VERSION ""

NS_ :

BS_:

BU_: PowertrainControlModule AtmosphericSensor SafetyRestraintSystem2 Aftertreatment_2_GasOutlet Aftertreatment_2_GasIntake DieselParticulateFilterControl Turbocharger SafetyRestraintSystem1 CabDisplay2 Aftertreatment_1_GasOutlet Aftertreatment_1_GasIntake OnBoardDataLogger OffBoardDiagnosticTool2 OffBoardDiagnosticTool1 FileServer ParkingBrakeController SeatController2 FanDriveController SteeringColumnUnit CommunicationUnitRadio CommunicationUnitSatellite CommunicationUnitCellular PropulsionBatteryCharger ChassisController2 ChassisController1 EngineValveControl AuxiliaryHeater2 AuxiliaryHeater1 ClutchUnit RampControl InformationSystem1 SuspensionSystemController2 OilSensor VehicleDynamicStability ExhaustEmissionController TransmissionDisplay2 TransmissionDisplay1 ClimateControl2 WaterPumpController RearAxleSteeringController LightingOperatorControl SeatController1 IgnitionController2 IgnitionController1 TirePressureController CabController2 CabController1 PneumaticSystemController SuspensionSystemController1 HydraulicPumpController EnduranceBrakingSystem RetarderExhaustEngine2 OnBoardDiagnosticUnit HeadwayController RetarderExhaustEngine1 CabDisplay1 ManagementComputer VirtualTerminal OffVehicleGateway PowerTakeOffFront HitchControl AuxiliaryValveControl BodyController TractorTrailerBridge1 StarterSystem ElectricalSystem VehicleSecurity VehicleNavigation AerodynamicControl ElectricalChargingSystem ClimateControl1 TripRecorder InstrumentCluster SuspensionDriveAxle2 SuspensionDriveAxle1 SuspensionSteerAxle SteeringController FuelSystem CruiseControl RetarderDriveline RetarderEngine BrakesDriveAxle2 BrakesDriveAxle1 BrakesSystemController BrakesSteerAxle AxleDrive2 AxleDrive1 AxleSteering PowerTakeOff ShiftConsoleSecondary ShiftConsolePrimary Transmission2 Transmission1 Engine2 Engine1

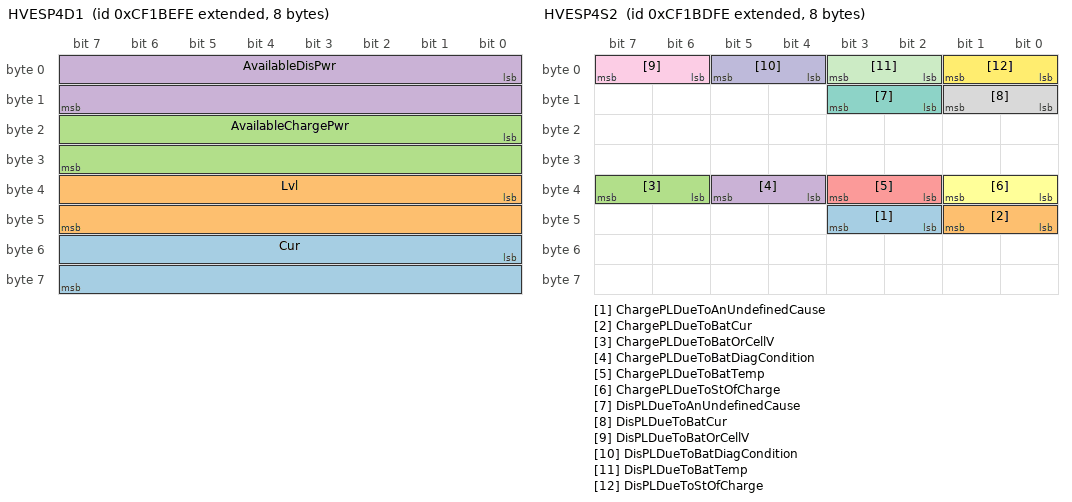
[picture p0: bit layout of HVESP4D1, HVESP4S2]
BO_ 2364653310 HVESP4D1: 8 Vector__XXX
 SG_ Cur : 48|16@1+ (0.05,-1600) [-1600|1612.75] "A" Vector__XXX
 SG_ Lvl : 32|16@1+ (0.05,0) [0|3212.75] "V" Vector__XXX
 SG_ AvailableChargePwr : 16|16@1+ (0.05,0) [0|3212.75] "kW" Vector__XXX
 SG_ AvailableDisPwr : 0|16@1+ (0.05,0) [0|3212.75] "kW" Vector__XXX

BO_ 2364653054 HVESP4S2: 8 Vector__XXX
 SG_ ChargePLDueToAnUndefinedCause : 42|2@1+ (1,0) [0|3] "" Vector__XXX
 SG_ ChargePLDueToBatCur : 40|2@1+ (1,0) [0|3] "" Vector__XXX
 SG_ ChargePLDueToBatOrCellV : 38|2@1+ (1,0) [0|3] "" Vector__XXX
 SG_ ChargePLDueToBatDiagCondition : 36|2@1+ (1,0) [0|3] "" Vector__XXX
 SG_ ChargePLDueToBatTemp : 34|2@1+ (1,0) [0|3] "" Vector__XXX
 SG_ ChargePLDueToStOfCharge : 32|2@1+ (1,0) [0|3] "" Vector__XXX
 SG_ DisPLDueToAnUndefinedCause : 10|2@1+ (1,0) [0|3] "" Vector__XXX
 SG_ DisPLDueToBatCur : 8|2@1+ (1,0) [0|3] "" Vector__XXX
 SG_ DisPLDueToBatOrCellV : 6|2@1+ (1,0) [0|3] "" Vector__XXX
 SG_ DisPLDueToBatDiagCondition : 4|2@1+ (1,0) [0|3] "" Vector__XXX
 SG_ DisPLDueToBatTemp : 2|2@1+ (1,0) [0|3] "" Vector__XXX
 SG_ DisPLDueToStOfCharge : 0|2@1+ (1,0) [0|3] "" Vector__XXX

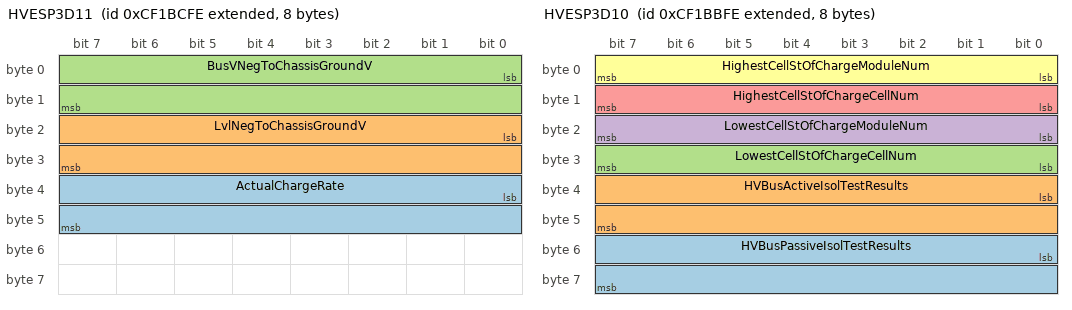
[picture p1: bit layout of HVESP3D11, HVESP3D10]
BO_ 2364652798 HVESP3D11: 8 Vector__XXX
 SG_ ActualChargeRate : 32|16@1+ (0.05,0) [0|3212.75] "kW" Vector__XXX
 SG_ LvlNegToChassisGroundV : 16|16@1+ (0.05,0) [0|3212.75] "V" Vector__XXX
 SG_ BusVNegToChassisGroundV : 0|16@1+ (0.05,0) [0|3212.75] "V" Vector__XXX

BO_ 2364652542 HVESP3D10: 8 Vector__XXX
 SG_ HVBusPassiveIsolTestResults : 48|16@1+ (0.1,0) [0|6425.5] "Ohm/V" Vector__XXX
 SG_ HVBusActiveIsolTestResults : 32|16@1+ (0.1,0) [0|6425.5] "Ohm/V" Vector__XXX
 SG_ LowestCellStOfChargeCellNum : 24|8@1+ (1,0) [0|250] "" Vector__XXX
 SG_ LowestCellStOfChargeModuleNum : 16|8@1+ (1,0) [0|250] "" Vector__XXX
 SG_ HighestCellStOfChargeCellNum : 8|8@1+ (1,0) [0|250] "" Vector__XXX
 SG_ HighestCellStOfChargeModuleNum : 0|8@1+ (1,0) [0|250] "" Vector__XXX

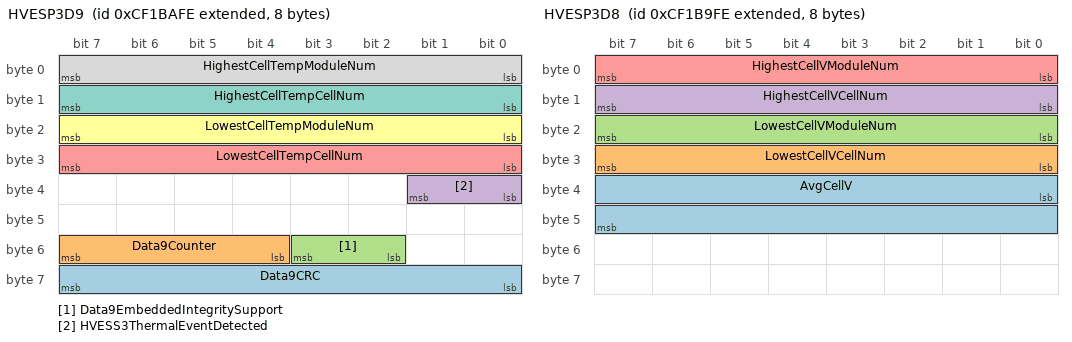
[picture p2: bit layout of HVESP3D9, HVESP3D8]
BO_ 2364652286 HVESP3D9: 8 Vector__XXX
 SG_ Data9CRC : 56|8@1+ (1,0) [0|255] "" Vector__XXX
 SG_ Data9Counter : 52|4@1+ (1,0) [0|15] "" Vector__XXX
 SG_ Data9EmbeddedIntegritySupport : 50|2@1+ (1,0) [0|3] "" Vector__XXX
 SG_ HVESS3ThermalEventDetected : 32|2@1+ (1,0) [0|3] "" Vector__XXX
 SG_ LowestCellTempCellNum : 24|8@1+ (1,0) [0|250] "" Vector__XXX
 SG_ LowestCellTempModuleNum : 16|8@1+ (1,0) [0|250] "" Vector__XXX
 SG_ HighestCellTempCellNum : 8|8@1+ (1,0) [0|250] "" Vector__XXX
 SG_ HighestCellTempModuleNum : 0|8@1+ (1,0) [0|250] "" Vector__XXX

BO_ 2364652030 HVESP3D8: 8 Vector__XXX
 SG_ AvgCellV : 32|16@1+ (0.001,0) [0|64.255] "V" Vector__XXX
 SG_ LowestCellVCellNum : 24|8@1+ (1,0) [0|250] "" Vector__XXX
 SG_ LowestCellVModuleNum : 16|8@1+ (1,0) [0|250] "" Vector__XXX
 SG_ HighestCellVCellNum : 8|8@1+ (1,0) [0|250] "" Vector__XXX
 SG_ HighestCellVModuleNum : 0|8@1+ (1,0) [0|250] "" Vector__XXX

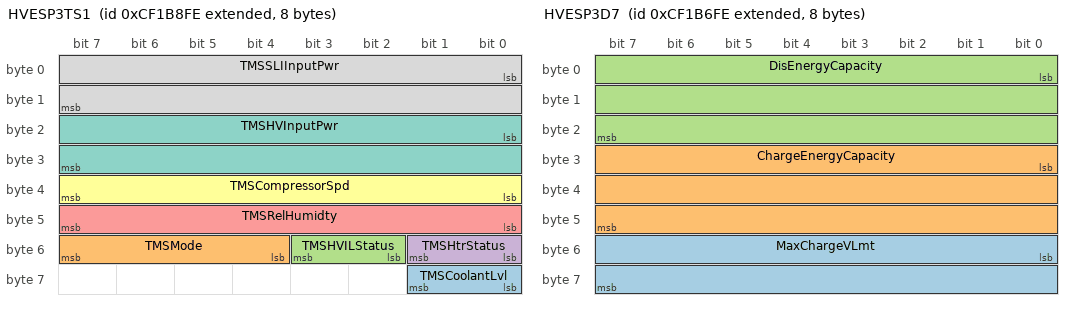
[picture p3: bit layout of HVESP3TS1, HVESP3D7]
BO_ 2364651774 HVESP3TS1: 8 Vector__XXX
 SG_ TMSCoolantLvl : 56|2@1+ (1,0) [0|3] "" Vector__XXX
 SG_ TMSMode : 52|4@1+ (1,0) [0|15] "" Vector__XXX
 SG_ TMSHVILStatus : 50|2@1+ (1,0) [0|3] "" Vector__XXX
 SG_ TMSHtrStatus : 48|2@1+ (1,0) [0|3] "" Vector__XXX
 SG_ TMSRelHumidty : 40|8@1+ (0.4,0) [0|100] "%" Vector__XXX
 SG_ TMSCompressorSpd : 32|8@1+ (32,0) [0|8000] "rpm" Vector__XXX
 SG_ TMSHVInputPwr : 16|16@1+ (0.5,0) [0|32127.5] "W" Vector__XXX
 SG_ TMSSLIInputPwr : 0|16@1+ (0.5,0) [0|32127.5] "W" Vector__XXX

BO_ 2364651518 HVESP3MS1: 8 Vector__XXX
 SG_ Module32OperationalStatus : 62|2@1+ (1,0) [0|3] "" Vector__XXX
 SG_ Module31OperationalStatus : 60|2@1+ (1,0) [0|3] "" Vector__XXX
 SG_ Module30OperationalStatus : 58|2@1+ (1,0) [0|3] "" Vector__XXX
 SG_ Module29OperationalStatus : 56|2@1+ (1,0) [0|3] "" Vector__XXX
 SG_ Module28OperationalStatus : 54|2@1+ (1,0) [0|3] "" Vector__XXX
 SG_ Module27OperationalStatus : 52|2@1+ (1,0) [0|3] "" Vector__XXX
 SG_ Module26OperationalStatus : 50|2@1+ (1,0) [0|3] "" Vector__XXX
 SG_ Module25OperationalStatus : 48|2@1+ (1,0) [0|3] "" Vector__XXX
 SG_ Module24OperationalStatus : 46|2@1+ (1,0) [0|3] "" Vector__XXX
 SG_ Module23OperationalStatus : 44|2@1+ (1,0) [0|3] "" Vector__XXX
 SG_ Module22OperationalStatus : 42|2@1+ (1,0) [0|3] "" Vector__XXX
 SG_ Module21OperationalStatus : 40|2@1+ (1,0) [0|3] "" Vector__XXX
 SG_ Module20OperationalStatus : 38|2@1+ (1,0) [0|3] "" Vector__XXX
 SG_ Module19OperationalStatus : 36|2@1+ (1,0) [0|3] "" Vector__XXX
 SG_ Module18OperationalStatus : 34|2@1+ (1,0) [0|3] "" Vector__XXX
 SG_ Module17OperationalStatus : 32|2@1+ (1,0) [0|3] "" Vector__XXX
 SG_ Module16OperationalStatus : 30|2@1+ (1,0) [0|3] "" Vector__XXX
 SG_ Module15OperationalStatus : 28|2@1+ (1,0) [0|3] "" Vector__XXX
 SG_ Module14OperationalStatus : 26|2@1+ (1,0) [0|3] "" Vector__XXX
 SG_ Module13OperationalStatus : 24|2@1+ (1,0) [0|3] "" Vector__XXX
 SG_ Module12OperationalStatus : 22|2@1+ (1,0) [0|3] "" Vector__XXX
 SG_ Module11OperationalStatus : 20|2@1+ (1,0) [0|3] "" Vector__XXX
 SG_ Module10OperationalStatus : 18|2@1+ (1,0) [0|3] "" Vector__XXX
 SG_ Module9OperationalStatus : 16|2@1+ (1,0) [0|3] "" Vector__XXX
 SG_ Module8OperationalStatus : 14|2@1+ (1,0) [0|3] "" Vector__XXX
 SG_ Module7OperationalStatus : 12|2@1+ (1,0) [0|3] "" Vector__XXX
 SG_ Module6OperationalStatus : 10|2@1+ (1,0) [0|3] "" Vector__XXX
 SG_ Module5OperationalStatus : 8|2@1+ (1,0) [0|3] "" Vector__XXX
 SG_ Module4OperationalStatus : 6|2@1+ (1,0) [0|3] "" Vector__XXX
 SG_ Module3OperationalStatus : 4|2@1+ (1,0) [0|3] "" Vector__XXX
 SG_ Module2OperationalStatus : 2|2@1+ (1,0) [0|3] "" Vector__XXX
 SG_ Module1OperationalStatus : 0|2@1+ (1,0) [0|3] "" Vector__XXX

BO_ 2364651262 HVESP3D7: 8 Vector__XXX
 SG_ MaxChargeVLmt : 48|16@1+ (0.05,0) [0|3212.75] "V" Vector__XXX
 SG_ ChargeEnergyCapacity : 24|24@1+ (0.001,0) [0|16449.535] "kWh" Vector__XXX
 SG_ DisEnergyCapacity : 0|24@1+ (0.001,0) [0|16449.535] "kWh" Vector__XXX

BO_ 2364651006 HVESP3S1: 8 Vector__XXX
 SG_ Status1CRC : 56|8@1+ (1,0) [0|255] "" Vector__XXX
 SG_ Status1Counter : 52|4@1+ (1,0) [0|15] "" Vector__XXX
 SG_ OperationalStatus : 44|4@1+ (1,0) [0|15] "" Vector__XXX
 SG_ HVBusConnectionStatus : 40|4@1+ (1,0) [0|15] "" Vector__XXX
 SG_ InternalChargerStatus : 32|2@1+ (1,0) [0|3] "" Vector__XXX
 SG_ CellBalancingActive : 30|2@1+ (1,0) [0|3] "" Vector__XXX
 SG_ CellBalanceStatus : 28|2@1+ (1,0) [0|3] "" Vector__XXX
 SG_ StOfChargeStatus : 24|4@1+ (1,0) [0|15] "" Vector__XXX
 SG_ InertiaSwStatus : 22|2@1+ (1,0) [0|3] "" Vector__XXX
 SG_ HVILStatus : 20|2@1+ (1,0) [0|3] "" Vector__XXX
 SG_ HVBusPassiveIsolTestStatus : 16|4@1+ (1,0) [0|15] "" Vector__XXX
 SG_ HVBusActiveIsolTestStatus : 12|4@1+ (1,0) [0|15] "" Vector__XXX
 SG_ CenterOfPackContactorSt : 10|2@1+ (1,0) [0|3] "" Vector__XXX
 SG_ HVBusPreChargeRelaySt : 8|2@1+ (1,0) [0|3] "" Vector__XXX
 SG_ HVBusDisconnectForewarning : 4|4@1+ (1,0) [0|15] "" Vector__XXX
 SG_ HVBusContactorSt11308 : 2|2@1+ (1,0) [0|3] "" Vector__XXX
 SG_ HVBusContactorSt : 0|2@1+ (1,0) [0|3] "" Vector__XXX

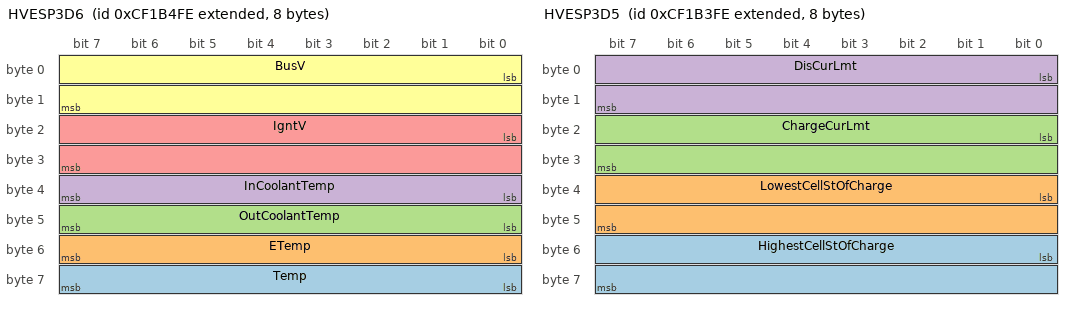
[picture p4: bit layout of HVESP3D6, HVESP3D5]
BO_ 2364650750 HVESP3D6: 8 Vector__XXX
 SG_ Temp : 56|8@1+ (1,-40) [-40|210] "°C" Vector__XXX
 SG_ ETemp : 48|8@1+ (1,-40) [-40|210] "°C" Vector__XXX
 SG_ OutCoolantTemp : 40|8@1+ (1,-40) [-40|210] "°C" Vector__XXX
 SG_ InCoolantTemp : 32|8@1+ (1,-40) [-40|210] "°C" Vector__XXX
 SG_ IgntV : 16|16@1+ (0.01,0) [0|642.55] "V" Vector__XXX
 SG_ BusV : 0|16@1+ (0.05,0) [0|3212.75] "V" Vector__XXX

BO_ 2364650494 HVESP3D5: 8 Vector__XXX
 SG_ HighestCellStOfCharge : 48|16@1+ (0.0015625,0) [0|100.3984375] "%" Vector__XXX
 SG_ LowestCellStOfCharge : 32|16@1+ (0.0015625,0) [0|100.3984375] "%" Vector__XXX
 SG_ ChargeCurLmt : 16|16@1+ (0.05,-1600) [0|1612.75] "A" Vector__XXX
 SG_ DisCurLmt : 0|16@1+ (0.05,-1600) [-1600|0] "A" Vector__XXX

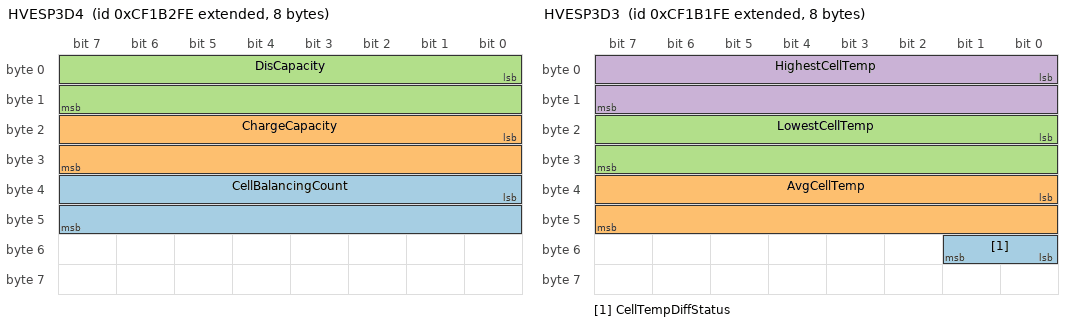
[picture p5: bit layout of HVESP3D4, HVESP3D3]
BO_ 2364650238 HVESP3D4: 8 Vector__XXX
 SG_ CellBalancingCount : 32|16@1+ (1,0) [0|64255] "" Vector__XXX
 SG_ ChargeCapacity : 16|16@1+ (0.01,0) [0|642.55] "Ah" Vector__XXX
 SG_ DisCapacity : 0|16@1+ (0.01,0) [0|642.55] "Ah" Vector__XXX

BO_ 2364649982 HVESP3D3: 8 Vector__XXX
 SG_ CellTempDiffStatus : 48|2@1+ (1,0) [0|3] "" Vector__XXX
 SG_ AvgCellTemp : 32|16@1+ (0.03125,-273) [-273|1734.96875] "°C" Vector__XXX
 SG_ LowestCellTemp : 16|16@1+ (0.03125,-273) [-273|1734.96875] "°C" Vector__XXX
 SG_ HighestCellTemp : 0|16@1+ (0.03125,-273) [-273|1734.96875] "°C" Vector__XXX

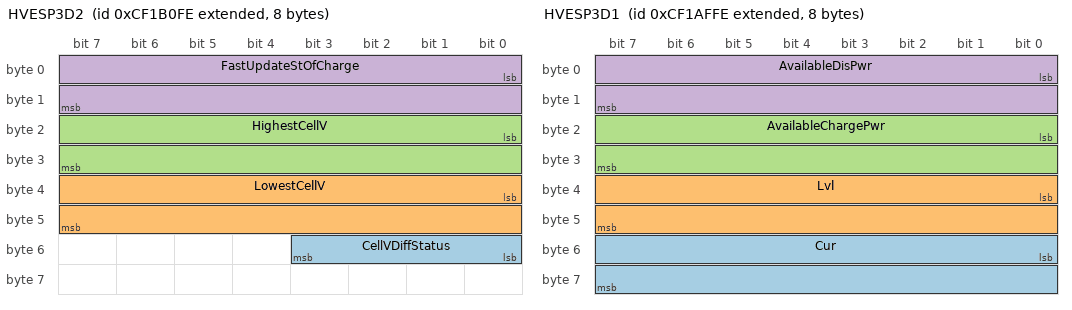
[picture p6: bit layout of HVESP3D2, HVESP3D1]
BO_ 2364649726 HVESP3D2: 8 Vector__XXX
 SG_ CellVDiffStatus : 48|4@1+ (1,0) [0|15] "" Vector__XXX
 SG_ LowestCellV : 32|16@1+ (0.001,0) [0|64.255] "V" Vector__XXX
 SG_ HighestCellV : 16|16@1+ (0.001,0) [0|64.255] "V" Vector__XXX
 SG_ FastUpdateStOfCharge : 0|16@1+ (0.0015625,0) [0|100.3984375] "%" Vector__XXX

BO_ 2364649470 HVESP3D1: 8 Vector__XXX
 SG_ Cur : 48|16@1+ (0.05,-1600) [-1600|1612.75] "A" Vector__XXX
 SG_ Lvl : 32|16@1+ (0.05,0) [0|3212.75] "V" Vector__XXX
 SG_ AvailableChargePwr : 16|16@1+ (0.05,0) [0|3212.75] "kW" Vector__XXX
 SG_ AvailableDisPwr : 0|16@1+ (0.05,0) [0|3212.75] "kW" Vector__XXX

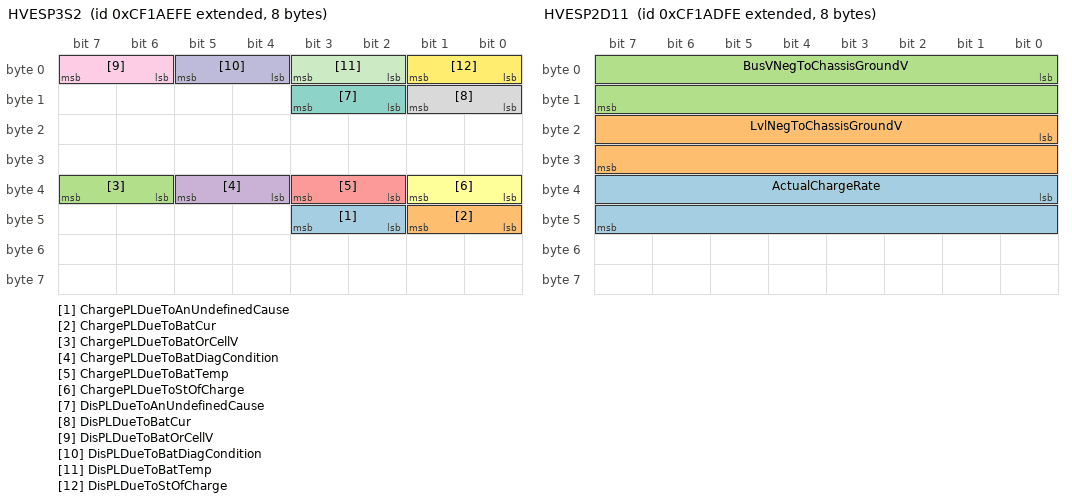
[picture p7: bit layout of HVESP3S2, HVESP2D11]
BO_ 2364649214 HVESP3S2: 8 Vector__XXX
 SG_ ChargePLDueToAnUndefinedCause : 42|2@1+ (1,0) [0|3] "" Vector__XXX
 SG_ ChargePLDueToBatCur : 40|2@1+ (1,0) [0|3] "" Vector__XXX
 SG_ ChargePLDueToBatOrCellV : 38|2@1+ (1,0) [0|3] "" Vector__XXX
 SG_ ChargePLDueToBatDiagCondition : 36|2@1+ (1,0) [0|3] "" Vector__XXX
 SG_ ChargePLDueToBatTemp : 34|2@1+ (1,0) [0|3] "" Vector__XXX
 SG_ ChargePLDueToStOfCharge : 32|2@1+ (1,0) [0|3] "" Vector__XXX
 SG_ DisPLDueToAnUndefinedCause : 10|2@1+ (1,0) [0|3] "" Vector__XXX
 SG_ DisPLDueToBatCur : 8|2@1+ (1,0) [0|3] "" Vector__XXX
 SG_ DisPLDueToBatOrCellV : 6|2@1+ (1,0) [0|3] "" Vector__XXX
 SG_ DisPLDueToBatDiagCondition : 4|2@1+ (1,0) [0|3] "" Vector__XXX
 SG_ DisPLDueToBatTemp : 2|2@1+ (1,0) [0|3] "" Vector__XXX
 SG_ DisPLDueToStOfCharge : 0|2@1+ (1,0) [0|3] "" Vector__XXX

BO_ 2364648958 HVESP2D11: 8 Vector__XXX
 SG_ ActualChargeRate : 32|16@1+ (0.05,0) [0|3212.75] "kW" Vector__XXX
 SG_ LvlNegToChassisGroundV : 16|16@1+ (0.05,0) [0|3212.75] "V" Vector__XXX
 SG_ BusVNegToChassisGroundV : 0|16@1+ (0.05,0) [0|3212.75] "V" Vector__XXX

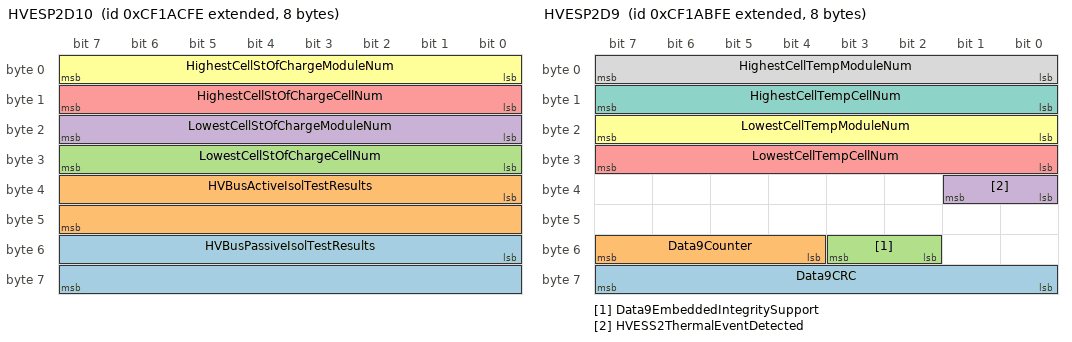
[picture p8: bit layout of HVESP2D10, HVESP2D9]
BO_ 2364648702 HVESP2D10: 8 Vector__XXX
 SG_ HVBusPassiveIsolTestResults : 48|16@1+ (0.1,0) [0|6425.5] "Ohm/V" Vector__XXX
 SG_ HVBusActiveIsolTestResults : 32|16@1+ (0.1,0) [0|6425.5] "Ohm/V" Vector__XXX
 SG_ LowestCellStOfChargeCellNum : 24|8@1+ (1,0) [0|250] "" Vector__XXX
 SG_ LowestCellStOfChargeModuleNum : 16|8@1+ (1,0) [0|250] "" Vector__XXX
 SG_ HighestCellStOfChargeCellNum : 8|8@1+ (1,0) [0|250] "" Vector__XXX
 SG_ HighestCellStOfChargeModuleNum : 0|8@1+ (1,0) [0|250] "" Vector__XXX

BO_ 2364648446 HVESP2D9: 8 Vector__XXX
 SG_ Data9CRC : 56|8@1+ (1,0) [0|255] "" Vector__XXX
 SG_ Data9Counter : 52|4@1+ (1,0) [0|15] "" Vector__XXX
 SG_ Data9EmbeddedIntegritySupport : 50|2@1+ (1,0) [0|3] "" Vector__XXX
 SG_ HVESS2ThermalEventDetected : 32|2@1+ (1,0) [0|3] "" Vector__XXX
 SG_ LowestCellTempCellNum : 24|8@1+ (1,0) [0|250] "" Vector__XXX
 SG_ LowestCellTempModuleNum : 16|8@1+ (1,0) [0|250] "" Vector__XXX
 SG_ HighestCellTempCellNum : 8|8@1+ (1,0) [0|250] "" Vector__XXX
 SG_ HighestCellTempModuleNum : 0|8@1+ (1,0) [0|250] "" Vector__XXX

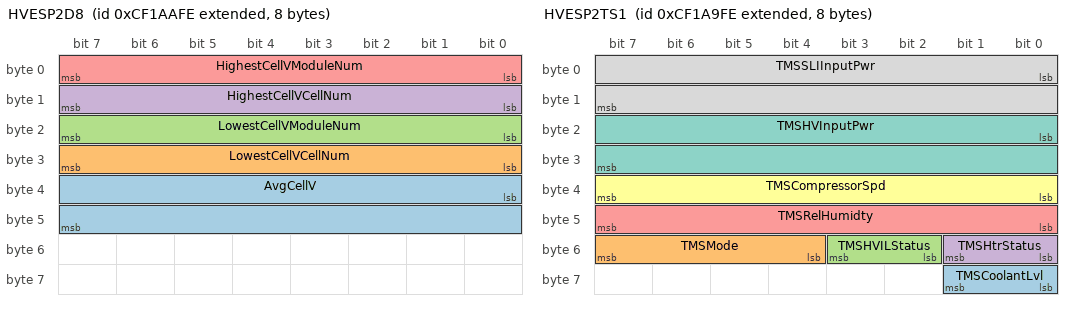
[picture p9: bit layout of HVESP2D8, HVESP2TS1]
BO_ 2364648190 HVESP2D8: 8 Vector__XXX
 SG_ AvgCellV : 32|16@1+ (0.001,0) [0|64.255] "V" Vector__XXX
 SG_ LowestCellVCellNum : 24|8@1+ (1,0) [0|250] "" Vector__XXX
 SG_ LowestCellVModuleNum : 16|8@1+ (1,0) [0|250] "" Vector__XXX
 SG_ HighestCellVCellNum : 8|8@1+ (1,0) [0|250] "" Vector__XXX
 SG_ HighestCellVModuleNum : 0|8@1+ (1,0) [0|250] "" Vector__XXX

BO_ 2364647934 HVESP2TS1: 8 Vector__XXX
 SG_ TMSCoolantLvl : 56|2@1+ (1,0) [0|3] "" Vector__XXX
 SG_ TMSMode : 52|4@1+ (1,0) [0|15] "" Vector__XXX
 SG_ TMSHVILStatus : 50|2@1+ (1,0) [0|3] "" Vector__XXX
 SG_ TMSHtrStatus : 48|2@1+ (1,0) [0|3] "" Vector__XXX
 SG_ TMSRelHumidty : 40|8@1+ (0.4,0) [0|100] "%" Vector__XXX
 SG_ TMSCompressorSpd : 32|8@1+ (32,0) [0|8000] "rpm" Vector__XXX
 SG_ TMSHVInputPwr : 16|16@1+ (0.5,0) [0|32127.5] "W" Vector__XXX
 SG_ TMSSLIInputPwr : 0|16@1+ (0.5,0) [0|32127.5] "W" Vector__XXX

BO_ 2364647678 HVESP2MS1: 8 Vector__XXX
 SG_ Module32OperationalStatus : 62|2@1+ (1,0) [0|3] "" Vector__XXX
 SG_ Module31OperationalStatus : 60|2@1+ (1,0) [0|3] "" Vector__XXX
 SG_ Module30OperationalStatus : 58|2@1+ (1,0) [0|3] "" Vector__XXX
 SG_ Module29OperationalStatus : 56|2@1+ (1,0) [0|3] "" Vector__XXX
 SG_ Module28OperationalStatus : 54|2@1+ (1,0) [0|3] "" Vector__XXX
 SG_ Module27OperationalStatus : 52|2@1+ (1,0) [0|3] "" Vector__XXX
 SG_ Module26OperationalStatus : 50|2@1+ (1,0) [0|3] "" Vector__XXX
 SG_ Module25OperationalStatus : 48|2@1+ (1,0) [0|3] "" Vector__XXX
 SG_ Module24OperationalStatus : 46|2@1+ (1,0) [0|3] "" Vector__XXX
 SG_ Module23OperationalStatus : 44|2@1+ (1,0) [0|3] "" Vector__XXX
 SG_ Module22OperationalStatus : 42|2@1+ (1,0) [0|3] "" Vector__XXX
 SG_ Module21OperationalStatus : 40|2@1+ (1,0) [0|3] "" Vector__XXX
 SG_ Module20OperationalStatus : 38|2@1+ (1,0) [0|3] "" Vector__XXX
 SG_ Module19OperationalStatus : 36|2@1+ (1,0) [0|3] "" Vector__XXX
 SG_ Module18OperationalStatus : 34|2@1+ (1,0) [0|3] "" Vector__XXX
 SG_ Module17OperationalStatus : 32|2@1+ (1,0) [0|3] "" Vector__XXX
 SG_ Module16OperationalStatus : 30|2@1+ (1,0) [0|3] "" Vector__XXX
 SG_ Module15OperationalStatus : 28|2@1+ (1,0) [0|3] "" Vector__XXX
 SG_ Module14OperationalStatus : 26|2@1+ (1,0) [0|3] "" Vector__XXX
 SG_ Module13OperationalStatus : 24|2@1+ (1,0) [0|3] "" Vector__XXX
 SG_ Module12OperationalStatus : 22|2@1+ (1,0) [0|3] "" Vector__XXX
 SG_ Module11OperationalStatus : 20|2@1+ (1,0) [0|3] "" Vector__XXX
 SG_ Module10OperationalStatus : 18|2@1+ (1,0) [0|3] "" Vector__XXX
 SG_ Module9OperationalStatus : 16|2@1+ (1,0) [0|3] "" Vector__XXX
 SG_ Module8OperationalStatus : 14|2@1+ (1,0) [0|3] "" Vector__XXX
 SG_ Module7OperationalStatus : 12|2@1+ (1,0) [0|3] "" Vector__XXX
 SG_ Module6OperationalStatus : 10|2@1+ (1,0) [0|3] "" Vector__XXX
 SG_ Module5OperationalStatus : 8|2@1+ (1,0) [0|3] "" Vector__XXX
 SG_ Module4OperationalStatus : 6|2@1+ (1,0) [0|3] "" Vector__XXX
 SG_ Module3OperationalStatus : 4|2@1+ (1,0) [0|3] "" Vector__XXX
 SG_ Module2OperationalStatus : 2|2@1+ (1,0) [0|3] "" Vector__XXX
 SG_ Module1OperationalStatus : 0|2@1+ (1,0) [0|3] "" Vector__XXX

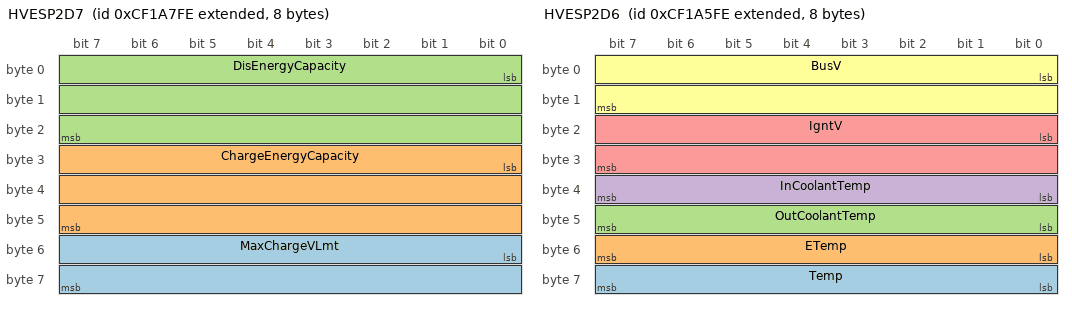
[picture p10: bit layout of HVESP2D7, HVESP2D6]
BO_ 2364647422 HVESP2D7: 8 Vector__XXX
 SG_ MaxChargeVLmt : 48|16@1+ (0.05,0) [0|3212.75] "V" Vector__XXX
 SG_ ChargeEnergyCapacity : 24|24@1+ (0.001,0) [0|16449.535] "kWh" Vector__XXX
 SG_ DisEnergyCapacity : 0|24@1+ (0.001,0) [0|16449.535] "kWh" Vector__XXX

BO_ 2364647166 HVESP2S1: 8 Vector__XXX
 SG_ Status1CRC : 56|8@1+ (1,0) [0|255] "" Vector__XXX
 SG_ Status1Counter : 52|4@1+ (1,0) [0|15] "" Vector__XXX
 SG_ OperationalStatus : 44|4@1+ (1,0) [0|15] "" Vector__XXX
 SG_ HVBusConnectionStatus : 40|4@1+ (1,0) [0|15] "" Vector__XXX
 SG_ InternalChargerStatus : 32|2@1+ (1,0) [0|3] "" Vector__XXX
 SG_ CellBalancingActive : 30|2@1+ (1,0) [0|3] "" Vector__XXX
 SG_ CellBalanceStatus : 28|2@1+ (1,0) [0|3] "" Vector__XXX
 SG_ StOfChargeStatus : 24|4@1+ (1,0) [0|15] "" Vector__XXX
 SG_ InertiaSwStatus : 22|2@1+ (1,0) [0|3] "" Vector__XXX
 SG_ HVILStatus : 20|2@1+ (1,0) [0|3] "" Vector__XXX
 SG_ HVBusPassiveIsolTestStatus : 16|4@1+ (1,0) [0|15] "" Vector__XXX
 SG_ HVBusActiveIsolTestStatus : 12|4@1+ (1,0) [0|15] "" Vector__XXX
 SG_ CenterOfPackContactorSt : 10|2@1+ (1,0) [0|3] "" Vector__XXX
 SG_ HVBusPreChargeRelaySt : 8|2@1+ (1,0) [0|3] "" Vector__XXX
 SG_ HVBusDisconnectForewarning : 4|4@1+ (1,0) [0|15] "" Vector__XXX
 SG_ HVBusContactorSt11192 : 2|2@1+ (1,0) [0|3] "" Vector__XXX
 SG_ HVBusContactorSt : 0|2@1+ (1,0) [0|3] "" Vector__XXX

BO_ 2364646910 HVESP2D6: 8 Vector__XXX
 SG_ Temp : 56|8@1+ (1,-40) [-40|210] "°C" Vector__XXX
 SG_ ETemp : 48|8@1+ (1,-40) [-40|210] "°C" Vector__XXX
 SG_ OutCoolantTemp : 40|8@1+ (1,-40) [-40|210] "°C" Vector__XXX
 SG_ InCoolantTemp : 32|8@1+ (1,-40) [-40|210] "°C" Vector__XXX
 SG_ IgntV : 16|16@1+ (0.01,0) [0|642.55] "V" Vector__XXX
 SG_ BusV : 0|16@1+ (0.05,0) [0|3212.75] "V" Vector__XXX

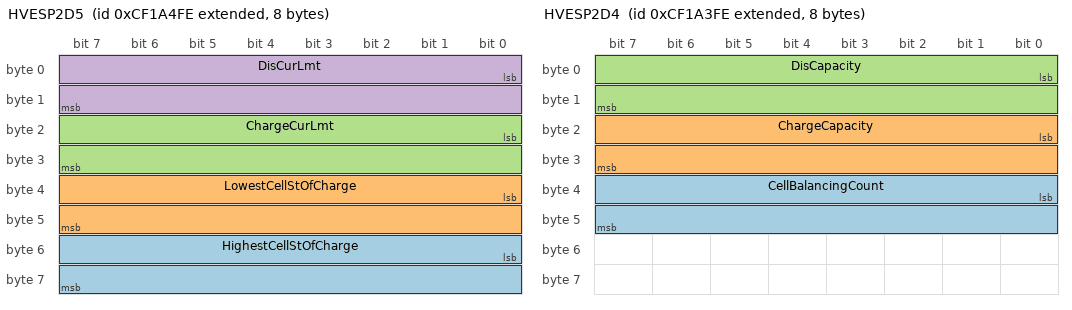
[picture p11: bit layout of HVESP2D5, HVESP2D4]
BO_ 2364646654 HVESP2D5: 8 Vector__XXX
 SG_ HighestCellStOfCharge : 48|16@1+ (0.0015625,0) [0|100.3984375] "%" Vector__XXX
 SG_ LowestCellStOfCharge : 32|16@1+ (0.0015625,0) [0|100.3984375] "%" Vector__XXX
 SG_ ChargeCurLmt : 16|16@1+ (0.05,-1600) [0|1612.75] "A" Vector__XXX
 SG_ DisCurLmt : 0|16@1+ (0.05,-1600) [-1600|0] "A" Vector__XXX

BO_ 2364646398 HVESP2D4: 8 Vector__XXX
 SG_ CellBalancingCount : 32|16@1+ (1,0) [0|64255] "" Vector__XXX
 SG_ ChargeCapacity : 16|16@1+ (0.01,0) [0|642.55] "Ah" Vector__XXX
 SG_ DisCapacity : 0|16@1+ (0.01,0) [0|642.55] "Ah" Vector__XXX

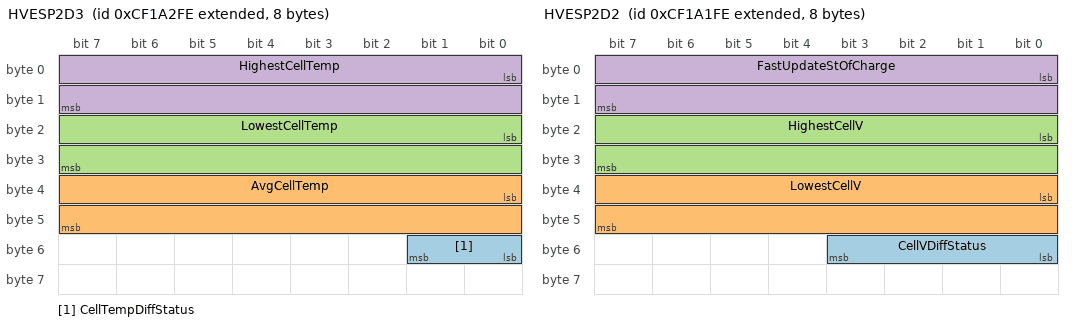
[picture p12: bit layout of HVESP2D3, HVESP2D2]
BO_ 2364646142 HVESP2D3: 8 Vector__XXX
 SG_ CellTempDiffStatus : 48|2@1+ (1,0) [0|3] "" Vector__XXX
 SG_ AvgCellTemp : 32|16@1+ (0.03125,-273) [-273|1734.96875] "°C" Vector__XXX
 SG_ LowestCellTemp : 16|16@1+ (0.03125,-273) [-273|1734.96875] "°C" Vector__XXX
 SG_ HighestCellTemp : 0|16@1+ (0.03125,-273) [-273|1734.96875] "°C" Vector__XXX

BO_ 2364645886 HVESP2D2: 8 Vector__XXX
 SG_ CellVDiffStatus : 48|4@1+ (1,0) [0|15] "" Vector__XXX
 SG_ LowestCellV : 32|16@1+ (0.001,0) [0|64.255] "V" Vector__XXX
 SG_ HighestCellV : 16|16@1+ (0.001,0) [0|64.255] "V" Vector__XXX
 SG_ FastUpdateStOfCharge : 0|16@1+ (0.0015625,0) [0|100.3984375] "%" Vector__XXX

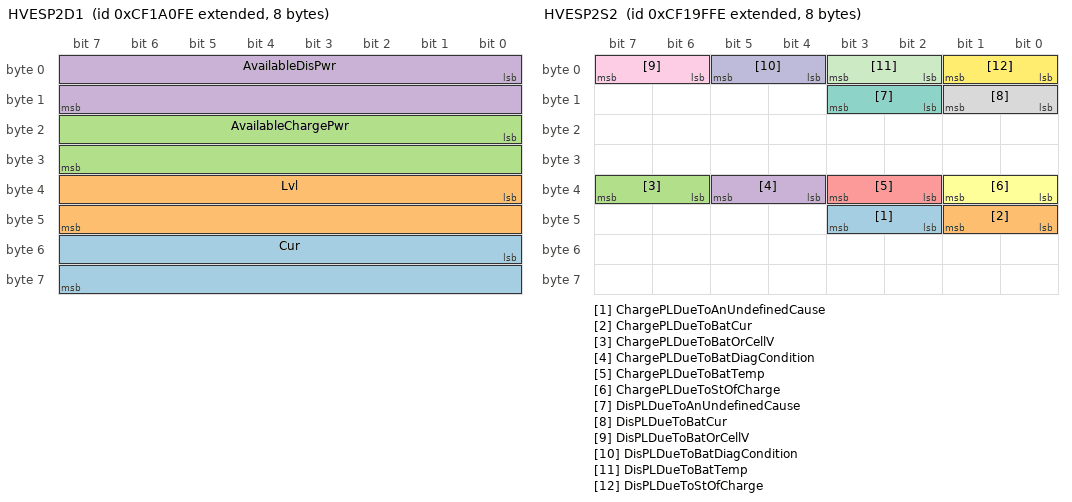
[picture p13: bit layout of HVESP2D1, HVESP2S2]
BO_ 2364645630 HVESP2D1: 8 Vector__XXX
 SG_ Cur : 48|16@1+ (0.05,-1600) [-1600|1612.75] "A" Vector__XXX
 SG_ Lvl : 32|16@1+ (0.05,0) [0|3212.75] "V" Vector__XXX
 SG_ AvailableChargePwr : 16|16@1+ (0.05,0) [0|3212.75] "kW" Vector__XXX
 SG_ AvailableDisPwr : 0|16@1+ (0.05,0) [0|3212.75] "kW" Vector__XXX

BO_ 2364645374 HVESP2S2: 8 Vector__XXX
 SG_ ChargePLDueToAnUndefinedCause : 42|2@1+ (1,0) [0|3] "" Vector__XXX
 SG_ ChargePLDueToBatCur : 40|2@1+ (1,0) [0|3] "" Vector__XXX
 SG_ ChargePLDueToBatOrCellV : 38|2@1+ (1,0) [0|3] "" Vector__XXX
 SG_ ChargePLDueToBatDiagCondition : 36|2@1+ (1,0) [0|3] "" Vector__XXX
 SG_ ChargePLDueToBatTemp : 34|2@1+ (1,0) [0|3] "" Vector__XXX
 SG_ ChargePLDueToStOfCharge : 32|2@1+ (1,0) [0|3] "" Vector__XXX
 SG_ DisPLDueToAnUndefinedCause : 10|2@1+ (1,0) [0|3] "" Vector__XXX
 SG_ DisPLDueToBatCur : 8|2@1+ (1,0) [0|3] "" Vector__XXX
 SG_ DisPLDueToBatOrCellV : 6|2@1+ (1,0) [0|3] "" Vector__XXX
 SG_ DisPLDueToBatDiagCondition : 4|2@1+ (1,0) [0|3] "" Vector__XXX
 SG_ DisPLDueToBatTemp : 2|2@1+ (1,0) [0|3] "" Vector__XXX
 SG_ DisPLDueToStOfCharge : 0|2@1+ (1,0) [0|3] "" Vector__XXX

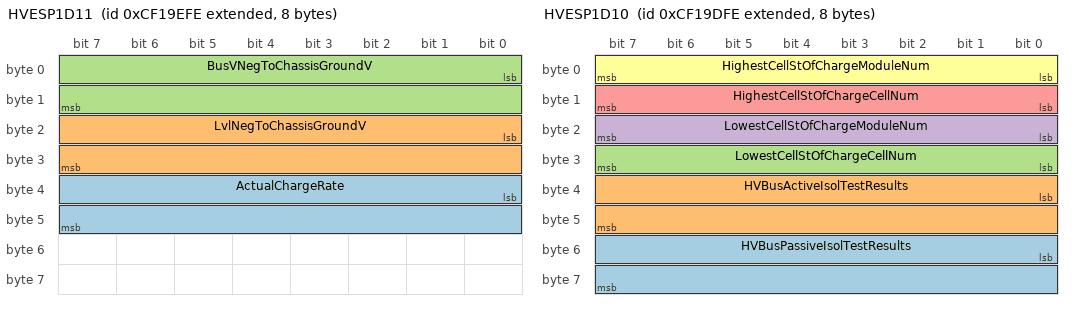
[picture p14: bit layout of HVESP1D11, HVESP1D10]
BO_ 2364645118 HVESP1D11: 8 Vector__XXX
 SG_ ActualChargeRate : 32|16@1+ (0.05,0) [0|3212.75] "kW" Vector__XXX
 SG_ LvlNegToChassisGroundV : 16|16@1+ (0.05,0) [0|3212.75] "V" Vector__XXX
 SG_ BusVNegToChassisGroundV : 0|16@1+ (0.05,0) [0|3212.75] "V" Vector__XXX

BO_ 2364644862 HVESP1D10: 8 Vector__XXX
 SG_ HVBusPassiveIsolTestResults : 48|16@1+ (0.1,0) [0|6425.5] "Ohm/V" Vector__XXX
 SG_ HVBusActiveIsolTestResults : 32|16@1+ (0.1,0) [0|6425.5] "Ohm/V" Vector__XXX
 SG_ LowestCellStOfChargeCellNum : 24|8@1+ (1,0) [0|250] "" Vector__XXX
 SG_ LowestCellStOfChargeModuleNum : 16|8@1+ (1,0) [0|250] "" Vector__XXX
 SG_ HighestCellStOfChargeCellNum : 8|8@1+ (1,0) [0|250] "" Vector__XXX
 SG_ HighestCellStOfChargeModuleNum : 0|8@1+ (1,0) [0|250] "" Vector__XXX

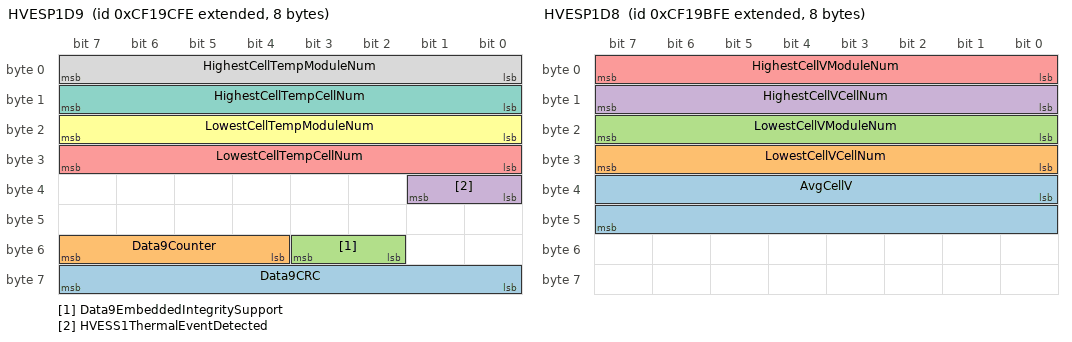
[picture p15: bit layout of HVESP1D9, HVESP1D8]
BO_ 2364644606 HVESP1D9: 8 Vector__XXX
 SG_ Data9CRC : 56|8@1+ (1,0) [0|255] "" Vector__XXX
 SG_ Data9Counter : 52|4@1+ (1,0) [0|15] "" Vector__XXX
 SG_ Data9EmbeddedIntegritySupport : 50|2@1+ (1,0) [0|3] "" Vector__XXX
 SG_ HVESS1ThermalEventDetected : 32|2@1+ (1,0) [0|3] "" Vector__XXX
 SG_ LowestCellTempCellNum : 24|8@1+ (1,0) [0|250] "" Vector__XXX
 SG_ LowestCellTempModuleNum : 16|8@1+ (1,0) [0|250] "" Vector__XXX
 SG_ HighestCellTempCellNum : 8|8@1+ (1,0) [0|250] "" Vector__XXX
 SG_ HighestCellTempModuleNum : 0|8@1+ (1,0) [0|250] "" Vector__XXX

BO_ 2364644350 HVESP1D8: 8 Vector__XXX
 SG_ AvgCellV : 32|16@1+ (0.001,0) [0|64.255] "V" Vector__XXX
 SG_ LowestCellVCellNum : 24|8@1+ (1,0) [0|250] "" Vector__XXX
 SG_ LowestCellVModuleNum : 16|8@1+ (1,0) [0|250] "" Vector__XXX
 SG_ HighestCellVCellNum : 8|8@1+ (1,0) [0|250] "" Vector__XXX
 SG_ HighestCellVModuleNum : 0|8@1+ (1,0) [0|250] "" Vector__XXX

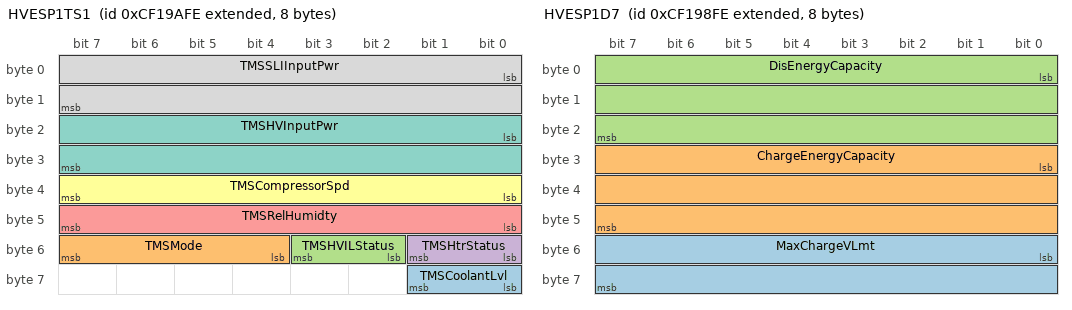
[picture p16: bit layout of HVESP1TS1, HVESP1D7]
BO_ 2364644094 HVESP1TS1: 8 Vector__XXX
 SG_ TMSCoolantLvl : 56|2@1+ (1,0) [0|3] "" Vector__XXX
 SG_ TMSMode : 52|4@1+ (1,0) [0|15] "" Vector__XXX
 SG_ TMSHVILStatus : 50|2@1+ (1,0) [0|3] "" Vector__XXX
 SG_ TMSHtrStatus : 48|2@1+ (1,0) [0|3] "" Vector__XXX
 SG_ TMSRelHumidty : 40|8@1+ (0.4,0) [0|100] "%" Vector__XXX
 SG_ TMSCompressorSpd : 32|8@1+ (32,0) [0|8000] "rpm" Vector__XXX
 SG_ TMSHVInputPwr : 16|16@1+ (0.5,0) [0|32127.5] "W" Vector__XXX
 SG_ TMSSLIInputPwr : 0|16@1+ (0.5,0) [0|32127.5] "W" Vector__XXX

BO_ 2364643838 HVESP1MS1: 8 Vector__XXX
 SG_ Module32OperationalStatus : 62|2@1+ (1,0) [0|3] "" Vector__XXX
 SG_ Module31OperationalStatus : 60|2@1+ (1,0) [0|3] "" Vector__XXX
 SG_ Module30OperationalStatus : 58|2@1+ (1,0) [0|3] "" Vector__XXX
 SG_ Module29OperationalStatus : 56|2@1+ (1,0) [0|3] "" Vector__XXX
 SG_ Module28OperationalStatus : 54|2@1+ (1,0) [0|3] "" Vector__XXX
 SG_ Module27OperationalStatus : 52|2@1+ (1,0) [0|3] "" Vector__XXX
 SG_ Module26OperationalStatus : 50|2@1+ (1,0) [0|3] "" Vector__XXX
 SG_ Module25OperationalStatus : 48|2@1+ (1,0) [0|3] "" Vector__XXX
 SG_ Module24OperationalStatus : 46|2@1+ (1,0) [0|3] "" Vector__XXX
 SG_ Module23OperationalStatus : 44|2@1+ (1,0) [0|3] "" Vector__XXX
 SG_ Module22OperationalStatus : 42|2@1+ (1,0) [0|3] "" Vector__XXX
 SG_ Module21OperationalStatus : 40|2@1+ (1,0) [0|3] "" Vector__XXX
 SG_ Module20OperationalStatus : 38|2@1+ (1,0) [0|3] "" Vector__XXX
 SG_ Module19OperationalStatus : 36|2@1+ (1,0) [0|3] "" Vector__XXX
 SG_ Module18OperationalStatus : 34|2@1+ (1,0) [0|3] "" Vector__XXX
 SG_ Module17OperationalStatus : 32|2@1+ (1,0) [0|3] "" Vector__XXX
 SG_ Module16OperationalStatus : 30|2@1+ (1,0) [0|3] "" Vector__XXX
 SG_ Module15OperationalStatus : 28|2@1+ (1,0) [0|3] "" Vector__XXX
 SG_ Module14OperationalStatus : 26|2@1+ (1,0) [0|3] "" Vector__XXX
 SG_ Module13OperationalStatus : 24|2@1+ (1,0) [0|3] "" Vector__XXX
 SG_ Module12OperationalStatus : 22|2@1+ (1,0) [0|3] "" Vector__XXX
 SG_ Module11OperationalStatus : 20|2@1+ (1,0) [0|3] "" Vector__XXX
 SG_ Module10OperationalStatus : 18|2@1+ (1,0) [0|3] "" Vector__XXX
 SG_ Module9OperationalStatus : 16|2@1+ (1,0) [0|3] "" Vector__XXX
 SG_ Module8OperationalStatus : 14|2@1+ (1,0) [0|3] "" Vector__XXX
 SG_ Module7OperationalStatus : 12|2@1+ (1,0) [0|3] "" Vector__XXX
 SG_ Module6OperationalStatus : 10|2@1+ (1,0) [0|3] "" Vector__XXX
 SG_ Module5OperationalStatus : 8|2@1+ (1,0) [0|3] "" Vector__XXX
 SG_ Module4OperationalStatus : 6|2@1+ (1,0) [0|3] "" Vector__XXX
 SG_ Module3OperationalStatus : 4|2@1+ (1,0) [0|3] "" Vector__XXX
 SG_ Module2OperationalStatus : 2|2@1+ (1,0) [0|3] "" Vector__XXX
 SG_ Module1OperationalStatus : 0|2@1+ (1,0) [0|3] "" Vector__XXX

BO_ 2364643582 HVESP1D7: 8 Vector__XXX
 SG_ MaxChargeVLmt : 48|16@1+ (0.05,0) [0|3212.75] "V" Vector__XXX
 SG_ ChargeEnergyCapacity : 24|24@1+ (0.001,0) [0|16449.535] "kWh" Vector__XXX
 SG_ DisEnergyCapacity : 0|24@1+ (0.001,0) [0|16449.535] "kWh" Vector__XXX

CM_ BO_ 2364653310 "High Voltage Energy Storage Pack 4 Data 1
Data set 1 (electrical data) for High Voltage Energy Storage Pack 4.";
CM_ SG_ 2364653310 Cur "The current in or out of this High Voltage Energy Storage Pack instance. This parameter should be synchronized with SPN 11400 (HVESP4 Voltage Level) such that a realized power value can be calculated.  This parameter is defined from the high voltage ...";
CM_ SG_ 2364653310 Lvl "The voltage level of this High Voltage Energy Storage Pack instance. This parameter should be synchronized with SPN 11401 (HVESP4 Current) such that a realized power value can be calculated.  If the HVES component physically contains the contactors ...";
CM_ SG_ 2364653310 AvailableChargePwr "The rate at which this High Voltage Energy Storage Pack instance can currently receive energy from a regenerative or recharging system.
This parameter is for one of multiple packs in an HVESS.  If there is only one pack in the system, the HVESS ...";
CM_ SG_ 2364653310 AvailableDisPwr "The rate at which this High Voltage Energy Storage Pack instance can currently provide energy for propulsion or other uses.
This parameter is for one of multiple packs in an HVESS.  If there is only one pack in the system, the HVESS parameters ...";
CM_ BO_ 2364653054 "High Voltage Energy Storage Pack 4 Status 2
Status data set 2 for High Voltage Energy Storage Pack 4.";
CM_ SG_ 2364653054 ChargePLDueToAnUndefinedCause "Indicates whether or not charge power of this HVES instance is being limited due to an undefined cause.
This parameter is for one of multiple packs in an HVESS.  If there is only one pack in the system, the HVESS parameters should be used. If there ...";
CM_ SG_ 2364653054 ChargePLDueToBatCur "Indicates whether or not charge power of this HVES instance is being limited due to battery current.
This parameter is for one of multiple packs in an HVESS.  If there is only one pack in the system, the HVESS parameters should be used. If there ...";
CM_ SG_ 2364653054 ChargePLDueToBatOrCellV "Indicates whether or not charge power of this HVES instance is being limited due to a battery or cell voltage level.
This parameter is for one of multiple packs in an HVESS.  If there is only one pack in the system, the HVESS parameters should be ...";
CM_ SG_ 2364653054 ChargePLDueToBatDiagCondition "Indicates whether or not charge power of this HVES instance is being limited due to a battery diagnostic condition.
This parameter is for one of multiple packs in an HVESS.  If there is only one pack in the system, the HVESS parameters should be ...";
CM_ SG_ 2364653054 ChargePLDueToBatTemp "Indicates whether or not charge power of this HVES instance is being limited due to battery temperature.
This parameter is for one of multiple packs in an HVESS.  If there is only one pack in the system, the HVESS parameters should be used. If ...";
CM_ SG_ 2364653054 ChargePLDueToStOfCharge "Indicates whether or not charge power of this HVES instance is being limited due to state of charge.
This parameter is for one of multiple packs in an HVESS.  If there is only one pack in the system, the HVESS parameters should be used. If there ...";
CM_ SG_ 2364653054 DisPLDueToAnUndefinedCause "Indicates whether or not discharge power of this HVES instance is being limited due to an undefined cause.
This parameter is for one of multiple packs in an HVESS.  If there is only one pack in the system, the HVESS parameters should be used. If ...";
CM_ SG_ 2364653054 DisPLDueToBatCur "Indicates whether or not discharge power of this HVES instance is being limited due to battery current.
This parameter is for one of multiple packs in an HVESS.  If there is only one pack in the system, the HVESS parameters should be used. If there ...";
CM_ SG_ 2364653054 DisPLDueToBatOrCellV "Indicates whether or not discharge power of this HVES instance is being limited due to a battery or cell voltage level.
This parameter is for one of multiple packs in an HVESS.  If there is only one pack in the system, the HVESS parameters should ...";
CM_ SG_ 2364653054 DisPLDueToBatDiagCondition "Indicates whether or not discharge power of this HVES instance is being limited due to a battery diagnostic condition.
This parameter is for one of multiple packs in an HVESS.  If there is only one pack in the system, the HVESS parameters should be ...";
CM_ SG_ 2364653054 DisPLDueToBatTemp "Indicates whether or not discharge power of this HVES instance is being limited due to battery temperature.
This parameter is for one of multiple packs in an HVESS.  If there is only one pack in the system, the HVESS parameters should be used. If ...";
CM_ SG_ 2364653054 DisPLDueToStOfCharge "Indicates whether or not discharge power of this HVES instance is being limited due to state of charge.
This parameter is for one of multiple packs in an HVESS.  If there is only one pack in the system, the HVESS parameters should be used. If there ...";
CM_ BO_ 2364652798 "High Voltage Energy Storage Pack 3 Data 11
Data set 11 (electrical data) for High Voltage Energy Storage Pack 3.";
CM_ SG_ 2364652798 ActualChargeRate "This signal represents the actual present charge rate of this High Voltage Energy Storage Pack instance.
This parameter is for one of multiple packs in an HVESS. If there is only one pack in the system, the HVESS parameters should be used. If there ...";
CM_ SG_ 2364652798 LvlNegToChassisGroundV "Voltage difference between the most negative terminal of the HVES battery and chassis measured at the battery side of any HVES contained output contactor.  This voltage may be used for system level monitoring of battery shorts to chassis within the ...";
CM_ SG_ 2364652798 BusVNegToChassisGroundV "Voltage difference between the most negative terminal of the HVES battery and chassis measured on the hybrid system bus side (not the battery side) of any HVES contained output contactor.  This voltage may be used for system level monitoring of ...";
CM_ BO_ 2364652542 "High Voltage Energy Storage Pack 3 Data 10
Data set 10 (electrical) for High Voltage Energy Storage Pack 3.";
CM_ SG_ 2364652542 HVBusPassiveIsolTestResults "The isolation resistance expressed in Ohms per Volt that resulted from the High-Voltage Bus Passive Isolation Test.
See SPN 11313 (HVESP3 High-Voltage Bus Passive Isolation Test Status) for test status and SPN 11264 (HVESP3 High-Voltage Bus Passive ...";
CM_ SG_ 2364652542 HVBusActiveIsolTestResults "The isolation resistance expressed in Ohms per Volt that resulted from the High-Voltage Bus Active Isolation Test.
See SPN 11312 (HVESP3 High-Voltage Bus Active Isolation Test Status) for test status and SPN 11263 (HVESP3 High-Voltage Bus Active ...";
CM_ SG_ 2364652542 LowestCellStOfChargeCellNum "Identifies the location of SPN 11299 (HVESP3 Lowest Cell State of Charge) within SPN 11358 (HVESP3 Lowest Cell State of Charge Module Number).
This parameter is for one of multiple packs in an HVESS.  If there is only one pack in the system, the ...";
CM_ SG_ 2364652542 LowestCellStOfChargeModuleNum "Identifies the location of the module containing SPN 11299 (HVESP3 Lowest Cell State of Charge).
This parameter is for one of multiple packs in an HVESS.  If there is only one pack in the system, the HVESS parameters should be used. If there are ...";
CM_ SG_ 2364652542 HighestCellStOfChargeCellNum "Identifies the location of SPN 11300 (HVESP3 Highest Cell State of Charge) within SPN 11356 (HVESP3 Highest Cell State of Charge Module Number).
This parameter is for one of multiple packs in an HVESS.  If there is only one pack in the system, the ...";
CM_ SG_ 2364652542 HighestCellStOfChargeModuleNum "Identifies the location of the module containing SPN 11300 (HVESP3 Highest Cell State of Charge).
This parameter is for one of multiple packs in an HVESS.  If there is only one pack in the system, the HVESS parameters should be used. If there are ...";
CM_ BO_ 2364652286 "High Voltage Energy Storage Pack 3 Data 9
Data set 9 (thermal) for High Voltage Energy Storage Pack 3.";
CM_ SG_ 2364652286 Data9CRC "The CRC is defined as follows:
• Length: 8 bits
• Polynomial: x^8+x^5+x^3+x^2+x+1
• Initial Value: FFh
• Input Data Reflection: Not reflected
• Result Data Reflection: Not reflected
• XOR value: FFh
SAE makes no claim of the functional safety ...";
CM_ SG_ 2364652286 Data9Counter "The message counter is used to detect situations where the transmitting ECU malfunction repeats the same frame all the time. The receiver of the information may use the counter parameter to detect this situation. The transmitting device will ...";
CM_ SG_ 2364652286 Data9EmbeddedIntegritySupport "Indicates SPN 22982 (HVESP3 Data 9 CRC) and SPN 22981 (HVESP3 Data 9 Counter) are supported by the sender.
00b = Embedded CRC and Counter are supported by the sender
01b = Protection is supported using J1939-76 SHM
10b = Reserved
11b = CRC and ...";
CM_ SG_ 2364652286 HVESS3ThermalEventDetected "A sensor has detected the presence of a thermal event at or near High Voltage Energy Storage Pack instance.
00b = No Thermal Event Detected
01b = Thermal Event Detected
10b = Error
11b = Not available
This parameter is for one of multiple packs ...";
CM_ SG_ 2364652286 LowestCellTempCellNum "Identifies the location of SPN 11291 (HVESP3 Lowest Cell Temperature) within SPN 11354 (HVESP3 Lowest Cell Temperature Module Number).
This parameter is for one of multiple packs in an HVESS.  If there is only one pack in the system, the HVESS ...";
CM_ SG_ 2364652286 LowestCellTempModuleNum "Identifies the location of the module containing SPN 11291 (HVESP3 Lowest Cell Temperature).
This parameter is for one of multiple packs in an HVESS.  If there is only one pack in the system, the HVESS parameters should be used. If there are ...";
CM_ SG_ 2364652286 HighestCellTempCellNum "Identifies the location of SPN 11290 (HVESP3 Highest Cell Temperature) within SPN 11352 (HVESP3 Highest Cell Temperature Module Number).
This parameter is for one of multiple packs in an HVESS.  If there is only one pack in the system, the HVESS ...";
CM_ SG_ 2364652286 HighestCellTempModuleNum "Identifies the location of the module containing SPN 11290 (HVESP3 Highest Cell Temperature).
This parameter is for one of multiple packs in an HVESS.  If there is only one pack in the system, the HVESS parameters should be used. If there are ...";
CM_ BO_ 2364652030 "High Voltage Energy Storage Pack 3 Data 8
Data set 8 (electrical data) for High Voltage Energy Storage Pack 3.";
CM_ SG_ 2364652030 AvgCellV "The average cell voltage in this High Voltage Energy Storage Pack instance.
This parameter is for one of multiple packs in an HVESS.  If there is only one pack in the system, the HVESS parameters should be used. If there are multiple packs in the ...";
CM_ SG_ 2364652030 LowestCellVCellNum "Identifies the location of SPN 11288 (HVESP3 Lowest Cell Voltage) within SPN 11349 (HVESP3 Lowest Cell Voltage Module Number).
This parameter is for one of multiple packs in an HVESS.  If there is only one pack in the system, the HVESS parameters ...";
CM_ SG_ 2364652030 LowestCellVModuleNum "Identifies the location of the module containing SPN 11288 (HVESP3 Lowest Cell Voltage).
This parameter is for one of multiple packs in an HVESS.  If there is only one pack in the system, the HVESS parameters should be used. If there are multiple ...";
CM_ SG_ 2364652030 HighestCellVCellNum "Identifies the location of SPN 11287 (HVESP3 Highest Cell Voltage) within SPN 11347 (HVESP3 Highest Cell Voltage Module Number).
This parameter is for one of multiple packs in an HVESS.  If there is only one pack in the system, the HVESS parameters ...";
CM_ SG_ 2364652030 HighestCellVModuleNum "Identifies the location of the module containing SPN 11287 (HVESP3 Highest Cell Voltage).
This parameter is for one of multiple packs in an HVESS.  If there is only one pack in the system, the HVESS parameters should be used. If there are multiple ...";
CM_ BO_ 2364651774 "High Voltage Energy Storage Pack 3 Thermal Management System Status 1
Collection of data the High Voltage Energy Storage Pack 3 Thermal Management System sends to the Hybrid Controller.";
CM_ SG_ 2364651774 TMSCoolantLvl "Indicates the coolant level in this HVES Thermal Management System (TMS).
This parameter is for one of multiple packs in an HVESS.  If there is only one pack in the system, the HVESS parameters should be used. If there are multiple packs in the ...";
CM_ SG_ 2364651774 TMSMode "Indicates the operating mode of the Thermal Management System.  The heat transfer medium may be (e.g. liquid or air).  The cooling system may be fans, liquid coolant, or a combination of mediums.  The system may include an air and/or liquid ...";
CM_ SG_ 2364651774 TMSHVILStatus "In multiple HVES configurations, this is the status of the High Voltage Interlock Loop from the viewpoint of this Thermal Management System.
00b = HVIL Closed
01b = HVIL Open
10b = Error
11b = Not Available
This parameter is for one of multiple ...";
CM_ SG_ 2364651774 TMSHtrStatus "The state of this High Voltage Energy Storage Pack heater
This parameter is for one of multiple packs in an HVESS.  If there is only one pack in the system, the HVESS parameters should be used. If there are multiple packs in the system, then both ...";
CM_ SG_ 2364651774 TMSRelHumidty "When this High Voltage Energy Storage Pack Thermal Management System is equipped with a relative humidity sensor, this is the  measured Relative Humidity.
This parameter is for one of multiple packs in an HVESS.  If there is only one pack in the ...";
CM_ SG_ 2364651774 TMSCompressorSpd "When this High Voltage Energy Storage Pack Thermal Management System is equipped with an active cooling system (e.g. air conditioner), this is the Compressor Speed.
This parameter is for one of multiple packs in an HVESS.  If there is only one pack ...";
CM_ SG_ 2364651774 TMSHVInputPwr "This is the high-voltage power consumed by this HVES Thermal Management System (TMS).
This parameter is for one of multiple packs in an HVESS.  If there is only one pack in the system, the HVESS parameters should be used. If there are multiple ...";
CM_ SG_ 2364651774 TMSSLIInputPwr "This is the low-voltage power consumed by this HVES Thermal Management System (TMS).
This parameter is for one of multiple packs in an HVESS.  If there is only one pack in the system, the HVESS parameters should be used.  If there are multiple ...";
CM_ BO_ 2364651518 "High Voltage Energy Storage Pack 3 Module Status 1
Module Status message 1 for High Voltage Energy Storage Pack 3.";
CM_ SG_ 2364651518 Module32OperationalStatus "Operational Status of Module 32 in this High Voltage Energy Storage System (or Pack 1 in systems with only one pack).  Not Operational is used when the module is initializing or not able to function (e.g. internal module level monitors have failed) ...";
CM_ SG_ 2364651518 Module31OperationalStatus "Operational Status of Module 31 in this High Voltage Energy Storage System (or Pack 1 in systems with only one pack).  Not Operational is used when the module is initializing or not able to function (e.g. internal module level monitors have failed) ...";
CM_ SG_ 2364651518 Module30OperationalStatus "Operational Status of Module 30 in this High Voltage Energy Storage System (or Pack 1 in systems with only one pack).  Not Operational is used when the module is initializing or not able to function (e.g. internal module level monitors have failed) ...";
CM_ SG_ 2364651518 Module29OperationalStatus "Operational Status of Module 29 in this High Voltage Energy Storage System (or Pack 1 in systems with only one pack).  Not Operational is used when the module is initializing or not able to function (e.g. internal module level monitors have failed) ...";
CM_ SG_ 2364651518 Module28OperationalStatus "Operational Status of Module 28 in this High Voltage Energy Storage System (or Pack 1 in systems with only one pack).  Not Operational is used when the module is initializing or not able to function (e.g. internal module level monitors have failed) ...";
CM_ SG_ 2364651518 Module27OperationalStatus "Operational Status of Module 27 in this High Voltage Energy Storage System (or Pack 1 in systems with only one pack).  Not Operational is used when the module is initializing or not able to function (e.g. internal module level monitors have failed) ...";
CM_ SG_ 2364651518 Module26OperationalStatus "Operational Status of Module 26 in this High Voltage Energy Storage System (or Pack 1 in systems with only one pack).  Not Operational is used when the module is initializing or not able to function (e.g. internal module level monitors have failed) ...";
CM_ SG_ 2364651518 Module25OperationalStatus "Operational Status of Module 25 in this High Voltage Energy Storage System (or Pack 1 in systems with only one pack).  Not Operational is used when the module is initializing or not able to function (e.g. internal module level monitors have failed) ...";
CM_ SG_ 2364651518 Module24OperationalStatus "Operational Status of Module 24 in this High Voltage Energy Storage System (or Pack 1 in systems with only one pack).  Not Operational is used when the module is initializing or not able to function (e.g. internal module level monitors have failed) ...";
CM_ SG_ 2364651518 Module23OperationalStatus "Operational Status of Module 23 in this High Voltage Energy Storage System (or Pack 1 in systems with only one pack).  Not Operational is used when the module is initializing or not able to function (e.g. internal module level monitors have failed) ...";
CM_ SG_ 2364651518 Module22OperationalStatus "Operational Status of Module 22 in this High Voltage Energy Storage System (or Pack 1 in systems with only one pack).  Not Operational is used when the module is initializing or not able to function (e.g. internal module level monitors have failed) ...";
CM_ SG_ 2364651518 Module21OperationalStatus "Operational Status of Module 21 in this High Voltage Energy Storage System (or Pack 1 in systems with only one pack).  Not Operational is used when the module is initializing or not able to function (e.g. internal module level monitors have failed) ...";
CM_ SG_ 2364651518 Module20OperationalStatus "Operational Status of Module 20 in this High Voltage Energy Storage System (or Pack 1 in systems with only one pack).  Not Operational is used when the module is initializing or not able to function (e.g. internal module level monitors have failed) ...";
CM_ SG_ 2364651518 Module19OperationalStatus "Operational Status of Module 19 in this High Voltage Energy Storage System (or Pack 1 in systems with only one pack).  Not Operational is used when the module is initializing or not able to function (e.g. internal module level monitors have failed) ...";
CM_ SG_ 2364651518 Module18OperationalStatus "Operational Status of Module 18 in this High Voltage Energy Storage System (or Pack 1 in systems with only one pack).  Not Operational is used when the module is initializing or not able to function (e.g. internal module level monitors have failed) ...";
CM_ SG_ 2364651518 Module17OperationalStatus "Operational Status of Module 17 in this High Voltage Energy Storage System (or Pack 1 in systems with only one pack).  Not Operational is used when the module is initializing or not able to function (e.g. internal module level monitors have failed) ...";
CM_ SG_ 2364651518 Module16OperationalStatus "Operational Status of Module 16 in this High Voltage Energy Storage Pack Instance.  Not Operational is used when the module is initializing or not able to function (e.g. internal module level monitors have failed).  Operational indicates that the ...";
CM_ SG_ 2364651518 Module15OperationalStatus "Operational Status of Module 15 in this High Voltage Energy Storage Pack Instance.  Not Operational is used when the module is initializing or not able to function (e.g. internal module level monitors have failed).  Operational indicates that the ...";
CM_ SG_ 2364651518 Module14OperationalStatus "Operational Status of Module 14 in this High Voltage Energy Storage Pack Instance.  Not Operational is used when the module is initializing or not able to function (e.g. internal module level monitors have failed).  Operational indicates that the ...";
CM_ SG_ 2364651518 Module13OperationalStatus "Operational Status of Module 13 in this High Voltage Energy Storage Pack Instance.  Not Operational is used when the module is initializing or not able to function (e.g. internal module level monitors have failed).  Operational indicates that the ...";
CM_ SG_ 2364651518 Module12OperationalStatus "Operational Status of Module 12 in this High Voltage Energy Storage Pack Instance.  Not Operational is used when the module is initializing or not able to function (e.g. internal module level monitors have failed).  Operational indicates that the ...";
CM_ SG_ 2364651518 Module11OperationalStatus "Operational Status of Module 11 in this High Voltage Energy Storage Pack Instance.  Not Operational is used when the module is initializing or not able to function (e.g. internal module level monitors have failed).  Operational indicates that the ...";
CM_ SG_ 2364651518 Module10OperationalStatus "Operational Status of Module 10 in this High Voltage Energy Storage Pack Instance.  Not Operational is used when the module is initializing or not able to function (e.g. internal module level monitors have failed).  Operational indicates that the ...";
CM_ SG_ 2364651518 Module9OperationalStatus "Operational Status of Module 9 in this High Voltage Energy Storage Pack Instance.  Not Operational is used when the module is initializing or not able to function (e.g. internal module level monitors have failed).  Operational indicates that the ...";
CM_ SG_ 2364651518 Module8OperationalStatus "Operational Status of Module 8 in this High Voltage Energy Storage Pack Instance.  Not Operational is used when the module is initializing or not able to function (e.g. internal module level monitors have failed).  Operational indicates that the ...";
CM_ SG_ 2364651518 Module7OperationalStatus "Operational Status of Module 7 in this High Voltage Energy Storage Pack Instance.  Not Operational is used when the module is initializing or not able to function (e.g. internal module level monitors have failed).  Operational indicates that the ...";
CM_ SG_ 2364651518 Module6OperationalStatus "Operational Status of Module 6 in this High Voltage Energy Storage Pack Instance.  Not Operational is used when the module is initializing or not able to function (e.g. internal module level monitors have failed).  Operational indicates that the ...";
CM_ SG_ 2364651518 Module5OperationalStatus "Operational Status of Module 5 in this High Voltage Energy Storage Pack Instance.  Not Operational is used when the module is initializing or not able to function (e.g. internal module level monitors have failed).  Operational indicates that the ...";
CM_ SG_ 2364651518 Module4OperationalStatus "Operational Status of Module 4 in this High Voltage Energy Storage Pack Instance.  Not Operational is used when the module is initializing or not able to function (e.g. internal module level monitors have failed).  Operational indicates that the ...";
CM_ SG_ 2364651518 Module3OperationalStatus "Operational Status of Module 3 in this High Voltage Energy Storage Pack Instance.  Not Operational is used when the module is initializing or not able to function (e.g. internal module level monitors have failed).  Operational indicates that the ...";
CM_ SG_ 2364651518 Module2OperationalStatus "Operational Status of Module 2 in this High Voltage Energy Storage Pack Instance.  Not Operational is used when the module is initializing or not able to function (e.g. internal module level monitors have failed).  Operational indicates that the ...";
CM_ SG_ 2364651518 Module1OperationalStatus "Operational Status of Module 1 in this High Voltage Energy Storage Pack Instance.  Not Operational is used when the module is initializing or not able to function (e.g. internal module level monitors have failed).  Operational indicates that the ...";
CM_ BO_ 2364651262 "High Voltage Energy Storage Pack 3 Data 7
Data set 7 (electrical) for High Voltage Energy Storage Pack 3.";
CM_ SG_ 2364651262 MaxChargeVLmt "The maximum voltage level not to be exceeded while charging this High Voltage Energy Storage Pack instance.  If this parameter is not supported, the maximum charge voltage should be limited to SPN 11366 (HVESP3 Recommended Maximum Operating ...";
CM_ SG_ 2364651262 ChargeEnergyCapacity "The amount of unused electrical energy storage available to be filled by charging this High Voltage Energy Storage Pack instance, i.e. “how much empty space is remaining in the tank”.  See SPN 11295 (HVESP3 Charge Capacity) for Ampere-hours (Ah).
 ...";
CM_ SG_ 2364651262 DisEnergyCapacity "The amount of stored electrical energy in this High Voltage Energy Storage Pack instance that is available for use by the hybrid system, i.e. “how full is the tank”.  See SPN 11294 (HVESP3 Discharge Capacity) for Ampere-hours (Ah).
This parameter ...";
CM_ BO_ 2364651006 "High Voltage Energy Storage Pack 3 Status 1
Status data set 1 for High Voltage Energy Storage Pack 3.";
CM_ SG_ 2364651006 Status1CRC "The CRC is defined as follows:
• Length: 8 bits
• Polynomial: x^8+x^5+x^3+x^2+x+1
• Initial Value: FFh
• Input Data Reflection: Not reflected
• Result Data Reflection: Not reflected
• XOR value: FFh
SAE makes no claim of the functional safety ...";
CM_ SG_ 2364651006 Status1Counter "The message counter is used to detect situations where the transmitting ECU malfunction repeats the same frame all the time. The receiver of the information may use the counter parameter to detect this situation. The transmitting device will ...";
CM_ SG_ 2364651006 OperationalStatus "Provides feedback on where this High Voltage Energy Storage Pack instance is in its operating spectrum, and includes feedback in response to the Operation Consent [i.e. SPN 11267 (HVESP3 Operation Consent)] and Power Down Command [i.e. SPN 11262 ...";
CM_ SG_ 2364651006 HVBusConnectionStatus "This parameter provides high level feedback on this High Voltage Energy Storage Pack instance high voltage bus connection.  For specific contactor information, see SPN 11307 (HVESP3 High-Voltage Bus (Positive) Contactor State), SPN 11308 (HVESP3 ...";
CM_ SG_ 2364651006 InternalChargerStatus "Indicates that the charger in this HVES instance is on.  External chargers may use the External Energy Source Connection Status (SPN 7898) and related SPs.
This parameter is for one of multiple packs in an HVESS. If there is only one pack in the ...";
CM_ SG_ 2364651006 CellBalancingActive "Indicates whether or not the cells in this High Voltage Energy Storage Pack instance are currently being balanced.
This parameter is for one of multiple packs in an HVESS.  If there is only one pack in the system, the HVESS parameters should be ...";
CM_ SG_ 2364651006 CellBalanceStatus "Indicates whether or not the cells in this High Voltage Energy Storage Pack instance are balanced.
This parameter is for one of multiple packs in an HVESS.  If there is only one pack in the system, the HVESS parameters should be used. If there are ...";
CM_ SG_ 2364651006 StOfChargeStatus "Status of this High Voltage Energy Storage Pack instance State of Charge (SOC).  Note:  A given HVES controller may not support all of the states.
This parameter is for one of multiple packs in an HVESS.  If there is only one pack in the system, ...";
CM_ SG_ 2364651006 InertiaSwStatus "Switch indicating that an impact has been sensed by this High Voltage Energy Storage Pack instance. The impact indication may require action by another controller, or by this HVES instance itself.  For example, a controller may elect to take this ...";
CM_ SG_ 2364651006 HVILStatus "Status of the High Voltage Interlock Loop from the viewpoint of this High Voltage Energy Storage Pack instance.
This parameter is for one of multiple packs in an HVESS. If there is only one pack in the system, the HVESS parameters should be used ...";
CM_ SG_ 2364651006 HVBusPassiveIsolTestStatus "Status of the high-voltage bus electrical passive isolation test as performed by this High Voltage Energy Storage Pack instance.
This parameter is for one of multiple packs in an HVESS. If there is only one pack in the system, the HVESS parameters ...";
CM_ SG_ 2364651006 HVBusActiveIsolTestStatus "Status of the high-voltage bus electrical active isolation test as performed by this High Voltage Energy Storage Pack instance.
This parameter is for one of multiple packs in an HVESS. If there is only one pack in the system, the HVESS parameters ...";
CM_ SG_ 2364651006 CenterOfPackContactorSt "Position of the center high-voltage contactor.  When this contactor is closed, the positive half of this High Voltage Energy Storage Pack instance is connected to the negative half.  If a system controls the positive, negative, and center contactors ...";
CM_ SG_ 2364651006 HVBusPreChargeRelaySt "Position of the high-voltage bus contactor pre-charge relay.  When this relay is closed, this High Voltage Energy Storage Pack instance is bringing the high-voltage bus up to its operating level.
This parameter is for one of multiple packs in an ...";
CM_ SG_ 2364651006 HVBusDisconnectForewarning "Indicates that this High Voltage Energy Storage Pack instance is about to disconnect from the high voltage bus due to unacceptable conditions.
This parameter is for one of multiple packs in an HVESS. If there is only one pack in the system, the ...";
CM_ SG_ 2364651006 HVBusContactorSt11308 "Position of this High Voltage Energy Storage Pack instance negative side bus contactor.  When this contactor is closed, the negative side of this HVES instance is connected to the negative side of the high-voltage bus.  If a system controls the ...";
CM_ SG_ 2364651006 HVBusContactorSt "Position of this High Voltage Energy Storage Pack instance positive side bus contactor.  When this contactor is closed, the positive side of this HVES instance is connected to the positive side of the high-voltage bus.  In systems where all ...";
CM_ BO_ 2364650750 "High Voltage Energy Storage Pack 3 Data 6
Data set 6 (external or interface data) for High Voltage Energy Storage Pack 3.";
CM_ SG_ 2364650750 Temp "The temperature of this High Voltage Energy Storage Pack instance. The value may be determined from a unique sensor specifically for this purpose, or by aggregating various temperature sensor readings within the pack.
This parameter is for one of ...";
CM_ SG_ 2364650750 ETemp "The temperature of the electronics or control modules in this High Voltage Energy Storage Pack instance.  If there are multiple temperature sensors then this parameter would be set to the maximum sensor reading.
This parameter is for one of ...";
CM_ SG_ 2364650750 OutCoolantTemp "The temperature of liquid coolant as it exits this High Voltage Energy Storage Pack instance.
This parameter is for one of multiple packs in an HVESS.  If there is only one pack in the system, the HVESS parameters should be used. If there are ...";
CM_ SG_ 2364650750 InCoolantTemp "The temperature of liquid coolant as it enters this High Voltage Energy Storage Pack instance.
This parameter is for one of multiple packs in an HVESS.  If there is only one pack in the system, the HVESS parameters should be used. If there are ...";
CM_ SG_ 2364650750 IgntV "The voltage level at the ignition input of this High Voltage Energy Storage Pack controller.
This parameter is for one of multiple packs in an HVESS.  If there is only one pack in the system, the HVESS parameters should be used.  If there are ...";
CM_ SG_ 2364650750 BusV "The voltage level of the high voltage bus, as measured by this High Voltage Energy Storage Pack instance on the bus side (not the battery side) of its contactors.
This parameter is for one of multiple packs in an HVESS.  If there is only one pack ...";
CM_ BO_ 2364650494 "High Voltage Energy Storage Pack 3 Data 5
Data set 5 (electrical data) for High Voltage Energy Storage Pack 3.";
CM_ SG_ 2364650494 HighestCellStOfCharge "Indicates the state of charge of the highest-charged cell in this High Voltage Energy Storage Pack instance.  0% means no charge remaining, 100% means the cell is fully charged.  If a single state of charge value covers more than one cell, the value ...";
CM_ SG_ 2364650494 LowestCellStOfCharge "Indicates the state of charge of the lowest-charged cell in this High Voltage Energy Storage Pack instance.  0% means no charge remaining, 100% means the cell is fully charged.   If a single state of charge value covers more than one cell, the value ...";
CM_ SG_ 2364650494 ChargeCurLmt "The maximum instantaneous current flow limit into this High Voltage Energy Storage Pack instance. This parameter is defined from the high voltage energy storage pack's point of view and should reflect the instantaneous capability of the pack.  The ...";
CM_ SG_ 2364650494 DisCurLmt "The maximum instantaneous current flow limit out of this High Voltage Energy Storage Pack instance. This parameter is defined from the high voltage energy storage pack's point of view and should reflect the instantaneous capability of the pack.  The ...";
CM_ BO_ 2364650238 "High Voltage Energy Storage Pack 3 Data 4
Data set 4 (electrical data) for High Voltage Energy Storage Pack 3.";
CM_ SG_ 2364650238 CellBalancingCount "The number of cells that are currently being balanced in this High Voltage Energy Storage Pack instance.
This parameter is for one of multiple packs in an HVESS.  If there is only one pack in the system, the HVESS parameters should be used.  If ...";
CM_ SG_ 2364650238 ChargeCapacity "The amount of unused electrical charge storage in this High Voltage Energy Storage Pack instance that is available to be filled by charging, i.e. “how much empty space is remaining in the tank”.  See SPN 11323 (HVESP3 Charge Energy Capacity) for ...";
CM_ SG_ 2364650238 DisCapacity "The amount of stored electrical charge in this High Voltage Energy Storage Pack instance that is available for use by the hybrid system, i.e. “how full is the tank”.  See SPN 11322 (HVESP3 Discharge Energy Capacity) for kilowatt-hours (kWh).
This ...";
CM_ BO_ 2364649982 "High Voltage Energy Storage Pack 3 Data 3
Data set 3 (thermal data) for High Voltage Energy Storage Pack 3.";
CM_ SG_ 2364649982 CellTempDiffStatus "Indicates whether or not the differential between the highest and lowest cell temperatures are within acceptable limits per this High Voltage Energy Storage Pack instance.  The actual temperature differential can be calculated by subtracting SPN ...";
CM_ SG_ 2364649982 AvgCellTemp "The average temperature level of all cells in this High Voltage Energy Storage Pack instance.
This parameter is for one of multiple packs in an HVESS.  If there is only one pack in the system, the HVESS parameters should be used.  If there are ...";
CM_ SG_ 2364649982 LowestCellTemp "The lowest temperature level reported by any cell in this High Voltage Energy Storage Pack instance.  If a single temperature sensor covers more than one cell, the value in this parameter is for the smallest group of cells measured.  See SPN 11354 ...";
CM_ SG_ 2364649982 HighestCellTemp "The highest temperature level reported by any cell in this High Voltage Energy Storage Pack instance.  If a single temperature sensor covers more than one cell, the value in this parameter is for the smallest group of cells measured.   See SPN 11352 ...";
CM_ BO_ 2364649726 "High Voltage Energy Storage Pack 3 Data 2
Data set 2 (electrical data) for High Voltage Energy Storage Pack 3.";
CM_ SG_ 2364649726 CellVDiffStatus "Indicates whether or not the differential between the highest and lowest cell voltages are within acceptable limits, according to this High Voltage Energy Storage Pack instance. The actual voltage differential can be calculated by subtracting SPN ...";
CM_ SG_ 2364649726 LowestCellV "The lowest voltage level reported by any cell in this High Voltage Energy Storage Pack instance. If a single voltage sensor covers more than one cell, the value in this parameter is for the smallest group of cells measured.  See SPN 11349 (HVESP3 ...";
CM_ SG_ 2364649726 HighestCellV "The highest voltage level reported by any cell in this High Voltage Energy Storage Pack instance. If a single voltage sensor covers more than one cell, the value in this parameter is for the smallest group of cells measured. See SPN 11347 (HVESP3 ...";
CM_ SG_ 2364649726 FastUpdateStOfCharge "Indicates this High Voltage Energy Storage Pack instance state of charge.  0% means no charge remaining, 100% means the system is fully charged in terms of physical limits of this energy storage pack instance.  Acceptable state of charge upper and ...";
CM_ BO_ 2364649470 "High Voltage Energy Storage Pack 3 Data 1
Data set 1 (electrical data) for High Voltage Energy Storage Pack 3.";
CM_ SG_ 2364649470 Cur "The current in or out of this High Voltage Energy Storage Pack instance. This parameter should be synchronized with SPN 11284 (HVESP3 Voltage Level) such that a realized power value can be calculated.  This parameter is defined from the high voltage ...";
CM_ SG_ 2364649470 Lvl "The voltage level of this High Voltage Energy Storage Pack instance. This parameter should be synchronized with SPN 11285 (HVESP3 Current) such that a realized power value can be calculated.  If the HVES component physically contains the contactors ...";
CM_ SG_ 2364649470 AvailableChargePwr "The rate at which this High Voltage Energy Storage Pack instance can currently receive energy from a regenerative or recharging system.
This parameter is for one of multiple packs in an HVESS.  If there is only one pack in the system, the HVESS ...";
CM_ SG_ 2364649470 AvailableDisPwr "The rate at which this High Voltage Energy Storage Pack instance can currently provide energy for propulsion or other uses.
This parameter is for one of multiple packs in an HVESS.  If there is only one pack in the system, the HVESS parameters ...";
CM_ BO_ 2364649214 "High Voltage Energy Storage Pack 3 Status 2
Status data set 2 for High Voltage Energy Storage Pack 3.";
CM_ SG_ 2364649214 ChargePLDueToAnUndefinedCause "Indicates whether or not charge power of this HVES instance is being limited due to an undefined cause.
This parameter is for one of multiple packs in an HVESS.  If there is only one pack in the system, the HVESS parameters should be used. If there ...";
CM_ SG_ 2364649214 ChargePLDueToBatCur "Indicates whether or not charge power of this HVES instance is being limited due to battery current.
This parameter is for one of multiple packs in an HVESS.  If there is only one pack in the system, the HVESS parameters should be used. If there ...";
CM_ SG_ 2364649214 ChargePLDueToBatOrCellV "Indicates whether or not charge power of this HVES instance is being limited due to a battery or cell voltage level.
This parameter is for one of multiple packs in an HVESS.  If there is only one pack in the system, the HVESS parameters should be ...";
CM_ SG_ 2364649214 ChargePLDueToBatDiagCondition "Indicates whether or not charge power of this HVES instance is being limited due to a battery diagnostic condition.
This parameter is for one of multiple packs in an HVESS.  If there is only one pack in the system, the HVESS parameters should be ...";
CM_ SG_ 2364649214 ChargePLDueToBatTemp "Indicates whether or not charge power of this HVES instance is being limited due to battery temperature.
This parameter is for one of multiple packs in an HVESS.  If there is only one pack in the system, the HVESS parameters should be used. If ...";
CM_ SG_ 2364649214 ChargePLDueToStOfCharge "Indicates whether or not charge power of this HVES instance is being limited due to state of charge.
This parameter is for one of multiple packs in an HVESS.  If there is only one pack in the system, the HVESS parameters should be used. If there ...";
CM_ SG_ 2364649214 DisPLDueToAnUndefinedCause "Indicates whether or not discharge power of this HVES instance is being limited due to an undefined cause.
This parameter is for one of multiple packs in an HVESS.  If there is only one pack in the system, the HVESS parameters should be used. If ...";
CM_ SG_ 2364649214 DisPLDueToBatCur "Indicates whether or not discharge power of this HVES instance is being limited due to battery current.
This parameter is for one of multiple packs in an HVESS.  If there is only one pack in the system, the HVESS parameters should be used. If there ...";
CM_ SG_ 2364649214 DisPLDueToBatOrCellV "Indicates whether or not discharge power of this HVES instance is being limited due to a battery or cell voltage level.
This parameter is for one of multiple packs in an HVESS.  If there is only one pack in the system, the HVESS parameters should ...";
CM_ SG_ 2364649214 DisPLDueToBatDiagCondition "Indicates whether or not discharge power of this HVES instance is being limited due to a battery diagnostic condition.
This parameter is for one of multiple packs in an HVESS.  If there is only one pack in the system, the HVESS parameters should be ...";
CM_ SG_ 2364649214 DisPLDueToBatTemp "Indicates whether or not discharge power of this HVES instance is being limited due to battery temperature.
This parameter is for one of multiple packs in an HVESS.  If there is only one pack in the system, the HVESS parameters should be used. If ...";
CM_ SG_ 2364649214 DisPLDueToStOfCharge "Indicates whether or not discharge power of this HVES instance is being limited due to state of charge.
This parameter is for one of multiple packs in an HVESS.  If there is only one pack in the system, the HVESS parameters should be used. If there ...";
CM_ BO_ 2364648958 "High Voltage Energy Storage Pack 2 Data 11
Data set 11 (electrical data) for High Voltage Energy Storage Pack 2.";
CM_ SG_ 2364648958 ActualChargeRate "This signal represents the actual present charge rate of this High Voltage Energy Storage Pack instance.
This parameter is for one of multiple packs in an HVESS. If there is only one pack in the system, the HVESS parameters should be used. If there ...";
CM_ SG_ 2364648958 LvlNegToChassisGroundV "Voltage difference between the most negative terminal of the HVES battery and chassis measured at the battery side of any HVES contained output contactor.  This voltage may be used for system level monitoring of battery shorts to chassis within the ...";
CM_ SG_ 2364648958 BusVNegToChassisGroundV "Voltage difference between the most negative terminal of the HVES battery and chassis measured on the hybrid system bus side (not the battery side) of any HVES contained output contactor.  This voltage may be used for system level monitoring of ...";
CM_ BO_ 2364648702 "High Voltage Energy Storage Pack 2 Data 10
Data set 10 (electrical) for High Voltage Energy Storage Pack 2.";
CM_ SG_ 2364648702 HVBusPassiveIsolTestResults "The isolation resistance expressed in Ohms per Volt that resulted from the High-Voltage Bus Passive Isolation Test.
See SPN 11197 (HVESP2 High-Voltage Bus Passive Isolation Test Status) for test status and SPN 11148 (HVESP2 High-Voltage Bus Passive ...";
CM_ SG_ 2364648702 HVBusActiveIsolTestResults "The isolation resistance expressed in Ohms per Volt that resulted from the High-Voltage Bus Active Isolation Test.
See SPN 11196 (HVESP2 High-Voltage Bus Active Isolation Test Status) for test status and SPN 11147 (HVESP2 High-Voltage Bus Active ...";
CM_ SG_ 2364648702 LowestCellStOfChargeCellNum "Identifies the location of SPN 11183 (HVESP2 Lowest Cell State of Charge) within SPN 11242 (HVESP2 Lowest Cell State of Charge Module Number).
This parameter is for one of multiple packs in an HVESS.  If there is only one pack in the system, the ...";
CM_ SG_ 2364648702 LowestCellStOfChargeModuleNum "Identifies the location of the module containing SPN 11183 (HVESP2 Lowest Cell State of Charge).
This parameter is for one of multiple packs in an HVESS.  If there is only one pack in the system, the HVESS parameters should be used. If there are ...";
CM_ SG_ 2364648702 HighestCellStOfChargeCellNum "Identifies the location of SPN 11184 (HVESP2 Highest Cell State of Charge) within SPN 11240 (HVESP2 Highest Cell State of Charge Module Number).
This parameter is for one of multiple packs in an HVESS.  If there is only one pack in the system, the ...";
CM_ SG_ 2364648702 HighestCellStOfChargeModuleNum "Identifies the location of the module containing SPN 11184 (HVESP2 Highest Cell State of Charge).
This parameter is for one of multiple packs in an HVESS.  If there is only one pack in the system, the HVESS parameters should be used. If there are ...";
CM_ BO_ 2364648446 "High Voltage Energy Storage Pack 2 Data 9
Data set 9 (thermal) for High Voltage Energy Storage Pack 2.";
CM_ SG_ 2364648446 Data9CRC "The CRC is defined as follows:
• Length: 8 bits
• Polynomial: x^8+x^5+x^3+x^2+x+1
• Initial Value: FFh
• Input Data Reflection: Not reflected
• Result Data Reflection: Not reflected
• XOR value: FFh
SAE makes no claim of the functional safety ...";
CM_ SG_ 2364648446 Data9Counter "The message counter is used to detect situations where the transmitting ECU malfunction repeats the same frame all the time. The receiver of the information may use the counter parameter to detect this situation. The transmitting device will ...";
CM_ SG_ 2364648446 Data9EmbeddedIntegritySupport "Indicates SPN 22979 (HVESP2 Data 9 CRC) and SPN 22978 (HVESP2 Data 9 Counter) are supported by the sender.
00b = Embedded CRC and Counter are supported by the sender
01b = Protection is supported using J1939-76 SHM
10b = Reserved
11b = CRC and ...";
CM_ SG_ 2364648446 HVESS2ThermalEventDetected "A sensor has detected the presence of a thermal event at or near High Voltage Energy Storage Pack instance.
00b = No Thermal Event Detected
01b = Thermal Event Detected
10b = Error
11b = Not available
This parameter is for one of multiple packs ...";
CM_ SG_ 2364648446 LowestCellTempCellNum "Identifies the location of SPN 11175 (HVESP2 Lowest Cell Temperature) within SPN 11238 (HVESP2 Lowest Cell Temperature Module Number).
This parameter is for one of multiple packs in an HVESS.  If there is only one pack in the system, the HVESS ...";
CM_ SG_ 2364648446 LowestCellTempModuleNum "Identifies the location of the module containing SPN 11175 (HVESP2 Lowest Cell Temperature).
This parameter is for one of multiple packs in an HVESS.  If there is only one pack in the system, the HVESS parameters should be used. If there are ...";
CM_ SG_ 2364648446 HighestCellTempCellNum "Identifies the location of SPN 11174 (HVESP2 Highest Cell Temperature) within SPN 11236 (HVESP2 Highest Cell Temperature Module Number).
This parameter is for one of multiple packs in an HVESS.  If there is only one pack in the system, the HVESS ...";
CM_ SG_ 2364648446 HighestCellTempModuleNum "Identifies the location of the module containing SPN 11174 (HVESP2 Highest Cell Temperature).
This parameter is for one of multiple packs in an HVESS.  If there is only one pack in the system, the HVESS parameters should be used. If there are ...";
CM_ BO_ 2364648190 "High Voltage Energy Storage Pack 2 Data 8
Data set 8 (electrical data) for High Voltage Energy Storage Pack 2.";
CM_ SG_ 2364648190 AvgCellV "The average cell voltage in this High Voltage Energy Storage Pack instance.
This parameter is for one of multiple packs in an HVESS.  If there is only one pack in the system, the HVESS parameters should be used. If there are multiple packs in the ...";
CM_ SG_ 2364648190 LowestCellVCellNum "Identifies the location of SPN 11172 (HVESP2 Lowest Cell Voltage) within SPN 11233 (HVESP2 Lowest Cell Voltage Module Number).
This parameter is for one of multiple packs in an HVESS.  If there is only one pack in the system, the HVESS parameters ...";
CM_ SG_ 2364648190 LowestCellVModuleNum "Identifies the location of the module containing SPN 11172 (HVESP2 Lowest Cell Voltage).
This parameter is for one of multiple packs in an HVESS.  If there is only one pack in the system, the HVESS parameters should be used. If there are multiple ...";
CM_ SG_ 2364648190 HighestCellVCellNum "Identifies the location of SPN 11171 (HVESP2 Highest Cell Voltage) within SPN 11231 (HVESP2 Highest Cell Voltage Module Number).
This parameter is for one of multiple packs in an HVESS.  If there is only one pack in the system, the HVESS parameters ...";
CM_ SG_ 2364648190 HighestCellVModuleNum "Identifies the location of the module containing SPN 11171 (HVESP2 Highest Cell Voltage).
This parameter is for one of multiple packs in an HVESS.  If there is only one pack in the system, the HVESS parameters should be used. If there are multiple ...";
CM_ BO_ 2364647934 "High Voltage Energy Storage Pack 2 Thermal Management System Status 1
Collection of data the High Voltage Energy Storage Pack 2 Thermal Management System sends to the Hybrid Controller.";
CM_ SG_ 2364647934 TMSCoolantLvl "Indicates the coolant level in this HVES Thermal Management System (TMS).
This parameter is for one of multiple packs in an HVESS.  If there is only one pack in the system, the HVESS parameters should be used. If there are multiple packs in the ...";
CM_ SG_ 2364647934 TMSMode "Indicates the operating mode of the Thermal Management System.  The heat transfer medium may be (e.g. liquid or air).  The cooling system may be fans, liquid coolant, or a combination of mediums.  The system may include an air and/or liquid ...";
CM_ SG_ 2364647934 TMSHVILStatus "In multiple HVES configurations, this is the status of the High Voltage Interlock Loop from the viewpoint of this Thermal Management System.
00b = HVIL Closed
01b = HVIL Open
10b = Error
11b = Not Available
This parameter is for one of multiple ...";
CM_ SG_ 2364647934 TMSHtrStatus "The state of this High Voltage Energy Storage Pack heater
This parameter is for one of multiple packs in an HVESS.  If there is only one pack in the system, the HVESS parameters should be used. If there are multiple packs in the system, then both ...";
CM_ SG_ 2364647934 TMSRelHumidty "When this High Voltage Energy Storage Pack Thermal Management System is equipped with a relative humidity sensor, this is the  measured Relative Humidity.
This parameter is for one of multiple packs in an HVESS.  If there is only one pack in the ...";
CM_ SG_ 2364647934 TMSCompressorSpd "When this High Voltage Energy Storage Pack Thermal Management System is equipped with an active cooling system (e.g. air conditioner), this is the Compressor Speed.
This parameter is for one of multiple packs in an HVESS.  If there is only one pack ...";
CM_ SG_ 2364647934 TMSHVInputPwr "This is the high-voltage power consumed by this HVES Thermal Management System (TMS).
This parameter is for one of multiple packs in an HVESS.  If there is only one pack in the system, the HVESS parameters should be used. If there are multiple ...";
CM_ SG_ 2364647934 TMSSLIInputPwr "This is the low-voltage power consumed by this HVES Thermal Management System (TMS).
This parameter is for one of multiple packs in an HVESS.  If there is only one pack in the system, the HVESS parameters should be used.  If there are multiple ...";
CM_ BO_ 2364647678 "High Voltage Energy Storage Pack 2 Module Status 1
Module Status message 1 for High Voltage Energy Storage Pack 2.";
CM_ SG_ 2364647678 Module32OperationalStatus "Operational Status of Module 32 in this High Voltage Energy Storage System (or Pack 1 in systems with only one pack).  Not Operational is used when the module is initializing or not able to function (e.g. internal module level monitors have failed) ...";
CM_ SG_ 2364647678 Module31OperationalStatus "Operational Status of Module 31 in this High Voltage Energy Storage System (or Pack 1 in systems with only one pack).  Not Operational is used when the module is initializing or not able to function (e.g. internal module level monitors have failed) ...";
CM_ SG_ 2364647678 Module30OperationalStatus "Operational Status of Module 30 in this High Voltage Energy Storage System (or Pack 1 in systems with only one pack).  Not Operational is used when the module is initializing or not able to function (e.g. internal module level monitors have failed) ...";
CM_ SG_ 2364647678 Module29OperationalStatus "Operational Status of Module 29 in this High Voltage Energy Storage System (or Pack 1 in systems with only one pack).  Not Operational is used when the module is initializing or not able to function (e.g. internal module level monitors have failed) ...";
CM_ SG_ 2364647678 Module28OperationalStatus "Operational Status of Module 28 in this High Voltage Energy Storage System (or Pack 1 in systems with only one pack).  Not Operational is used when the module is initializing or not able to function (e.g. internal module level monitors have failed) ...";
CM_ SG_ 2364647678 Module27OperationalStatus "Operational Status of Module 27 in this High Voltage Energy Storage System (or Pack 1 in systems with only one pack).  Not Operational is used when the module is initializing or not able to function (e.g. internal module level monitors have failed) ...";
CM_ SG_ 2364647678 Module26OperationalStatus "Operational Status of Module 26 in this High Voltage Energy Storage System (or Pack 1 in systems with only one pack).  Not Operational is used when the module is initializing or not able to function (e.g. internal module level monitors have failed) ...";
CM_ SG_ 2364647678 Module25OperationalStatus "Operational Status of Module 25 in this High Voltage Energy Storage System (or Pack 1 in systems with only one pack).  Not Operational is used when the module is initializing or not able to function (e.g. internal module level monitors have failed) ...";
CM_ SG_ 2364647678 Module24OperationalStatus "Operational Status of Module 24 in this High Voltage Energy Storage System (or Pack 1 in systems with only one pack).  Not Operational is used when the module is initializing or not able to function (e.g. internal module level monitors have failed) ...";
CM_ SG_ 2364647678 Module23OperationalStatus "Operational Status of Module 23 in this High Voltage Energy Storage System (or Pack 1 in systems with only one pack).  Not Operational is used when the module is initializing or not able to function (e.g. internal module level monitors have failed) ...";
CM_ SG_ 2364647678 Module22OperationalStatus "Operational Status of Module 22 in this High Voltage Energy Storage System (or Pack 1 in systems with only one pack).  Not Operational is used when the module is initializing or not able to function (e.g. internal module level monitors have failed) ...";
CM_ SG_ 2364647678 Module21OperationalStatus "Operational Status of Module 21 in this High Voltage Energy Storage System (or Pack 1 in systems with only one pack).  Not Operational is used when the module is initializing or not able to function (e.g. internal module level monitors have failed) ...";
CM_ SG_ 2364647678 Module20OperationalStatus "Operational Status of Module 20 in this High Voltage Energy Storage System (or Pack 1 in systems with only one pack).  Not Operational is used when the module is initializing or not able to function (e.g. internal module level monitors have failed) ...";
CM_ SG_ 2364647678 Module19OperationalStatus "Operational Status of Module 19 in this High Voltage Energy Storage System (or Pack 1 in systems with only one pack).  Not Operational is used when the module is initializing or not able to function (e.g. internal module level monitors have failed) ...";
CM_ SG_ 2364647678 Module18OperationalStatus "Operational Status of Module 18 in this High Voltage Energy Storage System (or Pack 1 in systems with only one pack).  Not Operational is used when the module is initializing or not able to function (e.g. internal module level monitors have failed) ...";
CM_ SG_ 2364647678 Module17OperationalStatus "Operational Status of Module 17 in this High Voltage Energy Storage System (or Pack 1 in systems with only one pack).  Not Operational is used when the module is initializing or not able to function (e.g. internal module level monitors have failed) ...";
CM_ SG_ 2364647678 Module16OperationalStatus "Operational Status of Module 16 in this High Voltage Energy Storage Pack Instance.  Not Operational is used when the module is initializing or not able to function (e.g. internal module level monitors have failed).  Operational indicates that the ...";
CM_ SG_ 2364647678 Module15OperationalStatus "Operational Status of Module 15 in this High Voltage Energy Storage Pack Instance.  Not Operational is used when the module is initializing or not able to function (e.g. internal module level monitors have failed).  Operational indicates that the ...";
CM_ SG_ 2364647678 Module14OperationalStatus "Operational Status of Module 14 in this High Voltage Energy Storage Pack Instance.  Not Operational is used when the module is initializing or not able to function (e.g. internal module level monitors have failed).  Operational indicates that the ...";
CM_ SG_ 2364647678 Module13OperationalStatus "Operational Status of Module 13 in this High Voltage Energy Storage Pack Instance.  Not Operational is used when the module is initializing or not able to function (e.g. internal module level monitors have failed).  Operational indicates that the ...";
CM_ SG_ 2364647678 Module12OperationalStatus "Operational Status of Module 12 in this High Voltage Energy Storage Pack Instance.  Not Operational is used when the module is initializing or not able to function (e.g. internal module level monitors have failed).  Operational indicates that the ...";
CM_ SG_ 2364647678 Module11OperationalStatus "Operational Status of Module 11 in this High Voltage Energy Storage Pack Instance.  Not Operational is used when the module is initializing or not able to function (e.g. internal module level monitors have failed).  Operational indicates that the ...";
CM_ SG_ 2364647678 Module10OperationalStatus "Operational Status of Module 10 in this High Voltage Energy Storage Pack Instance.  Not Operational is used when the module is initializing or not able to function (e.g. internal module level monitors have failed).  Operational indicates that the ...";
CM_ SG_ 2364647678 Module9OperationalStatus "Operational Status of Module 9 in this High Voltage Energy Storage Pack Instance.  Not Operational is used when the module is initializing or not able to function (e.g. internal module level monitors have failed).  Operational indicates that the ...";
CM_ SG_ 2364647678 Module8OperationalStatus "Operational Status of Module 8 in this High Voltage Energy Storage Pack Instance.  Not Operational is used when the module is initializing or not able to function (e.g. internal module level monitors have failed).  Operational indicates that the ...";
CM_ SG_ 2364647678 Module7OperationalStatus "Operational Status of Module 7 in this High Voltage Energy Storage Pack Instance.  Not Operational is used when the module is initializing or not able to function (e.g. internal module level monitors have failed).  Operational indicates that the ...";
CM_ SG_ 2364647678 Module6OperationalStatus "Operational Status of Module 6 in this High Voltage Energy Storage Pack Instance.  Not Operational is used when the module is initializing or not able to function (e.g. internal module level monitors have failed).  Operational indicates that the ...";
CM_ SG_ 2364647678 Module5OperationalStatus "Operational Status of Module 5 in this High Voltage Energy Storage Pack Instance.  Not Operational is used when the module is initializing or not able to function (e.g. internal module level monitors have failed).  Operational indicates that the ...";
CM_ SG_ 2364647678 Module4OperationalStatus "Operational Status of Module 4 in this High Voltage Energy Storage Pack Instance.  Not Operational is used when the module is initializing or not able to function (e.g. internal module level monitors have failed).  Operational indicates that the ...";
CM_ SG_ 2364647678 Module3OperationalStatus "Operational Status of Module 3 in this High Voltage Energy Storage Pack Instance.  Not Operational is used when the module is initializing or not able to function (e.g. internal module level monitors have failed).  Operational indicates that the ...";
CM_ SG_ 2364647678 Module2OperationalStatus "Operational Status of Module 2 in this High Voltage Energy Storage Pack Instance.  Not Operational is used when the module is initializing or not able to function (e.g. internal module level monitors have failed).  Operational indicates that the ...";
CM_ SG_ 2364647678 Module1OperationalStatus "Operational Status of Module 1 in this High Voltage Energy Storage Pack Instance.  Not Operational is used when the module is initializing or not able to function (e.g. internal module level monitors have failed).  Operational indicates that the ...";
CM_ BO_ 2364647422 "High Voltage Energy Storage Pack 2 Data 7
Data set 7 (electrical) for High Voltage Energy Storage Pack 2.";
CM_ SG_ 2364647422 MaxChargeVLmt "The maximum voltage level not to be exceeded while charging this High Voltage Energy Storage Pack instance.  If this parameter is not supported, the maximum charge voltage should be limited to SPN 11250 (HVESP2 Recommended Maximum Operating ...";
CM_ SG_ 2364647422 ChargeEnergyCapacity "The amount of unused electrical energy storage available to be filled by charging this High Voltage Energy Storage Pack instance, i.e. “how much empty space is remaining in the tank”.  See SPN 11179 (HVESP2 Charge Capacity) for Ampere-hours (Ah).
 ...";
CM_ SG_ 2364647422 DisEnergyCapacity "The amount of stored electrical energy in this High Voltage Energy Storage Pack instance that is available for use by the hybrid system, i.e. “how full is the tank”.  See SPN 11178 (HVESP2 Discharge Capacity) for Ampere-hours (Ah).
This parameter ...";
CM_ BO_ 2364647166 "High Voltage Energy Storage Pack 2 Status 1
Status data set 1 for High Voltage Energy Storage Pack 2.";
CM_ SG_ 2364647166 Status1CRC "The CRC is defined as follows:
• Length: 8 bits
• Polynomial: x^8+x^5+x^3+x^2+x+1
• Initial Value: FFh
• Input Data Reflection: Not reflected
• Result Data Reflection: Not reflected
• XOR value: FFh
SAE makes no claim of the functional safety ...";
CM_ SG_ 2364647166 Status1Counter "The message counter is used to detect situations where the transmitting ECU malfunction repeats the same frame all the time. The receiver of the information may use the counter parameter to detect this situation. The transmitting device will ...";
CM_ SG_ 2364647166 OperationalStatus "Provides feedback on where this High Voltage Energy Storage Pack instance is in its operating spectrum, and includes feedback in response to the Operation Consent [i.e. SPN 11151 (HVESP2 Operation Consent)] and Power Down Command [i.e. SPN 11146 ...";
CM_ SG_ 2364647166 HVBusConnectionStatus "This parameter provides high level feedback on this High Voltage Energy Storage Pack instance high voltage bus connection.  For specific contactor information, see SPN 11191 (HVESP2 High-Voltage Bus (Positive) Contactor State), SPN 11192 (HVESP2 ...";
CM_ SG_ 2364647166 InternalChargerStatus "Indicates that the charger in this HVES instance is on.  External chargers may use the External Energy Source Connection Status (SPN 7898) and related SPs.
This parameter is for one of multiple packs in an HVESS. If there is only one pack in the ...";
CM_ SG_ 2364647166 CellBalancingActive "Indicates whether or not the cells in this High Voltage Energy Storage Pack instance are currently being balanced.
This parameter is for one of multiple packs in an HVESS.  If there is only one pack in the system, the HVESS parameters should be ...";
CM_ SG_ 2364647166 CellBalanceStatus "Indicates whether or not the cells in this High Voltage Energy Storage Pack instance are balanced.
This parameter is for one of multiple packs in an HVESS.  If there is only one pack in the system, the HVESS parameters should be used. If there are ...";
CM_ SG_ 2364647166 StOfChargeStatus "Status of this High Voltage Energy Storage Pack instance State of Charge (SOC).  Note:  A given HVES controller may not support all of the states.
This parameter is for one of multiple packs in an HVESS.  If there is only one pack in the system, ...";
CM_ SG_ 2364647166 InertiaSwStatus "Switch indicating that an impact has been sensed by this High Voltage Energy Storage Pack instance. The impact indication may require action by another controller, or by this HVES instance itself.  For example, a controller may elect to take this ...";
CM_ SG_ 2364647166 HVILStatus "Status of the High Voltage Interlock Loop from the viewpoint of this High Voltage Energy Storage Pack instance.
This parameter is for one of multiple packs in an HVESS. If there is only one pack in the system, the HVESS parameters should be used ...";
CM_ SG_ 2364647166 HVBusPassiveIsolTestStatus "Status of the high-voltage bus electrical passive isolation test as performed by this High Voltage Energy Storage Pack instance.
This parameter is for one of multiple packs in an HVESS. If there is only one pack in the system, the HVESS parameters ...";
CM_ SG_ 2364647166 HVBusActiveIsolTestStatus "Status of the high-voltage bus electrical active isolation test as performed by this High Voltage Energy Storage Pack instance.
This parameter is for one of multiple packs in an HVESS. If there is only one pack in the system, the HVESS parameters ...";
CM_ SG_ 2364647166 CenterOfPackContactorSt "Position of the center high-voltage contactor.  When this contactor is closed, the positive half of this High Voltage Energy Storage Pack instance is connected to the negative half.  If a system controls the positive, negative, and center contactors ...";
CM_ SG_ 2364647166 HVBusPreChargeRelaySt "Position of the high-voltage bus contactor pre-charge relay.  When this relay is closed, this High Voltage Energy Storage Pack instance is bringing the high-voltage bus up to its operating level.
This parameter is for one of multiple packs in an ...";
CM_ SG_ 2364647166 HVBusDisconnectForewarning "Indicates that this High Voltage Energy Storage Pack instance is about to disconnect from the high voltage bus due to unacceptable conditions.
This parameter is for one of multiple packs in an HVESS. If there is only one pack in the system, the ...";
CM_ SG_ 2364647166 HVBusContactorSt11192 "Position of this High Voltage Energy Storage Pack instance negative side bus contactor.  When this contactor is closed, the negative side of this HVES instance is connected to the negative side of the high-voltage bus.  If a system controls the ...";
CM_ SG_ 2364647166 HVBusContactorSt "Position of this High Voltage Energy Storage Pack instance positive side bus contactor.  When this contactor is closed, the positive side of this HVES instance is connected to the positive side of the high-voltage bus.  In systems where all ...";
CM_ BO_ 2364646910 "High Voltage Energy Storage Pack 2 Data 6
Data set 6 (external or interface data) for High Voltage Energy Storage Pack 2.";
CM_ SG_ 2364646910 Temp "The temperature of this High Voltage Energy Storage Pack instance. The value may be determined from a unique sensor specifically for this purpose, or by aggregating various temperature sensor readings within the pack.
This parameter is for one of ...";
CM_ SG_ 2364646910 ETemp "The temperature of the electronics or control modules in this High Voltage Energy Storage Pack instance.  If there are multiple temperature sensors then this parameter would be set to the maximum sensor reading.
This parameter is for one of ...";
CM_ SG_ 2364646910 OutCoolantTemp "The temperature of liquid coolant as it exits this High Voltage Energy Storage Pack instance.
This parameter is for one of multiple packs in an HVESS.  If there is only one pack in the system, the HVESS parameters should be used. If there are ...";
CM_ SG_ 2364646910 InCoolantTemp "The temperature of liquid coolant as it enters this High Voltage Energy Storage Pack instance.
This parameter is for one of multiple packs in an HVESS.  If there is only one pack in the system, the HVESS parameters should be used. If there are ...";
CM_ SG_ 2364646910 IgntV "The voltage level at the ignition input of this High Voltage Energy Storage Pack controller.
This parameter is for one of multiple packs in an HVESS.  If there is only one pack in the system, the HVESS parameters should be used.  If there are ...";
CM_ SG_ 2364646910 BusV "The voltage level of the high voltage bus, as measured by this High Voltage Energy Storage Pack instance on the bus side (not the battery side) of its contactors.
This parameter is for one of multiple packs in an HVESS.  If there is only one pack ...";
CM_ BO_ 2364646654 "High Voltage Energy Storage Pack 2 Data 5
Data set 5 (electrical data) for High Voltage Energy Storage Pack 2.";
CM_ SG_ 2364646654 HighestCellStOfCharge "Indicates the state of charge of the highest-charged cell in this High Voltage Energy Storage Pack instance.  0% means no charge remaining, 100% means the cell is fully charged.  If a single state of charge value covers more than one cell, the value ...";
CM_ SG_ 2364646654 LowestCellStOfCharge "Indicates the state of charge of the lowest-charged cell in this High Voltage Energy Storage Pack instance.  0% means no charge remaining, 100% means the cell is fully charged.   If a single state of charge value covers more than one cell, the value ...";
CM_ SG_ 2364646654 ChargeCurLmt "The maximum instantaneous current flow limit into this High Voltage Energy Storage Pack instance. This parameter is defined from the high voltage energy storage pack's point of view and should reflect the instantaneous capability of the pack.  The ...";
CM_ SG_ 2364646654 DisCurLmt "The maximum instantaneous current flow limit out of this High Voltage Energy Storage Pack instance. This parameter is defined from the high voltage energy storage pack's point of view and should reflect the instantaneous capability of the pack.  The ...";
CM_ BO_ 2364646398 "High Voltage Energy Storage Pack 2 Data 4
Data set 4 (electrical data) for High Voltage Energy Storage Pack 2.";
CM_ SG_ 2364646398 CellBalancingCount "The number of cells that are currently being balanced in this High Voltage Energy Storage Pack instance.
This parameter is for one of multiple packs in an HVESS.  If there is only one pack in the system, the HVESS parameters should be used.  If ...";
CM_ SG_ 2364646398 ChargeCapacity "The amount of unused electrical charge storage in this High Voltage Energy Storage Pack instance that is available to be filled by charging, i.e. “how much empty space is remaining in the tank”.  See SPN 11207 (HVESP2 Charge Energy Capacity) for ...";
CM_ SG_ 2364646398 DisCapacity "The amount of stored electrical charge in this High Voltage Energy Storage Pack instance that is available for use by the hybrid system, i.e. “how full is the tank”.  See SPN 11206 (HVESP2 Discharge Energy Capacity) for kilowatt-hours (kWh).
This ...";
CM_ BO_ 2364646142 "High Voltage Energy Storage Pack 2 Data 3
Data set 3 (thermal data) for High Voltage Energy Storage Pack 2.";
CM_ SG_ 2364646142 CellTempDiffStatus "Indicates whether or not the differential between the highest and lowest cell temperatures are within acceptable limits per this High Voltage Energy Storage Pack instance.  The actual temperature differential can be calculated by subtracting SPN ...";
CM_ SG_ 2364646142 AvgCellTemp "The average temperature level of all cells in this High Voltage Energy Storage Pack instance.
This parameter is for one of multiple packs in an HVESS.  If there is only one pack in the system, the HVESS parameters should be used.  If there are ...";
CM_ SG_ 2364646142 LowestCellTemp "The lowest temperature level reported by any cell in this High Voltage Energy Storage Pack instance.  If a single temperature sensor covers more than one cell, the value in this parameter is for the smallest group of cells measured.  See SPN 11238 ...";
CM_ SG_ 2364646142 HighestCellTemp "The highest temperature level reported by any cell in this High Voltage Energy Storage Pack instance.  If a single temperature sensor covers more than one cell, the value in this parameter is for the smallest group of cells measured.   See SPN 11236 ...";
CM_ BO_ 2364645886 "High Voltage Energy Storage Pack 2 Data 2
Data set 2 (electrical data) for High Voltage Energy Storage Pack 2.";
CM_ SG_ 2364645886 CellVDiffStatus "Indicates whether or not the differential between the highest and lowest cell voltages are within acceptable limits, according to this High Voltage Energy Storage Pack instance. The actual voltage differential can be calculated by subtracting SPN ...";
CM_ SG_ 2364645886 LowestCellV "The lowest voltage level reported by any cell in this High Voltage Energy Storage Pack instance. If a single voltage sensor covers more than one cell, the value in this parameter is for the smallest group of cells measured.  See SPN 11233 (HVESP2 ...";
CM_ SG_ 2364645886 HighestCellV "The highest voltage level reported by any cell in this High Voltage Energy Storage Pack instance. If a single voltage sensor covers more than one cell, the value in this parameter is for the smallest group of cells measured. See SPN 11231 (HVESP2 ...";
CM_ SG_ 2364645886 FastUpdateStOfCharge "Indicates this High Voltage Energy Storage Pack instance state of charge.  0% means no charge remaining, 100% means the system is fully charged in terms of physical limits of this energy storage pack instance.  Acceptable state of charge upper and ...";
CM_ BO_ 2364645630 "High Voltage Energy Storage Pack 2 Data 1
Data set 1 (electrical data) for High Voltage Energy Storage Pack 2.";
CM_ SG_ 2364645630 Cur "The current in or out of this High Voltage Energy Storage Pack instance. This parameter should be synchronized with SPN 11168 (HVESP2 Voltage Level) such that a realized power value can be calculated.  This parameter is defined from the high voltage ...";
CM_ SG_ 2364645630 Lvl "The voltage level of this High Voltage Energy Storage Pack instance. This parameter should be synchronized with SPN 11169 (HVESP2 Current) such that a realized power value can be calculated.  If the HVES component physically contains the contactors ...";
CM_ SG_ 2364645630 AvailableChargePwr "The rate at which this High Voltage Energy Storage Pack instance can currently receive energy from a regenerative or recharging system.
This parameter is for one of multiple packs in an HVESS.  If there is only one pack in the system, the HVESS ...";
CM_ SG_ 2364645630 AvailableDisPwr "The rate at which this High Voltage Energy Storage Pack instance can currently provide energy for propulsion or other uses.
This parameter is for one of multiple packs in an HVESS.  If there is only one pack in the system, the HVESS parameters ...";
CM_ BO_ 2364645374 "High Voltage Energy Storage Pack 2 Status 2
Status data set 2 for High Voltage Energy Storage Pack 2.";
CM_ SG_ 2364645374 ChargePLDueToAnUndefinedCause "Indicates whether or not charge power of this HVES instance is being limited due to an undefined cause.
This parameter is for one of multiple packs in an HVESS.  If there is only one pack in the system, the HVESS parameters should be used. If there ...";
CM_ SG_ 2364645374 ChargePLDueToBatCur "Indicates whether or not charge power of this HVES instance is being limited due to battery current.
This parameter is for one of multiple packs in an HVESS.  If there is only one pack in the system, the HVESS parameters should be used. If there ...";
CM_ SG_ 2364645374 ChargePLDueToBatOrCellV "Indicates whether or not charge power of this HVES instance is being limited due to a battery or cell voltage level.
This parameter is for one of multiple packs in an HVESS.  If there is only one pack in the system, the HVESS parameters should be ...";
CM_ SG_ 2364645374 ChargePLDueToBatDiagCondition "Indicates whether or not charge power of this HVES instance is being limited due to a battery diagnostic condition.
This parameter is for one of multiple packs in an HVESS.  If there is only one pack in the system, the HVESS parameters should be ...";
CM_ SG_ 2364645374 ChargePLDueToBatTemp "Indicates whether or not charge power of this HVES instance is being limited due to battery temperature.
This parameter is for one of multiple packs in an HVESS.  If there is only one pack in the system, the HVESS parameters should be used. If ...";
CM_ SG_ 2364645374 ChargePLDueToStOfCharge "Indicates whether or not charge power of this HVES instance is being limited due to state of charge.
This parameter is for one of multiple packs in an HVESS.  If there is only one pack in the system, the HVESS parameters should be used. If there ...";
CM_ SG_ 2364645374 DisPLDueToAnUndefinedCause "Indicates whether or not discharge power of this HVES instance is being limited due to an undefined cause.
This parameter is for one of multiple packs in an HVESS.  If there is only one pack in the system, the HVESS parameters should be used. If ...";
CM_ SG_ 2364645374 DisPLDueToBatCur "Indicates whether or not discharge power of this HVES instance is being limited due to battery current.
This parameter is for one of multiple packs in an HVESS.  If there is only one pack in the system, the HVESS parameters should be used. If there ...";
CM_ SG_ 2364645374 DisPLDueToBatOrCellV "Indicates whether or not discharge power of this HVES instance is being limited due to a battery or cell voltage level.
This parameter is for one of multiple packs in an HVESS.  If there is only one pack in the system, the HVESS parameters should ...";
CM_ SG_ 2364645374 DisPLDueToBatDiagCondition "Indicates whether or not discharge power of this HVES instance is being limited due to a battery diagnostic condition.
This parameter is for one of multiple packs in an HVESS.  If there is only one pack in the system, the HVESS parameters should be ...";
CM_ SG_ 2364645374 DisPLDueToBatTemp "Indicates whether or not discharge power of this HVES instance is being limited due to battery temperature.
This parameter is for one of multiple packs in an HVESS.  If there is only one pack in the system, the HVESS parameters should be used. If ...";
CM_ SG_ 2364645374 DisPLDueToStOfCharge "Indicates whether or not discharge power of this HVES instance is being limited due to state of charge.
This parameter is for one of multiple packs in an HVESS.  If there is only one pack in the system, the HVESS parameters should be used. If there ...";
CM_ BO_ 2364645118 "High Voltage Energy Storage Pack 1 Data 11
Data set 11 (electrical data) for High Voltage Energy Storage Pack 1.";
CM_ SG_ 2364645118 ActualChargeRate "This signal represents the actual present charge rate of this High Voltage Energy Storage Pack instance.
This parameter is for one of multiple packs in an HVESS. If there is only one pack in the system, the HVESS parameters should be used. If there ...";
CM_ SG_ 2364645118 LvlNegToChassisGroundV "Voltage difference between the most negative terminal of the HVES battery and chassis measured at the battery side of any HVES contained output contactor.  This voltage may be used for system level monitoring of battery shorts to chassis within the ...";
CM_ SG_ 2364645118 BusVNegToChassisGroundV "Voltage difference between the most negative terminal of the HVES battery and chassis measured on the hybrid system bus side (not the battery side) of any HVES contained output contactor.  This voltage may be used for system level monitoring of ...";
CM_ BO_ 2364644862 "High Voltage Energy Storage Pack 1 Data 10
Data set 10 (electrical) for High Voltage Energy Storage Pack 1.";
CM_ SG_ 2364644862 HVBusPassiveIsolTestResults "The isolation resistance expressed in Ohms per Volt that resulted from the High-Voltage Bus Passive Isolation Test.
See SPN 11081 (HVESP1 High-Voltage Bus Passive Isolation Test Status) for test status and SPN 11032 (HVESP1 High-Voltage Bus Passive ...";
CM_ SG_ 2364644862 HVBusActiveIsolTestResults "The isolation resistance expressed in Ohms per Volt that resulted from the High-Voltage Bus Active Isolation Test.
See SPN 11080 (HVESP1 High-Voltage Bus Active Isolation Test Status) for test status and SPN 11031 (HVESP1 High-Voltage Bus Active ...";
CM_ SG_ 2364644862 LowestCellStOfChargeCellNum "Identifies the location of SPN 11067 (HVESP1 Lowest Cell State of Charge) within SPN 11126 (HVESP1 Lowest Cell State of Charge Module Number).
This parameter is for one of multiple packs in an HVESS.  If there is only one pack in the system, the ...";
CM_ SG_ 2364644862 LowestCellStOfChargeModuleNum "Identifies the location of the module containing SPN 11067 (HVESP1 Lowest Cell State of Charge).
This parameter is for one of multiple packs in an HVESS.  If there is only one pack in the system, the HVESS parameters should be used. If there are ...";
CM_ SG_ 2364644862 HighestCellStOfChargeCellNum "Identifies the location of SPN 11068 (HVESP1 Highest Cell State of Charge) within SPN 11124 (HVESP1 Highest Cell State of Charge Module Number).
This parameter is for one of multiple packs in an HVESS.  If there is only one pack in the system, the ...";
CM_ SG_ 2364644862 HighestCellStOfChargeModuleNum "Identifies the location of the module containing SPN 11068 (HVESP1 Highest Cell State of Charge).
This parameter is for one of multiple packs in an HVESS.  If there is only one pack in the system, the HVESS parameters should be used. If there are ...";
CM_ BO_ 2364644606 "High Voltage Energy Storage Pack 1 Data 9
Data set 9 (thermal) for High Voltage Energy Storage Pack 1.";
CM_ SG_ 2364644606 Data9CRC "The CRC is defined as follows:
• Length: 8 bits
• Polynomial: x^8+x^5+x^3+x^2+x+1
• Initial Value: FFh
• Input Data Reflection: Not reflected
• Result Data Reflection: Not reflected
• XOR value: FFh
SAE makes no claim of the functional safety ...";
CM_ SG_ 2364644606 Data9Counter "The message counter is used to detect situations where the transmitting ECU malfunction repeats the same frame all the time. The receiver of the information may use the counter parameter to detect this situation. The transmitting device will ...";
CM_ SG_ 2364644606 Data9EmbeddedIntegritySupport "Indicates SPN 22976 (HVESP1 Data 9 CRC) and SPN 22975 (HVESP1 Data 9 Counter) are supported by the sender.
00b = Embedded CRC and Counter are supported by the sender
01b = Protection is supported using J1939-76 SHM
10b = Reserved
11b = CRC and ...";
CM_ SG_ 2364644606 HVESS1ThermalEventDetected "A sensor has detected the presence of a thermal event at or near High Voltage Energy Storage Pack instance.
00b = No Thermal Event Detected
01b = Thermal Event Detected
10b = Error
11b = Not available
This parameter is for one of multiple packs ...";
CM_ SG_ 2364644606 LowestCellTempCellNum "Identifies the location of SPN 11059 (HVESP1 Lowest Cell Temperature) within SPN 11122 (HVESP1 Lowest Cell Temperature Module Number).
This parameter is for one of multiple packs in an HVESS.  If there is only one pack in the system, the HVESS ...";
CM_ SG_ 2364644606 LowestCellTempModuleNum "Identifies the location of the module containing SPN 11059 (HVESP1 Lowest Cell Temperature).
This parameter is for one of multiple packs in an HVESS.  If there is only one pack in the system, the HVESS parameters should be used. If there are ...";
CM_ SG_ 2364644606 HighestCellTempCellNum "Identifies the location of SPN 11058 (HVESP1 Highest Cell Temperature) within SPN 11120 (HVESP1 Highest Cell Temperature Module Number).
This parameter is for one of multiple packs in an HVESS.  If there is only one pack in the system, the HVESS ...";
CM_ SG_ 2364644606 HighestCellTempModuleNum "Identifies the location of the module containing SPN 11058 (HVESP1 Highest Cell Temperature).
This parameter is for one of multiple packs in an HVESS.  If there is only one pack in the system, the HVESS parameters should be used. If there are ...";
CM_ BO_ 2364644350 "High Voltage Energy Storage Pack 1 Data 8
Data set 8 (electrical data) for High Voltage Energy Storage Pack 1.";
CM_ SG_ 2364644350 AvgCellV "The average cell voltage in this High Voltage Energy Storage Pack instance.
This parameter is for one of multiple packs in an HVESS.  If there is only one pack in the system, the HVESS parameters should be used. If there are multiple packs in the ...";
CM_ SG_ 2364644350 LowestCellVCellNum "Identifies the location of SPN 11056 (HVESP1 Lowest Cell Voltage) within SPN 11117 (HVESP1 Lowest Cell Voltage Module Number).
This parameter is for one of multiple packs in an HVESS.  If there is only one pack in the system, the HVESS parameters ...";
CM_ SG_ 2364644350 LowestCellVModuleNum "Identifies the location of the module containing SPN 11056 (HVESP1 Lowest Cell Voltage).
This parameter is for one of multiple packs in an HVESS.  If there is only one pack in the system, the HVESS parameters should be used. If there are multiple ...";
CM_ SG_ 2364644350 HighestCellVCellNum "Identifies the location of SPN 11055 (HVESP1 Highest Cell Voltage) within SPN 11115 (HVESP1 Highest Cell Voltage Module Number).
This parameter is for one of multiple packs in an HVESS.  If there is only one pack in the system, the HVESS parameters ...";
CM_ SG_ 2364644350 HighestCellVModuleNum "Identifies the location of the module containing SPN 11055 (HVESP1 Highest Cell Voltage).
This parameter is for one of multiple packs in an HVESS.  If there is only one pack in the system, the HVESS parameters should be used. If there are multiple ...";
CM_ BO_ 2364644094 "High Voltage Energy Storage Pack 1 Thermal Management System Status 1
Collection of data the High Voltage Energy Storage Pack 1 Thermal Management System sends to the Hybrid Controller.";
CM_ SG_ 2364644094 TMSCoolantLvl "Indicates the coolant level in this HVES Thermal Management System (TMS).
This parameter is for one of multiple packs in an HVESS.  If there is only one pack in the system, the HVESS parameters should be used. If there are multiple packs in the ...";
CM_ SG_ 2364644094 TMSMode "Indicates the operating mode of the Thermal Management System.  The heat transfer medium may be (e.g. liquid or air).  The cooling system may be fans, liquid coolant, or a combination of mediums.  The system may include an air and/or liquid ...";
CM_ SG_ 2364644094 TMSHVILStatus "In multiple HVES configurations, this is the status of the High Voltage Interlock Loop from the viewpoint of this Thermal Management System.
00b = HVIL Closed
01b = HVIL Open
10b = Error
11b = Not Available
This parameter is for one of multiple ...";
CM_ SG_ 2364644094 TMSHtrStatus "The state of this High Voltage Energy Storage Pack heater
This parameter is for one of multiple packs in an HVESS.  If there is only one pack in the system, the HVESS parameters should be used. If there are multiple packs in the system, then both ...";
CM_ SG_ 2364644094 TMSRelHumidty "When this High Voltage Energy Storage Pack Thermal Management System is equipped with a relative humidity sensor, this is the  measured Relative Humidity.
This parameter is for one of multiple packs in an HVESS.  If there is only one pack in the ...";
CM_ SG_ 2364644094 TMSCompressorSpd "When this High Voltage Energy Storage Pack Thermal Management System is equipped with an active cooling system (e.g. air conditioner), this is the Compressor Speed.
This parameter is for one of multiple packs in an HVESS.  If there is only one pack ...";
CM_ SG_ 2364644094 TMSHVInputPwr "This is the high-voltage power consumed by this HVES Thermal Management System (TMS).
This parameter is for one of multiple packs in an HVESS.  If there is only one pack in the system, the HVESS parameters should be used. If there are multiple ...";
CM_ SG_ 2364644094 TMSSLIInputPwr "This is the low-voltage power consumed by this HVES Thermal Management System (TMS).
This parameter is for one of multiple packs in an HVESS.  If there is only one pack in the system, the HVESS parameters should be used.  If there are multiple ...";
CM_ BO_ 2364643838 "High Voltage Energy Storage Pack 1 Module Status 1
Module Status message 1 for High Voltage Energy Storage Pack 1.";
CM_ SG_ 2364643838 Module32OperationalStatus "Operational Status of Module 32 in this High Voltage Energy Storage System (or Pack 1 in systems with only one pack).  Not Operational is used when the module is initializing or not able to function (e.g. internal module level monitors have failed) ...";
CM_ SG_ 2364643838 Module31OperationalStatus "Operational Status of Module 31 in this High Voltage Energy Storage System (or Pack 1 in systems with only one pack).  Not Operational is used when the module is initializing or not able to function (e.g. internal module level monitors have failed) ...";
CM_ SG_ 2364643838 Module30OperationalStatus "Operational Status of Module 30 in this High Voltage Energy Storage System (or Pack 1 in systems with only one pack).  Not Operational is used when the module is initializing or not able to function (e.g. internal module level monitors have failed) ...";
CM_ SG_ 2364643838 Module29OperationalStatus "Operational Status of Module 29 in this High Voltage Energy Storage System (or Pack 1 in systems with only one pack).  Not Operational is used when the module is initializing or not able to function (e.g. internal module level monitors have failed) ...";
CM_ SG_ 2364643838 Module28OperationalStatus "Operational Status of Module 28 in this High Voltage Energy Storage System (or Pack 1 in systems with only one pack).  Not Operational is used when the module is initializing or not able to function (e.g. internal module level monitors have failed) ...";
CM_ SG_ 2364643838 Module27OperationalStatus "Operational Status of Module 27 in this High Voltage Energy Storage System (or Pack 1 in systems with only one pack).  Not Operational is used when the module is initializing or not able to function (e.g. internal module level monitors have failed) ...";
CM_ SG_ 2364643838 Module26OperationalStatus "Operational Status of Module 26 in this High Voltage Energy Storage System (or Pack 1 in systems with only one pack).  Not Operational is used when the module is initializing or not able to function (e.g. internal module level monitors have failed) ...";
CM_ SG_ 2364643838 Module25OperationalStatus "Operational Status of Module 25 in this High Voltage Energy Storage System (or Pack 1 in systems with only one pack).  Not Operational is used when the module is initializing or not able to function (e.g. internal module level monitors have failed) ...";
CM_ SG_ 2364643838 Module24OperationalStatus "Operational Status of Module 24 in this High Voltage Energy Storage System (or Pack 1 in systems with only one pack).  Not Operational is used when the module is initializing or not able to function (e.g. internal module level monitors have failed) ...";
CM_ SG_ 2364643838 Module23OperationalStatus "Operational Status of Module 23 in this High Voltage Energy Storage System (or Pack 1 in systems with only one pack).  Not Operational is used when the module is initializing or not able to function (e.g. internal module level monitors have failed) ...";
CM_ SG_ 2364643838 Module22OperationalStatus "Operational Status of Module 22 in this High Voltage Energy Storage System (or Pack 1 in systems with only one pack).  Not Operational is used when the module is initializing or not able to function (e.g. internal module level monitors have failed) ...";
CM_ SG_ 2364643838 Module21OperationalStatus "Operational Status of Module 21 in this High Voltage Energy Storage System (or Pack 1 in systems with only one pack).  Not Operational is used when the module is initializing or not able to function (e.g. internal module level monitors have failed) ...";
CM_ SG_ 2364643838 Module20OperationalStatus "Operational Status of Module 20 in this High Voltage Energy Storage System (or Pack 1 in systems with only one pack).  Not Operational is used when the module is initializing or not able to function (e.g. internal module level monitors have failed) ...";
CM_ SG_ 2364643838 Module19OperationalStatus "Operational Status of Module 19 in this High Voltage Energy Storage System (or Pack 1 in systems with only one pack).  Not Operational is used when the module is initializing or not able to function (e.g. internal module level monitors have failed) ...";
CM_ SG_ 2364643838 Module18OperationalStatus "Operational Status of Module 18 in this High Voltage Energy Storage System (or Pack 1 in systems with only one pack).  Not Operational is used when the module is initializing or not able to function (e.g. internal module level monitors have failed) ...";
CM_ SG_ 2364643838 Module17OperationalStatus "Operational Status of Module 17 in this High Voltage Energy Storage System (or Pack 1 in systems with only one pack).  Not Operational is used when the module is initializing or not able to function (e.g. internal module level monitors have failed) ...";
CM_ SG_ 2364643838 Module16OperationalStatus "Operational Status of Module 16 in this High Voltage Energy Storage Pack Instance.  Not Operational is used when the module is initializing or not able to function (e.g. internal module level monitors have failed).  Operational indicates that the ...";
CM_ SG_ 2364643838 Module15OperationalStatus "Operational Status of Module 15 in this High Voltage Energy Storage Pack Instance.  Not Operational is used when the module is initializing or not able to function (e.g. internal module level monitors have failed).  Operational indicates that the ...";
CM_ SG_ 2364643838 Module14OperationalStatus "Operational Status of Module 14 in this High Voltage Energy Storage Pack Instance.  Not Operational is used when the module is initializing or not able to function (e.g. internal module level monitors have failed).  Operational indicates that the ...";
CM_ SG_ 2364643838 Module13OperationalStatus "Operational Status of Module 13 in this High Voltage Energy Storage Pack Instance.  Not Operational is used when the module is initializing or not able to function (e.g. internal module level monitors have failed).  Operational indicates that the ...";
CM_ SG_ 2364643838 Module12OperationalStatus "Operational Status of Module 12 in this High Voltage Energy Storage Pack Instance.  Not Operational is used when the module is initializing or not able to function (e.g. internal module level monitors have failed).  Operational indicates that the ...";
CM_ SG_ 2364643838 Module11OperationalStatus "Operational Status of Module 11 in this High Voltage Energy Storage Pack Instance.  Not Operational is used when the module is initializing or not able to function (e.g. internal module level monitors have failed).  Operational indicates that the ...";
CM_ SG_ 2364643838 Module10OperationalStatus "Operational Status of Module 10 in this High Voltage Energy Storage Pack Instance.  Not Operational is used when the module is initializing or not able to function (e.g. internal module level monitors have failed).  Operational indicates that the ...";
CM_ SG_ 2364643838 Module9OperationalStatus "Operational Status of Module 9 in this High Voltage Energy Storage Pack Instance.  Not Operational is used when the module is initializing or not able to function (e.g. internal module level monitors have failed).  Operational indicates that the ...";
CM_ SG_ 2364643838 Module8OperationalStatus "Operational Status of Module 8 in this High Voltage Energy Storage Pack Instance.  Not Operational is used when the module is initializing or not able to function (e.g. internal module level monitors have failed).  Operational indicates that the ...";
CM_ SG_ 2364643838 Module7OperationalStatus "Operational Status of Module 7 in this High Voltage Energy Storage Pack Instance.  Not Operational is used when the module is initializing or not able to function (e.g. internal module level monitors have failed).  Operational indicates that the ...";
CM_ SG_ 2364643838 Module6OperationalStatus "Operational Status of Module 6 in this High Voltage Energy Storage Pack Instance.  Not Operational is used when the module is initializing or not able to function (e.g. internal module level monitors have failed).  Operational indicates that the ...";
CM_ SG_ 2364643838 Module5OperationalStatus "Operational Status of Module 5 in this High Voltage Energy Storage Pack Instance.  Not Operational is used when the module is initializing or not able to function (e.g. internal module level monitors have failed).  Operational indicates that the ...";
CM_ SG_ 2364643838 Module4OperationalStatus "Operational Status of Module 4 in this High Voltage Energy Storage Pack Instance.  Not Operational is used when the module is initializing or not able to function (e.g. internal module level monitors have failed).  Operational indicates that the ...";
CM_ SG_ 2364643838 Module3OperationalStatus "Operational Status of Module 3 in this High Voltage Energy Storage Pack Instance.  Not Operational is used when the module is initializing or not able to function (e.g. internal module level monitors have failed).  Operational indicates that the ...";
CM_ SG_ 2364643838 Module2OperationalStatus "Operational Status of Module 2 in this High Voltage Energy Storage Pack Instance.  Not Operational is used when the module is initializing or not able to function (e.g. internal module level monitors have failed).  Operational indicates that the ...";
CM_ SG_ 2364643838 Module1OperationalStatus "Operational Status of Module 1 in this High Voltage Energy Storage Pack Instance.  Not Operational is used when the module is initializing or not able to function (e.g. internal module level monitors have failed).  Operational indicates that the ...";
CM_ BO_ 2364643582 "High Voltage Energy Storage Pack 1 Data 7
Data set 7 (electrical) for High Voltage Energy Storage Pack 1.";
CM_ SG_ 2364643582 MaxChargeVLmt "The maximum voltage level not to be exceeded while charging this High Voltage Energy Storage Pack instance.  If this parameter is not supported, the maximum charge voltage should be limited to SPN 11134 (HVESP1 Recommended Maximum Operating ...";
CM_ SG_ 2364643582 ChargeEnergyCapacity "The amount of unused electrical energy storage available to be filled by charging this High Voltage Energy Storage Pack instance, i.e. “how much empty space is remaining in the tank”.  See SPN 11063 (HVESP1 Charge Capacity) for Ampere-hours (Ah).
 ...";
CM_ SG_ 2364643582 DisEnergyCapacity "The amount of stored electrical energy in this High Voltage Energy Storage Pack instance that is available for use by the hybrid system, i.e. “how full is the tank”.  See SPN 11062 (HVESP1 Discharge Capacity) for Ampere-hours (Ah).
This parameter ...";
BA_DEF_ SG_  "GenSigInactiveValue" INT 0 0;
BA_DEF_ SG_  "SigType" ENUM  "Default","Range","RangeSigned","ASCII","Discrete","Control","ReferencePGN","DTC","StringDelimiter","StringLength","StringLengthControl","MessageCounter","MessageChecksum";
BA_DEF_ SG_  "GenSigStartValue" INT 0 2147483647;
BA_DEF_ SG_  "GenSigSendType" ENUM  "Cyclic","OnWrite","OnWriteWithRepetition","OnChange","OnChangeWithRepetition","IfActive","IfActiveWithRepetition","NoSigSendType";
BA_DEF_ SG_  "GenSigILSupport" ENUM  "No","Yes";
BA_DEF_ SG_  "SPN" INT 0 524287;
BA_DEF_ BO_  "J1939CPgSendTimeout" INT -1 3600000;
BA_DEF_ BO_  "J1939CPgTOS" INT 0 7;
BA_DEF_ BO_  "J1939PgAppearanceOnBus" ENUM  "Default","CAN_Extended","CANFD_Extended";
BA_DEF_ BO_  "FsJ1939UseCrcAndCounter" STRING ;
BA_DEF_ BO_  "TpJ1939VarDlc" ENUM  "No","Yes";
BA_DEF_ BO_  "GenMsgNrOfRepetition" INT 0 1000000;
BA_DEF_ BO_  "GenMsgCycleTimeFast" INT 0 3600000;
BA_DEF_ BO_  "GenMsgFastOnStart" INT 0 100000;
BA_DEF_ BO_  "GenMsgStartDelayTime" INT 0 100000;
BA_DEF_ BO_  "GenMsgILSupport" ENUM  "No","Yes";
BA_DEF_ BO_  "GenMsgDelayTime" INT 0 1000;
BA_DEF_ BO_  "GenMsgRequestable" INT 0 1;
BA_DEF_ BO_  "GenMsgSendType" ENUM  "cyclic","NotUsed","NotUsed","NotUsed","NotUsed","NotUsed","NotUsed","IfActive","noMsgSendType";
BA_DEF_ BO_  "VFrameFormat" ENUM  "StandardCAN","ExtendedCAN","reserved","J1939PG","reserved","reserved","reserved","reserved","reserved","reserved","reserved","reserved","reserved","reserved","StandardCAN_FD","ExtendedCAN_FD";
BA_DEF_ BO_  "SingleFrame" INT 0 1;
BA_DEF_ BO_  "GenMsgCycleTime" INT 0 3600000;
BA_DEF_ SG_  "SystemSignalLongSymbol" STRING ;
BA_DEF_DEF_  "GenSigInactiveValue" 0;
BA_DEF_DEF_  "SigType" "Default";
BA_DEF_DEF_  "GenSigStartValue" 0;
BA_DEF_DEF_  "GenSigSendType" "NoSigSendType";
BA_DEF_DEF_  "GenSigILSupport" "Yes";
BA_DEF_DEF_  "SPN" 0;
BA_DEF_DEF_  "J1939CPgSendTimeout" -1;
BA_DEF_DEF_  "J1939CPgTOS" 2;
BA_DEF_DEF_  "J1939PgAppearanceOnBus" "Default";
BA_DEF_DEF_  "FsJ1939UseCrcAndCounter" "";
BA_DEF_DEF_  "TpJ1939VarDlc" "No";
BA_DEF_DEF_  "GenMsgNrOfRepetition" 0;
BA_DEF_DEF_  "GenMsgCycleTimeFast" 0;
BA_DEF_DEF_  "GenMsgFastOnStart" 0;
BA_DEF_DEF_  "GenMsgStartDelayTime" 0;
BA_DEF_DEF_  "GenMsgILSupport" "Yes";
BA_DEF_DEF_  "GenMsgDelayTime" 0;
BA_DEF_DEF_  "GenMsgRequestable" 1;
BA_DEF_DEF_  "GenMsgSendType" "noMsgSendType";
BA_DEF_DEF_  "VFrameFormat" "J1939PG";
BA_DEF_DEF_  "SingleFrame" 1;
BA_DEF_DEF_  "GenMsgCycleTime" 0;
BA_DEF_DEF_  "SystemSignalLongSymbol" "";
BA_ "GenMsgSendType" BO_ 2364653310 0;
BA_ "GenMsgCycleTime" BO_ 2364653310 20;
BA_ "GenMsgSendType" BO_ 2364653054 0;
BA_ "GenMsgCycleTime" BO_ 2364653054 100;
BA_ "GenMsgSendType" BO_ 2364652798 0;
BA_ "GenMsgCycleTime" BO_ 2364652798 100;
BA_ "GenMsgSendType" BO_ 2364652542 0;
BA_ "GenMsgCycleTime" BO_ 2364652542 100;
BA_ "FsJ1939UseCrcAndCounter" BO_ 2364652286 "Aa";
BA_ "GenMsgSendType" BO_ 2364652286 0;
BA_ "GenMsgCycleTime" BO_ 2364652286 100;
BA_ "GenMsgSendType" BO_ 2364652030 0;
BA_ "GenMsgCycleTime" BO_ 2364652030 100;
BA_ "GenMsgSendType" BO_ 2364651774 0;
BA_ "GenMsgCycleTime" BO_ 2364651774 100;
BA_ "GenMsgSendType" BO_ 2364651518 0;
BA_ "GenMsgCycleTime" BO_ 2364651518 100;
BA_ "GenMsgSendType" BO_ 2364651262 0;
BA_ "GenMsgCycleTime" BO_ 2364651262 100;
BA_ "FsJ1939UseCrcAndCounter" BO_ 2364651006 "Aa";
BA_ "GenMsgDelayTime" BO_ 2364651006 20;
BA_ "GenMsgSendType" BO_ 2364651006 0;
BA_ "GenMsgCycleTime" BO_ 2364651006 100;
BA_ "GenMsgSendType" BO_ 2364650750 0;
BA_ "GenMsgCycleTime" BO_ 2364650750 100;
BA_ "GenMsgSendType" BO_ 2364650494 0;
BA_ "GenMsgCycleTime" BO_ 2364650494 20;
BA_ "GenMsgSendType" BO_ 2364650238 0;
BA_ "GenMsgCycleTime" BO_ 2364650238 100;
BA_ "GenMsgSendType" BO_ 2364649982 0;
BA_ "GenMsgCycleTime" BO_ 2364649982 20;
BA_ "GenMsgSendType" BO_ 2364649726 0;
BA_ "GenMsgCycleTime" BO_ 2364649726 20;
BA_ "GenMsgSendType" BO_ 2364649470 0;
BA_ "GenMsgCycleTime" BO_ 2364649470 20;
BA_ "GenMsgSendType" BO_ 2364649214 0;
BA_ "GenMsgCycleTime" BO_ 2364649214 100;
BA_ "GenMsgSendType" BO_ 2364648958 0;
BA_ "GenMsgCycleTime" BO_ 2364648958 100;
BA_ "GenMsgSendType" BO_ 2364648702 0;
BA_ "GenMsgCycleTime" BO_ 2364648702 100;
BA_ "FsJ1939UseCrcAndCounter" BO_ 2364648446 "Aa";
BA_ "GenMsgSendType" BO_ 2364648446 0;
BA_ "GenMsgCycleTime" BO_ 2364648446 100;
BA_ "GenMsgSendType" BO_ 2364648190 0;
BA_ "GenMsgCycleTime" BO_ 2364648190 100;
BA_ "GenMsgSendType" BO_ 2364647934 0;
BA_ "GenMsgCycleTime" BO_ 2364647934 100;
BA_ "GenMsgSendType" BO_ 2364647678 0;
BA_ "GenMsgCycleTime" BO_ 2364647678 100;
BA_ "GenMsgSendType" BO_ 2364647422 0;
BA_ "GenMsgCycleTime" BO_ 2364647422 100;
BA_ "FsJ1939UseCrcAndCounter" BO_ 2364647166 "Aa";
BA_ "GenMsgDelayTime" BO_ 2364647166 20;
BA_ "GenMsgSendType" BO_ 2364647166 0;
BA_ "GenMsgCycleTime" BO_ 2364647166 100;
BA_ "GenMsgSendType" BO_ 2364646910 0;
BA_ "GenMsgCycleTime" BO_ 2364646910 100;
BA_ "GenMsgSendType" BO_ 2364646654 0;
BA_ "GenMsgCycleTime" BO_ 2364646654 20;
BA_ "GenMsgSendType" BO_ 2364646398 0;
BA_ "GenMsgCycleTime" BO_ 2364646398 100;
BA_ "GenMsgSendType" BO_ 2364646142 0;
BA_ "GenMsgCycleTime" BO_ 2364646142 20;
BA_ "GenMsgSendType" BO_ 2364645886 0;
BA_ "GenMsgCycleTime" BO_ 2364645886 20;
BA_ "GenMsgSendType" BO_ 2364645630 0;
BA_ "GenMsgCycleTime" BO_ 2364645630 20;
BA_ "GenMsgSendType" BO_ 2364645374 0;
BA_ "GenMsgCycleTime" BO_ 2364645374 100;
BA_ "GenMsgSendType" BO_ 2364645118 0;
BA_ "GenMsgCycleTime" BO_ 2364645118 100;
BA_ "GenMsgSendType" BO_ 2364644862 0;
BA_ "GenMsgCycleTime" BO_ 2364644862 100;
BA_ "FsJ1939UseCrcAndCounter" BO_ 2364644606 "Aa";
BA_ "GenMsgSendType" BO_ 2364644606 0;
BA_ "GenMsgCycleTime" BO_ 2364644606 100;
BA_ "GenMsgSendType" BO_ 2364644350 0;
BA_ "GenMsgCycleTime" BO_ 2364644350 100;
BA_ "GenMsgSendType" BO_ 2364644094 0;
BA_ "GenMsgCycleTime" BO_ 2364644094 100;
BA_ "GenMsgSendType" BO_ 2364643838 0;
BA_ "GenMsgCycleTime" BO_ 2364643838 100;
BA_ "GenMsgSendType" BO_ 2364643582 0;
BA_ "GenMsgCycleTime" BO_ 2364643582 100;
BA_ "SigType" SG_ 2364653310 Cur 1;
BA_ "SPN" SG_ 2364653310 Cur 11401;
BA_ "SigType" SG_ 2364653310 Lvl 1;
BA_ "SPN" SG_ 2364653310 Lvl 11400;
BA_ "SigType" SG_ 2364653310 AvailableChargePwr 1;
BA_ "SPN" SG_ 2364653310 AvailableChargePwr 11399;
BA_ "SigType" SG_ 2364653310 AvailableDisPwr 1;
BA_ "SPN" SG_ 2364653310 AvailableDisPwr 11398;
BA_ "SigType" SG_ 2364653054 ChargePLDueToAnUndefinedCause 4;
BA_ "SPN" SG_ 2364653054 ChargePLDueToAnUndefinedCause 11397;
BA_ "SigType" SG_ 2364653054 ChargePLDueToBatCur 4;
BA_ "SPN" SG_ 2364653054 ChargePLDueToBatCur 11396;
BA_ "SigType" SG_ 2364653054 ChargePLDueToBatOrCellV 4;
BA_ "SPN" SG_ 2364653054 ChargePLDueToBatOrCellV 11395;
BA_ "SigType" SG_ 2364653054 ChargePLDueToBatDiagCondition 4;
BA_ "SPN" SG_ 2364653054 ChargePLDueToBatDiagCondition 11394;
BA_ "SigType" SG_ 2364653054 ChargePLDueToBatTemp 4;
BA_ "SPN" SG_ 2364653054 ChargePLDueToBatTemp 11393;
BA_ "SigType" SG_ 2364653054 ChargePLDueToStOfCharge 4;
BA_ "SPN" SG_ 2364653054 ChargePLDueToStOfCharge 11392;
BA_ "SigType" SG_ 2364653054 DisPLDueToAnUndefinedCause 4;
BA_ "SPN" SG_ 2364653054 DisPLDueToAnUndefinedCause 11391;
BA_ "SigType" SG_ 2364653054 DisPLDueToBatCur 4;
BA_ "SPN" SG_ 2364653054 DisPLDueToBatCur 11390;
BA_ "SigType" SG_ 2364653054 DisPLDueToBatOrCellV 4;
BA_ "SPN" SG_ 2364653054 DisPLDueToBatOrCellV 11389;
BA_ "SigType" SG_ 2364653054 DisPLDueToBatDiagCondition 4;
BA_ "SPN" SG_ 2364653054 DisPLDueToBatDiagCondition 11388;
BA_ "SigType" SG_ 2364653054 DisPLDueToBatTemp 4;
BA_ "SPN" SG_ 2364653054 DisPLDueToBatTemp 11387;
BA_ "SigType" SG_ 2364653054 DisPLDueToStOfCharge 4;
BA_ "SPN" SG_ 2364653054 DisPLDueToStOfCharge 11386;
BA_ "SigType" SG_ 2364652798 ActualChargeRate 1;
BA_ "SPN" SG_ 2364652798 ActualChargeRate 13067;
BA_ "SigType" SG_ 2364652798 LvlNegToChassisGroundV 1;
BA_ "SPN" SG_ 2364652798 LvlNegToChassisGroundV 11363;
BA_ "SigType" SG_ 2364652798 BusVNegToChassisGroundV 1;
BA_ "SPN" SG_ 2364652798 BusVNegToChassisGroundV 11362;
BA_ "SigType" SG_ 2364652542 HVBusPassiveIsolTestResults 1;
BA_ "SPN" SG_ 2364652542 HVBusPassiveIsolTestResults 11361;
BA_ "SigType" SG_ 2364652542 HVBusActiveIsolTestResults 1;
BA_ "SPN" SG_ 2364652542 HVBusActiveIsolTestResults 11360;
BA_ "SigType" SG_ 2364652542 LowestCellStOfChargeCellNum 1;
BA_ "SPN" SG_ 2364652542 LowestCellStOfChargeCellNum 11359;
BA_ "SigType" SG_ 2364652542 LowestCellStOfChargeModuleNum 1;
BA_ "SPN" SG_ 2364652542 LowestCellStOfChargeModuleNum 11358;
BA_ "SigType" SG_ 2364652542 HighestCellStOfChargeCellNum 1;
BA_ "SPN" SG_ 2364652542 HighestCellStOfChargeCellNum 11357;
BA_ "SigType" SG_ 2364652542 HighestCellStOfChargeModuleNum 1;
BA_ "SPN" SG_ 2364652542 HighestCellStOfChargeModuleNum 11356;
BA_ "SigType" SG_ 2364652286 Data9CRC 12;
BA_ "SPN" SG_ 2364652286 Data9CRC 22982;
BA_ "SigType" SG_ 2364652286 Data9Counter 11;
BA_ "SPN" SG_ 2364652286 Data9Counter 22981;
BA_ "SigType" SG_ 2364652286 Data9EmbeddedIntegritySupport 5;
BA_ "SPN" SG_ 2364652286 Data9EmbeddedIntegritySupport 22980;
BA_ "SigType" SG_ 2364652286 HVESS3ThermalEventDetected 4;
BA_ "SPN" SG_ 2364652286 HVESS3ThermalEventDetected 21290;
BA_ "SigType" SG_ 2364652286 LowestCellTempCellNum 1;
BA_ "SPN" SG_ 2364652286 LowestCellTempCellNum 11355;
BA_ "SigType" SG_ 2364652286 LowestCellTempModuleNum 1;
BA_ "SPN" SG_ 2364652286 LowestCellTempModuleNum 11354;
BA_ "SigType" SG_ 2364652286 HighestCellTempCellNum 1;
BA_ "SPN" SG_ 2364652286 HighestCellTempCellNum 11353;
BA_ "SigType" SG_ 2364652286 HighestCellTempModuleNum 1;
BA_ "SPN" SG_ 2364652286 HighestCellTempModuleNum 11352;
BA_ "SigType" SG_ 2364652030 AvgCellV 1;
BA_ "SPN" SG_ 2364652030 AvgCellV 11351;
BA_ "SigType" SG_ 2364652030 LowestCellVCellNum 1;
BA_ "SPN" SG_ 2364652030 LowestCellVCellNum 11350;
BA_ "SigType" SG_ 2364652030 LowestCellVModuleNum 1;
BA_ "SPN" SG_ 2364652030 LowestCellVModuleNum 11349;
BA_ "SigType" SG_ 2364652030 HighestCellVCellNum 1;
BA_ "SPN" SG_ 2364652030 HighestCellVCellNum 11348;
BA_ "SigType" SG_ 2364652030 HighestCellVModuleNum 1;
BA_ "SPN" SG_ 2364652030 HighestCellVModuleNum 11347;
BA_ "SigType" SG_ 2364651774 TMSCoolantLvl 4;
BA_ "SPN" SG_ 2364651774 TMSCoolantLvl 12900;
BA_ "SPN" SG_ 2364651774 TMSMode 11346;
BA_ "SigType" SG_ 2364651774 TMSHVILStatus 4;
BA_ "SPN" SG_ 2364651774 TMSHVILStatus 12817;
BA_ "SigType" SG_ 2364651774 TMSHtrStatus 5;
BA_ "SPN" SG_ 2364651774 TMSHtrStatus 11345;
BA_ "SigType" SG_ 2364651774 TMSRelHumidty 1;
BA_ "SPN" SG_ 2364651774 TMSRelHumidty 11344;
BA_ "SigType" SG_ 2364651774 TMSCompressorSpd 1;
BA_ "SPN" SG_ 2364651774 TMSCompressorSpd 11343;
BA_ "SigType" SG_ 2364651774 TMSHVInputPwr 1;
BA_ "SPN" SG_ 2364651774 TMSHVInputPwr 11342;
BA_ "SigType" SG_ 2364651774 TMSSLIInputPwr 1;
BA_ "SPN" SG_ 2364651774 TMSSLIInputPwr 11341;
BA_ "SigType" SG_ 2364651518 Module32OperationalStatus 5;
BA_ "SPN" SG_ 2364651518 Module32OperationalStatus 14672;
BA_ "SigType" SG_ 2364651518 Module31OperationalStatus 5;
BA_ "SPN" SG_ 2364651518 Module31OperationalStatus 14671;
BA_ "SigType" SG_ 2364651518 Module30OperationalStatus 5;
BA_ "SPN" SG_ 2364651518 Module30OperationalStatus 14670;
BA_ "SigType" SG_ 2364651518 Module29OperationalStatus 5;
BA_ "SPN" SG_ 2364651518 Module29OperationalStatus 14669;
BA_ "SigType" SG_ 2364651518 Module28OperationalStatus 5;
BA_ "SPN" SG_ 2364651518 Module28OperationalStatus 14668;
BA_ "SigType" SG_ 2364651518 Module27OperationalStatus 5;
BA_ "SPN" SG_ 2364651518 Module27OperationalStatus 14667;
BA_ "SigType" SG_ 2364651518 Module26OperationalStatus 5;
BA_ "SPN" SG_ 2364651518 Module26OperationalStatus 14666;
BA_ "SigType" SG_ 2364651518 Module25OperationalStatus 5;
BA_ "SPN" SG_ 2364651518 Module25OperationalStatus 14665;
BA_ "SigType" SG_ 2364651518 Module24OperationalStatus 5;
BA_ "SPN" SG_ 2364651518 Module24OperationalStatus 14664;
BA_ "SigType" SG_ 2364651518 Module23OperationalStatus 5;
BA_ "SPN" SG_ 2364651518 Module23OperationalStatus 14663;
BA_ "SigType" SG_ 2364651518 Module22OperationalStatus 5;
BA_ "SPN" SG_ 2364651518 Module22OperationalStatus 14662;
BA_ "SigType" SG_ 2364651518 Module21OperationalStatus 5;
BA_ "SPN" SG_ 2364651518 Module21OperationalStatus 14661;
BA_ "SigType" SG_ 2364651518 Module20OperationalStatus 5;
BA_ "SPN" SG_ 2364651518 Module20OperationalStatus 14660;
BA_ "SigType" SG_ 2364651518 Module19OperationalStatus 5;
BA_ "SPN" SG_ 2364651518 Module19OperationalStatus 14659;
BA_ "SigType" SG_ 2364651518 Module18OperationalStatus 5;
BA_ "SPN" SG_ 2364651518 Module18OperationalStatus 14658;
BA_ "SigType" SG_ 2364651518 Module17OperationalStatus 5;
BA_ "SPN" SG_ 2364651518 Module17OperationalStatus 14657;
BA_ "SigType" SG_ 2364651518 Module16OperationalStatus 5;
BA_ "SPN" SG_ 2364651518 Module16OperationalStatus 11340;
BA_ "SigType" SG_ 2364651518 Module15OperationalStatus 5;
BA_ "SPN" SG_ 2364651518 Module15OperationalStatus 11339;
BA_ "SigType" SG_ 2364651518 Module14OperationalStatus 5;
BA_ "SPN" SG_ 2364651518 Module14OperationalStatus 11338;
BA_ "SigType" SG_ 2364651518 Module13OperationalStatus 5;
BA_ "SPN" SG_ 2364651518 Module13OperationalStatus 11337;
BA_ "SigType" SG_ 2364651518 Module12OperationalStatus 5;
BA_ "SPN" SG_ 2364651518 Module12OperationalStatus 11336;
BA_ "SigType" SG_ 2364651518 Module11OperationalStatus 5;
BA_ "SPN" SG_ 2364651518 Module11OperationalStatus 11335;
BA_ "SigType" SG_ 2364651518 Module10OperationalStatus 5;
BA_ "SPN" SG_ 2364651518 Module10OperationalStatus 11334;
BA_ "SigType" SG_ 2364651518 Module9OperationalStatus 5;
BA_ "SPN" SG_ 2364651518 Module9OperationalStatus 11333;
BA_ "SigType" SG_ 2364651518 Module8OperationalStatus 5;
BA_ "SPN" SG_ 2364651518 Module8OperationalStatus 11332;
BA_ "SigType" SG_ 2364651518 Module7OperationalStatus 5;
BA_ "SPN" SG_ 2364651518 Module7OperationalStatus 11331;
BA_ "SigType" SG_ 2364651518 Module6OperationalStatus 5;
BA_ "SPN" SG_ 2364651518 Module6OperationalStatus 11330;
BA_ "SigType" SG_ 2364651518 Module5OperationalStatus 5;
BA_ "SPN" SG_ 2364651518 Module5OperationalStatus 11329;
BA_ "SigType" SG_ 2364651518 Module4OperationalStatus 5;
BA_ "SPN" SG_ 2364651518 Module4OperationalStatus 11328;
BA_ "SigType" SG_ 2364651518 Module3OperationalStatus 5;
BA_ "SPN" SG_ 2364651518 Module3OperationalStatus 11327;
BA_ "SigType" SG_ 2364651518 Module2OperationalStatus 5;
BA_ "SPN" SG_ 2364651518 Module2OperationalStatus 11326;
BA_ "SigType" SG_ 2364651518 Module1OperationalStatus 5;
BA_ "SPN" SG_ 2364651518 Module1OperationalStatus 11325;
BA_ "SigType" SG_ 2364651262 MaxChargeVLmt 1;
BA_ "SPN" SG_ 2364651262 MaxChargeVLmt 11324;
BA_ "SPN" SG_ 2364651262 ChargeEnergyCapacity 11323;
BA_ "SPN" SG_ 2364651262 DisEnergyCapacity 11322;
BA_ "SigType" SG_ 2364651006 Status1CRC 12;
BA_ "SPN" SG_ 2364651006 Status1CRC 13020;
BA_ "SigType" SG_ 2364651006 Status1Counter 11;
BA_ "SPN" SG_ 2364651006 Status1Counter 13019;
BA_ "SPN" SG_ 2364651006 OperationalStatus 11321;
BA_ "SPN" SG_ 2364651006 HVBusConnectionStatus 11320;
BA_ "SigType" SG_ 2364651006 InternalChargerStatus 5;
BA_ "SPN" SG_ 2364651006 InternalChargerStatus 11319;
BA_ "SigType" SG_ 2364651006 CellBalancingActive 4;
BA_ "SPN" SG_ 2364651006 CellBalancingActive 11318;
BA_ "SigType" SG_ 2364651006 CellBalanceStatus 4;
BA_ "SPN" SG_ 2364651006 CellBalanceStatus 11317;
BA_ "SPN" SG_ 2364651006 StOfChargeStatus 11316;
BA_ "SigType" SG_ 2364651006 InertiaSwStatus 4;
BA_ "SPN" SG_ 2364651006 InertiaSwStatus 11315;
BA_ "SigType" SG_ 2364651006 HVILStatus 4;
BA_ "SPN" SG_ 2364651006 HVILStatus 11314;
BA_ "SPN" SG_ 2364651006 HVBusPassiveIsolTestStatus 11313;
BA_ "SPN" SG_ 2364651006 HVBusActiveIsolTestStatus 11312;
BA_ "SigType" SG_ 2364651006 CenterOfPackContactorSt 4;
BA_ "SPN" SG_ 2364651006 CenterOfPackContactorSt 11311;
BA_ "SigType" SG_ 2364651006 HVBusPreChargeRelaySt 4;
BA_ "SPN" SG_ 2364651006 HVBusPreChargeRelaySt 11310;
BA_ "SPN" SG_ 2364651006 HVBusDisconnectForewarning 11309;
BA_ "SigType" SG_ 2364651006 HVBusContactorSt11308 4;
BA_ "SPN" SG_ 2364651006 HVBusContactorSt11308 11308;
BA_ "SigType" SG_ 2364651006 HVBusContactorSt 4;
BA_ "SPN" SG_ 2364651006 HVBusContactorSt 11307;
BA_ "SigType" SG_ 2364650750 Temp 1;
BA_ "SPN" SG_ 2364650750 Temp 11306;
BA_ "SigType" SG_ 2364650750 ETemp 1;
BA_ "SPN" SG_ 2364650750 ETemp 11305;
BA_ "SigType" SG_ 2364650750 OutCoolantTemp 1;
BA_ "SPN" SG_ 2364650750 OutCoolantTemp 11304;
BA_ "SigType" SG_ 2364650750 InCoolantTemp 1;
BA_ "SPN" SG_ 2364650750 InCoolantTemp 11303;
BA_ "SigType" SG_ 2364650750 IgntV 1;
BA_ "SPN" SG_ 2364650750 IgntV 11302;
BA_ "SigType" SG_ 2364650750 BusV 1;
BA_ "SPN" SG_ 2364650750 BusV 11301;
BA_ "SigType" SG_ 2364650494 HighestCellStOfCharge 1;
BA_ "SPN" SG_ 2364650494 HighestCellStOfCharge 11300;
BA_ "SigType" SG_ 2364650494 LowestCellStOfCharge 1;
BA_ "SPN" SG_ 2364650494 LowestCellStOfCharge 11299;
BA_ "SigType" SG_ 2364650494 ChargeCurLmt 1;
BA_ "GenSigStartValue" SG_ 2364650494 ChargeCurLmt 32000;
BA_ "SPN" SG_ 2364650494 ChargeCurLmt 11298;
BA_ "SigType" SG_ 2364650494 DisCurLmt 1;
BA_ "SPN" SG_ 2364650494 DisCurLmt 11297;
BA_ "SigType" SG_ 2364650238 CellBalancingCount 1;
BA_ "SPN" SG_ 2364650238 CellBalancingCount 11296;
BA_ "SigType" SG_ 2364650238 ChargeCapacity 1;
BA_ "SPN" SG_ 2364650238 ChargeCapacity 11295;
BA_ "SigType" SG_ 2364650238 DisCapacity 1;
BA_ "SPN" SG_ 2364650238 DisCapacity 11294;
BA_ "SigType" SG_ 2364649982 CellTempDiffStatus 4;
BA_ "SPN" SG_ 2364649982 CellTempDiffStatus 11293;
BA_ "SigType" SG_ 2364649982 AvgCellTemp 1;
BA_ "SPN" SG_ 2364649982 AvgCellTemp 11292;
BA_ "SigType" SG_ 2364649982 LowestCellTemp 1;
BA_ "SPN" SG_ 2364649982 LowestCellTemp 11291;
BA_ "SigType" SG_ 2364649982 HighestCellTemp 1;
BA_ "SPN" SG_ 2364649982 HighestCellTemp 11290;
BA_ "SPN" SG_ 2364649726 CellVDiffStatus 11289;
BA_ "SigType" SG_ 2364649726 LowestCellV 1;
BA_ "SPN" SG_ 2364649726 LowestCellV 11288;
BA_ "SigType" SG_ 2364649726 HighestCellV 1;
BA_ "SPN" SG_ 2364649726 HighestCellV 11287;
BA_ "SigType" SG_ 2364649726 FastUpdateStOfCharge 1;
BA_ "SPN" SG_ 2364649726 FastUpdateStOfCharge 11286;
BA_ "SigType" SG_ 2364649470 Cur 1;
BA_ "SPN" SG_ 2364649470 Cur 11285;
BA_ "SigType" SG_ 2364649470 Lvl 1;
BA_ "SPN" SG_ 2364649470 Lvl 11284;
BA_ "SigType" SG_ 2364649470 AvailableChargePwr 1;
BA_ "SPN" SG_ 2364649470 AvailableChargePwr 11283;
BA_ "SigType" SG_ 2364649470 AvailableDisPwr 1;
BA_ "SPN" SG_ 2364649470 AvailableDisPwr 11282;
BA_ "SigType" SG_ 2364649214 ChargePLDueToAnUndefinedCause 4;
BA_ "SPN" SG_ 2364649214 ChargePLDueToAnUndefinedCause 11281;
BA_ "SigType" SG_ 2364649214 ChargePLDueToBatCur 4;
BA_ "SPN" SG_ 2364649214 ChargePLDueToBatCur 11280;
BA_ "SigType" SG_ 2364649214 ChargePLDueToBatOrCellV 4;
BA_ "SPN" SG_ 2364649214 ChargePLDueToBatOrCellV 11279;
BA_ "SigType" SG_ 2364649214 ChargePLDueToBatDiagCondition 4;
BA_ "SPN" SG_ 2364649214 ChargePLDueToBatDiagCondition 11278;
BA_ "SigType" SG_ 2364649214 ChargePLDueToBatTemp 4;
BA_ "SPN" SG_ 2364649214 ChargePLDueToBatTemp 11277;
BA_ "SigType" SG_ 2364649214 ChargePLDueToStOfCharge 4;
BA_ "SPN" SG_ 2364649214 ChargePLDueToStOfCharge 11276;
BA_ "SigType" SG_ 2364649214 DisPLDueToAnUndefinedCause 4;
BA_ "SPN" SG_ 2364649214 DisPLDueToAnUndefinedCause 11275;
BA_ "SigType" SG_ 2364649214 DisPLDueToBatCur 4;
BA_ "SPN" SG_ 2364649214 DisPLDueToBatCur 11274;
BA_ "SigType" SG_ 2364649214 DisPLDueToBatOrCellV 4;
BA_ "SPN" SG_ 2364649214 DisPLDueToBatOrCellV 11273;
BA_ "SigType" SG_ 2364649214 DisPLDueToBatDiagCondition 4;
BA_ "SPN" SG_ 2364649214 DisPLDueToBatDiagCondition 11272;
BA_ "SigType" SG_ 2364649214 DisPLDueToBatTemp 4;
BA_ "SPN" SG_ 2364649214 DisPLDueToBatTemp 11271;
BA_ "SigType" SG_ 2364649214 DisPLDueToStOfCharge 4;
BA_ "SPN" SG_ 2364649214 DisPLDueToStOfCharge 11270;
BA_ "SigType" SG_ 2364648958 ActualChargeRate 1;
BA_ "SPN" SG_ 2364648958 ActualChargeRate 13066;
BA_ "SigType" SG_ 2364648958 LvlNegToChassisGroundV 1;
BA_ "SPN" SG_ 2364648958 LvlNegToChassisGroundV 11247;
BA_ "SigType" SG_ 2364648958 BusVNegToChassisGroundV 1;
BA_ "SPN" SG_ 2364648958 BusVNegToChassisGroundV 11246;
BA_ "SigType" SG_ 2364648702 HVBusPassiveIsolTestResults 1;
BA_ "SPN" SG_ 2364648702 HVBusPassiveIsolTestResults 11245;
BA_ "SigType" SG_ 2364648702 HVBusActiveIsolTestResults 1;
BA_ "SPN" SG_ 2364648702 HVBusActiveIsolTestResults 11244;
BA_ "SigType" SG_ 2364648702 LowestCellStOfChargeCellNum 1;
BA_ "SPN" SG_ 2364648702 LowestCellStOfChargeCellNum 11243;
BA_ "SigType" SG_ 2364648702 LowestCellStOfChargeModuleNum 1;
BA_ "SPN" SG_ 2364648702 LowestCellStOfChargeModuleNum 11242;
BA_ "SigType" SG_ 2364648702 HighestCellStOfChargeCellNum 1;
BA_ "SPN" SG_ 2364648702 HighestCellStOfChargeCellNum 11241;
BA_ "SigType" SG_ 2364648702 HighestCellStOfChargeModuleNum 1;
BA_ "SPN" SG_ 2364648702 HighestCellStOfChargeModuleNum 11240;
BA_ "SigType" SG_ 2364648446 Data9CRC 12;
BA_ "SPN" SG_ 2364648446 Data9CRC 22979;
BA_ "SigType" SG_ 2364648446 Data9Counter 11;
BA_ "SPN" SG_ 2364648446 Data9Counter 22978;
BA_ "SigType" SG_ 2364648446 Data9EmbeddedIntegritySupport 5;
BA_ "SPN" SG_ 2364648446 Data9EmbeddedIntegritySupport 22977;
BA_ "SigType" SG_ 2364648446 HVESS2ThermalEventDetected 4;
BA_ "SPN" SG_ 2364648446 HVESS2ThermalEventDetected 21289;
BA_ "SigType" SG_ 2364648446 LowestCellTempCellNum 1;
BA_ "SPN" SG_ 2364648446 LowestCellTempCellNum 11239;
BA_ "SigType" SG_ 2364648446 LowestCellTempModuleNum 1;
BA_ "SPN" SG_ 2364648446 LowestCellTempModuleNum 11238;
BA_ "SigType" SG_ 2364648446 HighestCellTempCellNum 1;
BA_ "SPN" SG_ 2364648446 HighestCellTempCellNum 11237;
BA_ "SigType" SG_ 2364648446 HighestCellTempModuleNum 1;
BA_ "SPN" SG_ 2364648446 HighestCellTempModuleNum 11236;
BA_ "SigType" SG_ 2364648190 AvgCellV 1;
BA_ "SPN" SG_ 2364648190 AvgCellV 11235;
BA_ "SigType" SG_ 2364648190 LowestCellVCellNum 1;
BA_ "SPN" SG_ 2364648190 LowestCellVCellNum 11234;
BA_ "SigType" SG_ 2364648190 LowestCellVModuleNum 1;
BA_ "SPN" SG_ 2364648190 LowestCellVModuleNum 11233;
BA_ "SigType" SG_ 2364648190 HighestCellVCellNum 1;
BA_ "SPN" SG_ 2364648190 HighestCellVCellNum 11232;
BA_ "SigType" SG_ 2364648190 HighestCellVModuleNum 1;
BA_ "SPN" SG_ 2364648190 HighestCellVModuleNum 11231;
BA_ "SigType" SG_ 2364647934 TMSCoolantLvl 4;
BA_ "SPN" SG_ 2364647934 TMSCoolantLvl 12899;
BA_ "SPN" SG_ 2364647934 TMSMode 11230;
BA_ "SigType" SG_ 2364647934 TMSHVILStatus 4;
BA_ "SPN" SG_ 2364647934 TMSHVILStatus 12818;
BA_ "SigType" SG_ 2364647934 TMSHtrStatus 5;
BA_ "SPN" SG_ 2364647934 TMSHtrStatus 11229;
BA_ "SigType" SG_ 2364647934 TMSRelHumidty 1;
BA_ "SPN" SG_ 2364647934 TMSRelHumidty 11228;
BA_ "SigType" SG_ 2364647934 TMSCompressorSpd 1;
BA_ "SPN" SG_ 2364647934 TMSCompressorSpd 11227;
BA_ "SigType" SG_ 2364647934 TMSHVInputPwr 1;
BA_ "SPN" SG_ 2364647934 TMSHVInputPwr 11226;
BA_ "SigType" SG_ 2364647934 TMSSLIInputPwr 1;
BA_ "SPN" SG_ 2364647934 TMSSLIInputPwr 11225;
BA_ "SigType" SG_ 2364647678 Module32OperationalStatus 5;
BA_ "SPN" SG_ 2364647678 Module32OperationalStatus 14656;
BA_ "SigType" SG_ 2364647678 Module31OperationalStatus 5;
BA_ "SPN" SG_ 2364647678 Module31OperationalStatus 14655;
BA_ "SigType" SG_ 2364647678 Module30OperationalStatus 5;
BA_ "SPN" SG_ 2364647678 Module30OperationalStatus 14654;
BA_ "SigType" SG_ 2364647678 Module29OperationalStatus 5;
BA_ "SPN" SG_ 2364647678 Module29OperationalStatus 14653;
BA_ "SigType" SG_ 2364647678 Module28OperationalStatus 5;
BA_ "SPN" SG_ 2364647678 Module28OperationalStatus 14652;
BA_ "SigType" SG_ 2364647678 Module27OperationalStatus 5;
BA_ "SPN" SG_ 2364647678 Module27OperationalStatus 14651;
BA_ "SigType" SG_ 2364647678 Module26OperationalStatus 5;
BA_ "SPN" SG_ 2364647678 Module26OperationalStatus 14650;
BA_ "SigType" SG_ 2364647678 Module25OperationalStatus 5;
BA_ "SPN" SG_ 2364647678 Module25OperationalStatus 14649;
BA_ "SigType" SG_ 2364647678 Module24OperationalStatus 5;
BA_ "SPN" SG_ 2364647678 Module24OperationalStatus 14648;
BA_ "SigType" SG_ 2364647678 Module23OperationalStatus 5;
BA_ "SPN" SG_ 2364647678 Module23OperationalStatus 14647;
BA_ "SigType" SG_ 2364647678 Module22OperationalStatus 5;
BA_ "SPN" SG_ 2364647678 Module22OperationalStatus 14646;
BA_ "SigType" SG_ 2364647678 Module21OperationalStatus 5;
BA_ "SPN" SG_ 2364647678 Module21OperationalStatus 14645;
BA_ "SigType" SG_ 2364647678 Module20OperationalStatus 5;
BA_ "SPN" SG_ 2364647678 Module20OperationalStatus 14644;
BA_ "SigType" SG_ 2364647678 Module19OperationalStatus 5;
BA_ "SPN" SG_ 2364647678 Module19OperationalStatus 14643;
BA_ "SigType" SG_ 2364647678 Module18OperationalStatus 5;
BA_ "SPN" SG_ 2364647678 Module18OperationalStatus 14642;
BA_ "SigType" SG_ 2364647678 Module17OperationalStatus 5;
BA_ "SPN" SG_ 2364647678 Module17OperationalStatus 14641;
BA_ "SigType" SG_ 2364647678 Module16OperationalStatus 5;
BA_ "SPN" SG_ 2364647678 Module16OperationalStatus 11224;
BA_ "SigType" SG_ 2364647678 Module15OperationalStatus 5;
BA_ "SPN" SG_ 2364647678 Module15OperationalStatus 11223;
BA_ "SigType" SG_ 2364647678 Module14OperationalStatus 5;
BA_ "SPN" SG_ 2364647678 Module14OperationalStatus 11222;
BA_ "SigType" SG_ 2364647678 Module13OperationalStatus 5;
BA_ "SPN" SG_ 2364647678 Module13OperationalStatus 11221;
BA_ "SigType" SG_ 2364647678 Module12OperationalStatus 5;
BA_ "SPN" SG_ 2364647678 Module12OperationalStatus 11220;
BA_ "SigType" SG_ 2364647678 Module11OperationalStatus 5;
BA_ "SPN" SG_ 2364647678 Module11OperationalStatus 11219;
BA_ "SigType" SG_ 2364647678 Module10OperationalStatus 5;
BA_ "SPN" SG_ 2364647678 Module10OperationalStatus 11218;
BA_ "SigType" SG_ 2364647678 Module9OperationalStatus 5;
BA_ "SPN" SG_ 2364647678 Module9OperationalStatus 11217;
BA_ "SigType" SG_ 2364647678 Module8OperationalStatus 5;
BA_ "SPN" SG_ 2364647678 Module8OperationalStatus 11216;
BA_ "SigType" SG_ 2364647678 Module7OperationalStatus 5;
BA_ "SPN" SG_ 2364647678 Module7OperationalStatus 11215;
BA_ "SigType" SG_ 2364647678 Module6OperationalStatus 5;
BA_ "SPN" SG_ 2364647678 Module6OperationalStatus 11214;
BA_ "SigType" SG_ 2364647678 Module5OperationalStatus 5;
BA_ "SPN" SG_ 2364647678 Module5OperationalStatus 11213;
BA_ "SigType" SG_ 2364647678 Module4OperationalStatus 5;
BA_ "SPN" SG_ 2364647678 Module4OperationalStatus 11212;
BA_ "SigType" SG_ 2364647678 Module3OperationalStatus 5;
BA_ "SPN" SG_ 2364647678 Module3OperationalStatus 11211;
BA_ "SigType" SG_ 2364647678 Module2OperationalStatus 5;
BA_ "SPN" SG_ 2364647678 Module2OperationalStatus 11210;
BA_ "SigType" SG_ 2364647678 Module1OperationalStatus 5;
BA_ "SPN" SG_ 2364647678 Module1OperationalStatus 11209;
BA_ "SigType" SG_ 2364647422 MaxChargeVLmt 1;
BA_ "SPN" SG_ 2364647422 MaxChargeVLmt 11208;
BA_ "SPN" SG_ 2364647422 ChargeEnergyCapacity 11207;
BA_ "SPN" SG_ 2364647422 DisEnergyCapacity 11206;
BA_ "SigType" SG_ 2364647166 Status1CRC 12;
BA_ "SPN" SG_ 2364647166 Status1CRC 13018;
BA_ "SigType" SG_ 2364647166 Status1Counter 11;
BA_ "SPN" SG_ 2364647166 Status1Counter 13017;
BA_ "SPN" SG_ 2364647166 OperationalStatus 11205;
BA_ "SPN" SG_ 2364647166 HVBusConnectionStatus 11204;
BA_ "SigType" SG_ 2364647166 InternalChargerStatus 5;
BA_ "SPN" SG_ 2364647166 InternalChargerStatus 11203;
BA_ "SigType" SG_ 2364647166 CellBalancingActive 4;
BA_ "SPN" SG_ 2364647166 CellBalancingActive 11202;
BA_ "SigType" SG_ 2364647166 CellBalanceStatus 4;
BA_ "SPN" SG_ 2364647166 CellBalanceStatus 11201;
BA_ "SPN" SG_ 2364647166 StOfChargeStatus 11200;
BA_ "SigType" SG_ 2364647166 InertiaSwStatus 4;
BA_ "SPN" SG_ 2364647166 InertiaSwStatus 11199;
BA_ "SigType" SG_ 2364647166 HVILStatus 4;
BA_ "SPN" SG_ 2364647166 HVILStatus 11198;
BA_ "SPN" SG_ 2364647166 HVBusPassiveIsolTestStatus 11197;
BA_ "SPN" SG_ 2364647166 HVBusActiveIsolTestStatus 11196;
BA_ "SigType" SG_ 2364647166 CenterOfPackContactorSt 4;
BA_ "SPN" SG_ 2364647166 CenterOfPackContactorSt 11195;
BA_ "SigType" SG_ 2364647166 HVBusPreChargeRelaySt 4;
BA_ "SPN" SG_ 2364647166 HVBusPreChargeRelaySt 11194;
BA_ "SPN" SG_ 2364647166 HVBusDisconnectForewarning 11193;
BA_ "SigType" SG_ 2364647166 HVBusContactorSt11192 4;
BA_ "SPN" SG_ 2364647166 HVBusContactorSt11192 11192;
BA_ "SigType" SG_ 2364647166 HVBusContactorSt 4;
BA_ "SPN" SG_ 2364647166 HVBusContactorSt 11191;
BA_ "SigType" SG_ 2364646910 Temp 1;
BA_ "SPN" SG_ 2364646910 Temp 11190;
BA_ "SigType" SG_ 2364646910 ETemp 1;
BA_ "SPN" SG_ 2364646910 ETemp 11189;
BA_ "SigType" SG_ 2364646910 OutCoolantTemp 1;
BA_ "SPN" SG_ 2364646910 OutCoolantTemp 11188;
BA_ "SigType" SG_ 2364646910 InCoolantTemp 1;
BA_ "SPN" SG_ 2364646910 InCoolantTemp 11187;
BA_ "SigType" SG_ 2364646910 IgntV 1;
BA_ "SPN" SG_ 2364646910 IgntV 11186;
BA_ "SigType" SG_ 2364646910 BusV 1;
BA_ "SPN" SG_ 2364646910 BusV 11185;
BA_ "SigType" SG_ 2364646654 HighestCellStOfCharge 1;
BA_ "SPN" SG_ 2364646654 HighestCellStOfCharge 11184;
BA_ "SigType" SG_ 2364646654 LowestCellStOfCharge 1;
BA_ "SPN" SG_ 2364646654 LowestCellStOfCharge 11183;
BA_ "SigType" SG_ 2364646654 ChargeCurLmt 1;
BA_ "GenSigStartValue" SG_ 2364646654 ChargeCurLmt 32000;
BA_ "SPN" SG_ 2364646654 ChargeCurLmt 11182;
BA_ "SigType" SG_ 2364646654 DisCurLmt 1;
BA_ "SPN" SG_ 2364646654 DisCurLmt 11181;
BA_ "SigType" SG_ 2364646398 CellBalancingCount 1;
BA_ "SPN" SG_ 2364646398 CellBalancingCount 11180;
BA_ "SigType" SG_ 2364646398 ChargeCapacity 1;
BA_ "SPN" SG_ 2364646398 ChargeCapacity 11179;
BA_ "SigType" SG_ 2364646398 DisCapacity 1;
BA_ "SPN" SG_ 2364646398 DisCapacity 11178;
BA_ "SigType" SG_ 2364646142 CellTempDiffStatus 4;
BA_ "SPN" SG_ 2364646142 CellTempDiffStatus 11177;
BA_ "SigType" SG_ 2364646142 AvgCellTemp 1;
BA_ "SPN" SG_ 2364646142 AvgCellTemp 11176;
BA_ "SigType" SG_ 2364646142 LowestCellTemp 1;
BA_ "SPN" SG_ 2364646142 LowestCellTemp 11175;
BA_ "SigType" SG_ 2364646142 HighestCellTemp 1;
BA_ "SPN" SG_ 2364646142 HighestCellTemp 11174;
BA_ "SPN" SG_ 2364645886 CellVDiffStatus 11173;
BA_ "SigType" SG_ 2364645886 LowestCellV 1;
BA_ "SPN" SG_ 2364645886 LowestCellV 11172;
BA_ "SigType" SG_ 2364645886 HighestCellV 1;
BA_ "SPN" SG_ 2364645886 HighestCellV 11171;
BA_ "SigType" SG_ 2364645886 FastUpdateStOfCharge 1;
BA_ "SPN" SG_ 2364645886 FastUpdateStOfCharge 11170;
BA_ "SigType" SG_ 2364645630 Cur 1;
BA_ "SPN" SG_ 2364645630 Cur 11169;
BA_ "SigType" SG_ 2364645630 Lvl 1;
BA_ "SPN" SG_ 2364645630 Lvl 11168;
BA_ "SigType" SG_ 2364645630 AvailableChargePwr 1;
BA_ "SPN" SG_ 2364645630 AvailableChargePwr 11167;
BA_ "SigType" SG_ 2364645630 AvailableDisPwr 1;
BA_ "SPN" SG_ 2364645630 AvailableDisPwr 11166;
BA_ "SigType" SG_ 2364645374 ChargePLDueToAnUndefinedCause 4;
BA_ "SPN" SG_ 2364645374 ChargePLDueToAnUndefinedCause 11165;
BA_ "SigType" SG_ 2364645374 ChargePLDueToBatCur 4;
BA_ "SPN" SG_ 2364645374 ChargePLDueToBatCur 11164;
BA_ "SigType" SG_ 2364645374 ChargePLDueToBatOrCellV 4;
BA_ "SPN" SG_ 2364645374 ChargePLDueToBatOrCellV 11163;
BA_ "SigType" SG_ 2364645374 ChargePLDueToBatDiagCondition 4;
BA_ "SPN" SG_ 2364645374 ChargePLDueToBatDiagCondition 11162;
BA_ "SigType" SG_ 2364645374 ChargePLDueToBatTemp 4;
BA_ "SPN" SG_ 2364645374 ChargePLDueToBatTemp 11161;
BA_ "SigType" SG_ 2364645374 ChargePLDueToStOfCharge 4;
BA_ "SPN" SG_ 2364645374 ChargePLDueToStOfCharge 11160;
BA_ "SigType" SG_ 2364645374 DisPLDueToAnUndefinedCause 4;
BA_ "SPN" SG_ 2364645374 DisPLDueToAnUndefinedCause 11159;
BA_ "SigType" SG_ 2364645374 DisPLDueToBatCur 4;
BA_ "SPN" SG_ 2364645374 DisPLDueToBatCur 11158;
BA_ "SigType" SG_ 2364645374 DisPLDueToBatOrCellV 4;
BA_ "SPN" SG_ 2364645374 DisPLDueToBatOrCellV 11157;
BA_ "SigType" SG_ 2364645374 DisPLDueToBatDiagCondition 4;
BA_ "SPN" SG_ 2364645374 DisPLDueToBatDiagCondition 11156;
BA_ "SigType" SG_ 2364645374 DisPLDueToBatTemp 4;
BA_ "SPN" SG_ 2364645374 DisPLDueToBatTemp 11155;
BA_ "SigType" SG_ 2364645374 DisPLDueToStOfCharge 4;
BA_ "SPN" SG_ 2364645374 DisPLDueToStOfCharge 11154;
BA_ "SigType" SG_ 2364645118 ActualChargeRate 1;
BA_ "SPN" SG_ 2364645118 ActualChargeRate 13065;
BA_ "SigType" SG_ 2364645118 LvlNegToChassisGroundV 1;
BA_ "SPN" SG_ 2364645118 LvlNegToChassisGroundV 11131;
BA_ "SigType" SG_ 2364645118 BusVNegToChassisGroundV 1;
BA_ "SPN" SG_ 2364645118 BusVNegToChassisGroundV 11130;
BA_ "SigType" SG_ 2364644862 HVBusPassiveIsolTestResults 1;
BA_ "SPN" SG_ 2364644862 HVBusPassiveIsolTestResults 11129;
BA_ "SigType" SG_ 2364644862 HVBusActiveIsolTestResults 1;
BA_ "SPN" SG_ 2364644862 HVBusActiveIsolTestResults 11128;
BA_ "SigType" SG_ 2364644862 LowestCellStOfChargeCellNum 1;
BA_ "SPN" SG_ 2364644862 LowestCellStOfChargeCellNum 11127;
BA_ "SigType" SG_ 2364644862 LowestCellStOfChargeModuleNum 1;
BA_ "SPN" SG_ 2364644862 LowestCellStOfChargeModuleNum 11126;
BA_ "SigType" SG_ 2364644862 HighestCellStOfChargeCellNum 1;
BA_ "SPN" SG_ 2364644862 HighestCellStOfChargeCellNum 11125;
BA_ "SigType" SG_ 2364644862 HighestCellStOfChargeModuleNum 1;
BA_ "SPN" SG_ 2364644862 HighestCellStOfChargeModuleNum 11124;
BA_ "SigType" SG_ 2364644606 Data9CRC 12;
BA_ "SPN" SG_ 2364644606 Data9CRC 22976;
BA_ "SigType" SG_ 2364644606 Data9Counter 11;
BA_ "SPN" SG_ 2364644606 Data9Counter 22975;
BA_ "SigType" SG_ 2364644606 Data9EmbeddedIntegritySupport 5;
BA_ "SPN" SG_ 2364644606 Data9EmbeddedIntegritySupport 22974;
BA_ "SigType" SG_ 2364644606 HVESS1ThermalEventDetected 4;
BA_ "SPN" SG_ 2364644606 HVESS1ThermalEventDetected 21288;
BA_ "SigType" SG_ 2364644606 LowestCellTempCellNum 1;
BA_ "SPN" SG_ 2364644606 LowestCellTempCellNum 11123;
BA_ "SigType" SG_ 2364644606 LowestCellTempModuleNum 1;
BA_ "SPN" SG_ 2364644606 LowestCellTempModuleNum 11122;
BA_ "SigType" SG_ 2364644606 HighestCellTempCellNum 1;
BA_ "SPN" SG_ 2364644606 HighestCellTempCellNum 11121;
BA_ "SigType" SG_ 2364644606 HighestCellTempModuleNum 1;
BA_ "SPN" SG_ 2364644606 HighestCellTempModuleNum 11120;
BA_ "SigType" SG_ 2364644350 AvgCellV 1;
BA_ "SPN" SG_ 2364644350 AvgCellV 11119;
BA_ "SigType" SG_ 2364644350 LowestCellVCellNum 1;
BA_ "SPN" SG_ 2364644350 LowestCellVCellNum 11118;
BA_ "SigType" SG_ 2364644350 LowestCellVModuleNum 1;
BA_ "SPN" SG_ 2364644350 LowestCellVModuleNum 11117;
BA_ "SigType" SG_ 2364644350 HighestCellVCellNum 1;
BA_ "SPN" SG_ 2364644350 HighestCellVCellNum 11116;
BA_ "SigType" SG_ 2364644350 HighestCellVModuleNum 1;
BA_ "SPN" SG_ 2364644350 HighestCellVModuleNum 11115;
BA_ "SigType" SG_ 2364644094 TMSCoolantLvl 4;
BA_ "SPN" SG_ 2364644094 TMSCoolantLvl 12898;
BA_ "SPN" SG_ 2364644094 TMSMode 11114;
BA_ "SigType" SG_ 2364644094 TMSHVILStatus 4;
BA_ "SPN" SG_ 2364644094 TMSHVILStatus 12819;
BA_ "SigType" SG_ 2364644094 TMSHtrStatus 5;
BA_ "SPN" SG_ 2364644094 TMSHtrStatus 11113;
BA_ "SigType" SG_ 2364644094 TMSRelHumidty 1;
BA_ "SPN" SG_ 2364644094 TMSRelHumidty 11112;
BA_ "SigType" SG_ 2364644094 TMSCompressorSpd 1;
BA_ "SPN" SG_ 2364644094 TMSCompressorSpd 11111;
BA_ "SigType" SG_ 2364644094 TMSHVInputPwr 1;
BA_ "SPN" SG_ 2364644094 TMSHVInputPwr 11110;
BA_ "SigType" SG_ 2364644094 TMSSLIInputPwr 1;
BA_ "SPN" SG_ 2364644094 TMSSLIInputPwr 11109;
BA_ "SigType" SG_ 2364643838 Module32OperationalStatus 5;
BA_ "SPN" SG_ 2364643838 Module32OperationalStatus 14640;
BA_ "SigType" SG_ 2364643838 Module31OperationalStatus 5;
BA_ "SPN" SG_ 2364643838 Module31OperationalStatus 14639;
BA_ "SigType" SG_ 2364643838 Module30OperationalStatus 5;
BA_ "SPN" SG_ 2364643838 Module30OperationalStatus 14638;
BA_ "SigType" SG_ 2364643838 Module29OperationalStatus 5;
BA_ "SPN" SG_ 2364643838 Module29OperationalStatus 14637;
BA_ "SigType" SG_ 2364643838 Module28OperationalStatus 5;
BA_ "SPN" SG_ 2364643838 Module28OperationalStatus 14636;
BA_ "SigType" SG_ 2364643838 Module27OperationalStatus 5;
BA_ "SPN" SG_ 2364643838 Module27OperationalStatus 14635;
BA_ "SigType" SG_ 2364643838 Module26OperationalStatus 5;
BA_ "SPN" SG_ 2364643838 Module26OperationalStatus 14634;
BA_ "SigType" SG_ 2364643838 Module25OperationalStatus 5;
BA_ "SPN" SG_ 2364643838 Module25OperationalStatus 14633;
BA_ "SigType" SG_ 2364643838 Module24OperationalStatus 5;
BA_ "SPN" SG_ 2364643838 Module24OperationalStatus 14632;
BA_ "SigType" SG_ 2364643838 Module23OperationalStatus 5;
BA_ "SPN" SG_ 2364643838 Module23OperationalStatus 14631;
BA_ "SigType" SG_ 2364643838 Module22OperationalStatus 5;
BA_ "SPN" SG_ 2364643838 Module22OperationalStatus 14630;
BA_ "SigType" SG_ 2364643838 Module21OperationalStatus 5;
BA_ "SPN" SG_ 2364643838 Module21OperationalStatus 14629;
BA_ "SigType" SG_ 2364643838 Module20OperationalStatus 5;
BA_ "SPN" SG_ 2364643838 Module20OperationalStatus 14628;
BA_ "SigType" SG_ 2364643838 Module19OperationalStatus 5;
BA_ "SPN" SG_ 2364643838 Module19OperationalStatus 14627;
BA_ "SigType" SG_ 2364643838 Module18OperationalStatus 5;
BA_ "SPN" SG_ 2364643838 Module18OperationalStatus 14626;
BA_ "SigType" SG_ 2364643838 Module17OperationalStatus 5;
BA_ "SPN" SG_ 2364643838 Module17OperationalStatus 14625;
BA_ "SigType" SG_ 2364643838 Module16OperationalStatus 5;
BA_ "SPN" SG_ 2364643838 Module16OperationalStatus 11108;
BA_ "SigType" SG_ 2364643838 Module15OperationalStatus 5;
BA_ "SPN" SG_ 2364643838 Module15OperationalStatus 11107;
BA_ "SigType" SG_ 2364643838 Module14OperationalStatus 5;
BA_ "SPN" SG_ 2364643838 Module14OperationalStatus 11106;
BA_ "SigType" SG_ 2364643838 Module13OperationalStatus 5;
BA_ "SPN" SG_ 2364643838 Module13OperationalStatus 11105;
BA_ "SigType" SG_ 2364643838 Module12OperationalStatus 5;
BA_ "SPN" SG_ 2364643838 Module12OperationalStatus 11104;
BA_ "SigType" SG_ 2364643838 Module11OperationalStatus 5;
BA_ "SPN" SG_ 2364643838 Module11OperationalStatus 11103;
BA_ "SigType" SG_ 2364643838 Module10OperationalStatus 5;
BA_ "SPN" SG_ 2364643838 Module10OperationalStatus 11102;
BA_ "SigType" SG_ 2364643838 Module9OperationalStatus 5;
BA_ "SPN" SG_ 2364643838 Module9OperationalStatus 11101;
BA_ "SigType" SG_ 2364643838 Module8OperationalStatus 5;
BA_ "SPN" SG_ 2364643838 Module8OperationalStatus 11100;
BA_ "SigType" SG_ 2364643838 Module7OperationalStatus 5;
BA_ "SPN" SG_ 2364643838 Module7OperationalStatus 11099;
BA_ "SigType" SG_ 2364643838 Module6OperationalStatus 5;
BA_ "SPN" SG_ 2364643838 Module6OperationalStatus 11098;
BA_ "SigType" SG_ 2364643838 Module5OperationalStatus 5;
BA_ "SPN" SG_ 2364643838 Module5OperationalStatus 11097;
BA_ "SigType" SG_ 2364643838 Module4OperationalStatus 5;
BA_ "SPN" SG_ 2364643838 Module4OperationalStatus 11096;
BA_ "SigType" SG_ 2364643838 Module3OperationalStatus 5;
BA_ "SPN" SG_ 2364643838 Module3OperationalStatus 11095;
BA_ "SigType" SG_ 2364643838 Module2OperationalStatus 5;
BA_ "SPN" SG_ 2364643838 Module2OperationalStatus 11094;
BA_ "SigType" SG_ 2364643838 Module1OperationalStatus 5;
BA_ "SPN" SG_ 2364643838 Module1OperationalStatus 11093;
BA_ "SigType" SG_ 2364643582 MaxChargeVLmt 1;
BA_ "SPN" SG_ 2364643582 MaxChargeVLmt 11092;
BA_ "SPN" SG_ 2364643582 ChargeEnergyCapacity 11091;
BA_ "SPN" SG_ 2364643582 DisEnergyCapacity 11090;
VAL_ 2364653054 ChargePLDueToAnUndefinedCause 3 "Not Available" 2 "Error" 1 "Power limited for this reason" 0 "No power limit for this reason" ;
VAL_ 2364653054 ChargePLDueToBatCur 3 "Not Available" 2 "Error" 1 "Power limited for this reason" 0 "No power limit for this reason" ;
VAL_ 2364653054 ChargePLDueToBatOrCellV 3 "Not Available" 2 "Error" 1 "Power limited for this reason" 0 "No power limit for this reason" ;
VAL_ 2364653054 ChargePLDueToBatDiagCondition 3 "Not Available" 2 "Error" 1 "Power limited for this reason" 0 "No power limit for this reason" ;
VAL_ 2364653054 ChargePLDueToBatTemp 3 "Not Available" 2 "Error" 1 "Power limited for this reason" 0 "No power limit for this reason" ;
VAL_ 2364653054 ChargePLDueToStOfCharge 3 "Not Available" 2 "Error" 1 "Power limited for this reason" 0 "No power limit for this reason" ;
VAL_ 2364653054 DisPLDueToAnUndefinedCause 3 "Not Available" 2 "Error" 1 "Power limited for this reason" 0 "No power limit for this reason" ;
VAL_ 2364653054 DisPLDueToBatCur 3 "Not Available" 2 "Error" 1 "Power limited for this reason" 0 "No power limit for this reason" ;
VAL_ 2364653054 DisPLDueToBatOrCellV 3 "Not Available" 2 "Error" 1 "Power limited for this reason" 0 "No power limit for this reason" ;
VAL_ 2364653054 DisPLDueToBatDiagCondition 3 "Not Available" 2 "Error" 1 "Power limited for this reason" 0 "No power limit for this reason" ;
VAL_ 2364653054 DisPLDueToBatTemp 3 "Not Available" 2 "Error" 1 "Power limited for this reason" 0 "No power limit for this reason" ;
VAL_ 2364653054 DisPLDueToStOfCharge 3 "Not Available" 2 "Error" 1 "Power limited for this reason" 0 "No power limit for this reason" ;
VAL_ 2364652286 Data9EmbeddedIntegritySupport 3 "CRC and Counter are not supported by the sender" 2 "Reserved" 1 "Protection is supported using J1939-76 SHM" 0 "Embedded CRC and Counter are supported by the sender" ;
VAL_ 2364652286 HVESS3ThermalEventDetected 3 "Not available" 2 "Error" 1 "Thermal Event Detected" 0 "No Thermal Event Detected" ;
VAL_ 2364651774 TMSCoolantLvl 3 "Not Available" 2 "Error" 1 "Coolant Level is sufficient" 0 "Coolant Level is not sufficient" ;
VAL_ 2364651774 TMSMode 15 "Not Available" 14 "Faulted" 13 "Reserved" 12 "Reserved" 11 "Reserved" 10 "Reserved" 9 "Reserved" 8 "Reserved" 7 "Reserved" 6 "Reserved" 5 "Maintaining" 4 "Drying" 3 "Heating" 2 "Cooling" 1 "Circulating" 0 "Off" ;
VAL_ 2364651774 TMSHVILStatus 3 "Not Available" 2 "Error" 1 "HVIL Open" 0 "HVIL Closed" ;
VAL_ 2364651774 TMSHtrStatus 3 "Not Available" 2 "Error" 1 "Heater On" 0 "Heater Off" ;
VAL_ 2364651518 Module32OperationalStatus 3 "Not Available" 2 "Error" 1 "Operational" 0 "Not Operational" ;
VAL_ 2364651518 Module31OperationalStatus 3 "Not Available" 2 "Error" 1 "Operational" 0 "Not Operational" ;
VAL_ 2364651518 Module30OperationalStatus 3 "Not Available" 2 "Error" 1 "Operational" 0 "Not Operational" ;
VAL_ 2364651518 Module29OperationalStatus 3 "Not Available" 2 "Error" 1 "Operational" 0 "Not Operational" ;
VAL_ 2364651518 Module28OperationalStatus 3 "Not Available" 2 "Error" 1 "Operational" 0 "Not Operational" ;
VAL_ 2364651518 Module27OperationalStatus 3 "Not Available" 2 "Error" 1 "Operational" 0 "Not Operational" ;
VAL_ 2364651518 Module26OperationalStatus 3 "Not Available" 2 "Error" 1 "Operational" 0 "Not Operational" ;
VAL_ 2364651518 Module25OperationalStatus 3 "Not Available" 2 "Error" 1 "Operational" 0 "Not Operational" ;
VAL_ 2364651518 Module24OperationalStatus 3 "Not Available" 2 "Error" 1 "Operational" 0 "Not Operational" ;
VAL_ 2364651518 Module23OperationalStatus 3 "Not Available" 2 "Error" 1 "Operational" 0 "Not Operational" ;
VAL_ 2364651518 Module22OperationalStatus 3 "Not Available" 2 "Error" 1 "Operational" 0 "Not Operational" ;
VAL_ 2364651518 Module21OperationalStatus 3 "Not Available" 2 "Error" 1 "Operational" 0 "Not Operational" ;
VAL_ 2364651518 Module20OperationalStatus 3 "Not Available" 2 "Error" 1 "Operational" 0 "Not Operational" ;
VAL_ 2364651518 Module19OperationalStatus 3 "Not Available" 2 "Error" 1 "Operational" 0 "Not Operational" ;
VAL_ 2364651518 Module18OperationalStatus 3 "Not Available" 2 "Error" 1 "Operational" 0 "Not Operational" ;
VAL_ 2364651518 Module17OperationalStatus 3 "Not Available" 2 "Error" 1 "Operational" 0 "Not Operational" ;
VAL_ 2364651518 Module16OperationalStatus 3 "Not Available" 2 "Error" 1 "Operational" 0 "Not Operational" ;
VAL_ 2364651518 Module15OperationalStatus 3 "Not Available" 2 "Error" 1 "Operational" 0 "Not Operational" ;
VAL_ 2364651518 Module14OperationalStatus 3 "Not Available" 2 "Error" 1 "Operational" 0 "Not Operational" ;
VAL_ 2364651518 Module13OperationalStatus 3 "Not Available" 2 "Error" 1 "Operational" 0 "Not Operational" ;
VAL_ 2364651518 Module12OperationalStatus 3 "Not Available" 2 "Error" 1 "Operational" 0 "Not Operational" ;
VAL_ 2364651518 Module11OperationalStatus 3 "Not Available" 2 "Error" 1 "Operational" 0 "Not Operational" ;
VAL_ 2364651518 Module10OperationalStatus 3 "Not Available" 2 "Error" 1 "Operational" 0 "Not Operational" ;
VAL_ 2364651518 Module9OperationalStatus 3 "Not Available" 2 "Error" 1 "Operational" 0 "Not Operational" ;
VAL_ 2364651518 Module8OperationalStatus 3 "Not Available" 2 "Error" 1 "Operational" 0 "Not Operational" ;
VAL_ 2364651518 Module7OperationalStatus 3 "Not Available" 2 "Error" 1 "Operational" 0 "Not Operational" ;
VAL_ 2364651518 Module6OperationalStatus 3 "Not Available" 2 "Error" 1 "Operational" 0 "Not Operational" ;
VAL_ 2364651518 Module5OperationalStatus 3 "Not Available" 2 "Error" 1 "Operational" 0 "Not Operational" ;
VAL_ 2364651518 Module4OperationalStatus 3 "Not Available" 2 "Error" 1 "Operational" 0 "Not Operational" ;
VAL_ 2364651518 Module3OperationalStatus 3 "Not Available" 2 "Error" 1 "Operational" 0 "Not Operational" ;
VAL_ 2364651518 Module2OperationalStatus 3 "Not Available" 2 "Error" 1 "Operational" 0 "Not Operational" ;
VAL_ 2364651518 Module1OperationalStatus 3 "Not Available" 2 "Error" 1 "Operational" 0 "Not Operational" ;
VAL_ 2364651006 OperationalStatus 15 "Not Available" 14 "Error" 13 "Reserved" 12 "Reserved" 11 "Reserved" 10 "Reserved" 9 "Reserved" 8 "Reserved" 7 "Reserved" 6 "Disabled by internal decision of HVES controller" 5 "Disabled by external command" 4 "Emergency Power-Down In Process" 3 "Normal Power-Down in Process" 2 "Operational." 1 "Initialization Complete" 0 "Initialization in process" ;
VAL_ 2364651006 HVBusConnectionStatus 15 "Not Available" 14 "Error" 13 "Reserved" 12 "Reserved" 11 "Reserved" 10 "Reserved" 9 "Reserved" 8 "Reserved" 7 "Reserved" 6 "Reserved" 5 "Reserved" 4 "Disconnected,  Precharge Failed" 3 "Disconnection in Process" 2 "Connection in Process" 1 "Connected" 0 "Disconnected,  One or more contactors are open" ;
VAL_ 2364651006 InternalChargerStatus 3 "Not Available" 2 "Error" 1 "Charging on" 0 "Charging off" ;
VAL_ 2364651006 CellBalancingActive 3 "Not Available" 2 "Error" 1 "Cell balancing is active" 0 "Cell balancing is not active" ;
VAL_ 2364651006 CellBalanceStatus 3 "Not Available" 2 "Error" 1 "Cells are unbalanced" 0 "Cells are balanced" ;
VAL_ 2364651006 StOfChargeStatus 15 "Not  Available" 14 "Error" 13 "Reserved" 12 "Reserved" 11 "Reserved" 10 "Reserved" 9 "Reserved" 8 "Reserved" 7 "Reserved" 6 "SOC is above its recommended upper limit" 5 "SOC is at its recommended upper limit" 4 "SOC is approaching its recommended upper limit" 3 "SOC is below its recommended lower limit" 2 "SOC is at its recommended lower limit" 1 "SOC is approaching its recommended lower limit" 0 "SOC level is acceptable" ;
VAL_ 2364651006 InertiaSwStatus 3 "Not Available" 2 "Error" 1 "Impact sensed" 0 "No impact sensed" ;
VAL_ 2364651006 HVILStatus 3 "Not Available" 2 "Error" 1 "HVIL Open" 0 "HVIL Closed" ;
VAL_ 2364651006 HVBusPassiveIsolTestStatus 15 "Not available" 14 "Error" 13 "Reserved" 12 "Reserved" 11 "Reserved" 10 "Reserved" 9 "Reserved" 8 "Reserved" 7 "Reserved" 6 "Reserved" 5 "Test complete,  isolation fault" 4 "Test complete,  isolation marginal" 3 "Test complete,  isolation acceptable" 2 "Test in process" 1 "Test requested but not yet in process" 0 "No test requested / No test in process" ;
VAL_ 2364651006 HVBusActiveIsolTestStatus 15 "Not available" 14 "Error" 13 "Reserved" 12 "Reserved" 11 "Reserved" 10 "Reserved" 9 "Reserved" 8 "Reserved" 7 "Reserved" 6 "Reserved" 5 "Test complete,  isolation fault" 4 "Test complete,  isolation marginal" 3 "Test complete,  isolation acceptable" 2 "Test in process" 1 "Test requested but not yet in process" 0 "No test requested / No test in process" ;
VAL_ 2364651006 CenterOfPackContactorSt 3 "Not Available" 2 "Error" 1 "Contactor Closed" 0 "Contactor Open" ;
VAL_ 2364651006 HVBusPreChargeRelaySt 3 "Not Available" 2 "Error" 1 "Relay Closed" 0 "Relay Open" ;
VAL_ 2364651006 HVBusDisconnectForewarning 15 "Not Available" 14 "Error" 13 "Disconnect imminent" 12 "Reserved" 11 "Reserved" 10 "Reserved" 9 "Reserved" 8 "Reserved" 7 "Disconnect imminent due to battery pack current approaching maximum acceptable level" 6 "Disconnect imminent due to cell voltage approaching maximum acceptable level" 5 "Disconnect imminent due to cell voltage approaching minimum acceptable level" 4 "Disconnect imminent due to module voltage approaching maximum acceptable level" 3 "Disconnect imminent due to module voltage approaching minimum acceptable level" 2 "Disconnect imminent due to battery pack voltage approaching maximum acceptable level" 1 "Disconnect imminent due to battery pack voltage approaching minimum acceptable level" 0 "Disconnect not pending" ;
VAL_ 2364651006 HVBusContactorSt11308 3 "Not Available" 2 "Error" 1 "Contactor Closed" 0 "Contactor Open" ;
VAL_ 2364651006 HVBusContactorSt 3 "Not Available" 2 "Error" 1 "Contactor Closed" 0 "Contactor Open" ;
VAL_ 2364649982 CellTempDiffStatus 3 "Not Available" 2 "Error" 1 "Cell-to-cell temperature differential exceeds acceptable limits" 0 "Cell-to-cell temperature differential is within acceptable limits" ;
VAL_ 2364649726 CellVDiffStatus 15 "Not Available" 14 "Error" 13 "Reserved" 12 "Reserved" 11 "Reserved" 10 "Reserved" 9 "Reserved" 8 "Reserved" 7 "Reserved" 6 "Reserved" 5 "Reserved" 4 "Exceeds limits and it is not known whether balancing can restore performance" 3 "Exceeds limits and external maintenance balancing cannot restore performance" 2 "Exceeds limits and external maintenance balancing is required" 1 "Exceeds limits and can be corrected via auto-balancing" 0 "Is within acceptable limits" ;
VAL_ 2364649214 ChargePLDueToAnUndefinedCause 3 "Not Available" 2 "Error" 1 "Power limited for this reason" 0 "No power limit for this reason" ;
VAL_ 2364649214 ChargePLDueToBatCur 3 "Not Available" 2 "Error" 1 "Power limited for this reason" 0 "No power limit for this reason" ;
VAL_ 2364649214 ChargePLDueToBatOrCellV 3 "Not Available" 2 "Error" 1 "Power limited for this reason" 0 "No power limit for this reason" ;
VAL_ 2364649214 ChargePLDueToBatDiagCondition 3 "Not Available" 2 "Error" 1 "Power limited for this reason" 0 "No power limit for this reason" ;
VAL_ 2364649214 ChargePLDueToBatTemp 3 "Not Available" 2 "Error" 1 "Power limited for this reason" 0 "No power limit for this reason" ;
VAL_ 2364649214 ChargePLDueToStOfCharge 3 "Not Available" 2 "Error" 1 "Power limited for this reason" 0 "No power limit for this reason" ;
VAL_ 2364649214 DisPLDueToAnUndefinedCause 3 "Not Available" 2 "Error" 1 "Power limited for this reason" 0 "No power limit for this reason" ;
VAL_ 2364649214 DisPLDueToBatCur 3 "Not Available" 2 "Error" 1 "Power limited for this reason" 0 "No power limit for this reason" ;
VAL_ 2364649214 DisPLDueToBatOrCellV 3 "Not Available" 2 "Error" 1 "Power limited for this reason" 0 "No power limit for this reason" ;
VAL_ 2364649214 DisPLDueToBatDiagCondition 3 "Not Available" 2 "Error" 1 "Power limited for this reason" 0 "No power limit for this reason" ;
VAL_ 2364649214 DisPLDueToBatTemp 3 "Not Available" 2 "Error" 1 "Power limited for this reason" 0 "No power limit for this reason" ;
VAL_ 2364649214 DisPLDueToStOfCharge 3 "Not Available" 2 "Error" 1 "Power limited for this reason" 0 "No power limit for this reason" ;
VAL_ 2364648446 Data9EmbeddedIntegritySupport 3 "CRC and Counter are not supported by the sender" 2 "Reserved" 1 "Protection is supported using J1939-76 SHM" 0 "Embedded CRC and Counter are supported by the sender" ;
VAL_ 2364648446 HVESS2ThermalEventDetected 3 "Not available" 2 "Error" 1 "Thermal Event Detected" 0 "No Thermal Event Detected" ;
VAL_ 2364647934 TMSCoolantLvl 3 "Not Available" 2 "Error" 1 "Coolant Level is sufficient" 0 "Coolant Level is not sufficient" ;
VAL_ 2364647934 TMSMode 15 "Not Available" 14 "Faulted" 13 "Reserved" 12 "Reserved" 11 "Reserved" 10 "Reserved" 9 "Reserved" 8 "Reserved" 7 "Reserved" 6 "Reserved" 5 "Maintaining" 4 "Drying" 3 "Heating" 2 "Cooling" 1 "Circulating" 0 "Off" ;
VAL_ 2364647934 TMSHVILStatus 3 "Not Available" 2 "Error" 1 "HVIL Open" 0 "HVIL Closed" ;
VAL_ 2364647934 TMSHtrStatus 3 "Not Available" 2 "Error" 1 "Heater On" 0 "Heater Off" ;
VAL_ 2364647678 Module32OperationalStatus 3 "Not Available" 2 "Error" 1 "Operational" 0 "Not Operational" ;
VAL_ 2364647678 Module31OperationalStatus 3 "Not Available" 2 "Error" 1 "Operational" 0 "Not Operational" ;
VAL_ 2364647678 Module30OperationalStatus 3 "Not Available" 2 "Error" 1 "Operational" 0 "Not Operational" ;
VAL_ 2364647678 Module29OperationalStatus 3 "Not Available" 2 "Error" 1 "Operational" 0 "Not Operational" ;
VAL_ 2364647678 Module28OperationalStatus 3 "Not Available" 2 "Error" 1 "Operational" 0 "Not Operational" ;
VAL_ 2364647678 Module27OperationalStatus 3 "Not Available" 2 "Error" 1 "Operational" 0 "Not Operational" ;
VAL_ 2364647678 Module26OperationalStatus 3 "Not Available" 2 "Error" 1 "Operational" 0 "Not Operational" ;
VAL_ 2364647678 Module25OperationalStatus 3 "Not Available" 2 "Error" 1 "Operational" 0 "Not Operational" ;
VAL_ 2364647678 Module24OperationalStatus 3 "Not Available" 2 "Error" 1 "Operational" 0 "Not Operational" ;
VAL_ 2364647678 Module23OperationalStatus 3 "Not Available" 2 "Error" 1 "Operational" 0 "Not Operational" ;
VAL_ 2364647678 Module22OperationalStatus 3 "Not Available" 2 "Error" 1 "Operational" 0 "Not Operational" ;
VAL_ 2364647678 Module21OperationalStatus 3 "Not Available" 2 "Error" 1 "Operational" 0 "Not Operational" ;
VAL_ 2364647678 Module20OperationalStatus 3 "Not Available" 2 "Error" 1 "Operational" 0 "Not Operational" ;
VAL_ 2364647678 Module19OperationalStatus 3 "Not Available" 2 "Error" 1 "Operational" 0 "Not Operational" ;
VAL_ 2364647678 Module18OperationalStatus 3 "Not Available" 2 "Error" 1 "Operational" 0 "Not Operational" ;
VAL_ 2364647678 Module17OperationalStatus 3 "Not Available" 2 "Error" 1 "Operational" 0 "Not Operational" ;
VAL_ 2364647678 Module16OperationalStatus 3 "Not Available" 2 "Error" 1 "Operational" 0 "Not Operational" ;
VAL_ 2364647678 Module15OperationalStatus 3 "Not Available" 2 "Error" 1 "Operational" 0 "Not Operational" ;
VAL_ 2364647678 Module14OperationalStatus 3 "Not Available" 2 "Error" 1 "Operational" 0 "Not Operational" ;
VAL_ 2364647678 Module13OperationalStatus 3 "Not Available" 2 "Error" 1 "Operational" 0 "Not Operational" ;
VAL_ 2364647678 Module12OperationalStatus 3 "Not Available" 2 "Error" 1 "Operational" 0 "Not Operational" ;
VAL_ 2364647678 Module11OperationalStatus 3 "Not Available" 2 "Error" 1 "Operational" 0 "Not Operational" ;
VAL_ 2364647678 Module10OperationalStatus 3 "Not Available" 2 "Error" 1 "Operational" 0 "Not Operational" ;
VAL_ 2364647678 Module9OperationalStatus 3 "Not Available" 2 "Error" 1 "Operational" 0 "Not Operational" ;
VAL_ 2364647678 Module8OperationalStatus 3 "Not Available" 2 "Error" 1 "Operational" 0 "Not Operational" ;
VAL_ 2364647678 Module7OperationalStatus 3 "Not Available" 2 "Error" 1 "Operational" 0 "Not Operational" ;
VAL_ 2364647678 Module6OperationalStatus 3 "Not Available" 2 "Error" 1 "Operational" 0 "Not Operational" ;
VAL_ 2364647678 Module5OperationalStatus 3 "Not Available" 2 "Error" 1 "Operational" 0 "Not Operational" ;
VAL_ 2364647678 Module4OperationalStatus 3 "Not Available" 2 "Error" 1 "Operational" 0 "Not Operational" ;
VAL_ 2364647678 Module3OperationalStatus 3 "Not Available" 2 "Error" 1 "Operational" 0 "Not Operational" ;
VAL_ 2364647678 Module2OperationalStatus 3 "Not Available" 2 "Error" 1 "Operational" 0 "Not Operational" ;
VAL_ 2364647678 Module1OperationalStatus 3 "Not Available" 2 "Error" 1 "Operational" 0 "Not Operational" ;
VAL_ 2364647166 OperationalStatus 15 "Not Available" 14 "Error" 13 "Reserved" 12 "Reserved" 11 "Reserved" 10 "Reserved" 9 "Reserved" 8 "Reserved" 7 "Reserved" 6 "Disabled by internal decision of HVES controller" 5 "Disabled by external command" 4 "Emergency Power-Down In Process" 3 "Normal Power-Down in Process" 2 "Operational." 1 "Initialization Complete" 0 "Initialization in process" ;
VAL_ 2364647166 HVBusConnectionStatus 15 "Not Available" 14 "Error" 13 "Reserved" 12 "Reserved" 11 "Reserved" 10 "Reserved" 9 "Reserved" 8 "Reserved" 7 "Reserved" 6 "Reserved" 5 "Reserved" 4 "Disconnected,  Precharge Failed" 3 "Disconnection in Process" 2 "Connection in Process" 1 "Connected" 0 "Disconnected,  One or more contactors are open" ;
VAL_ 2364647166 InternalChargerStatus 3 "Not Available" 2 "Error" 1 "Charging on" 0 "Charging off" ;
VAL_ 2364647166 CellBalancingActive 3 "Not Available" 2 "Error" 1 "Cell balancing is active" 0 "Cell balancing is not active" ;
VAL_ 2364647166 CellBalanceStatus 3 "Not Available" 2 "Error" 1 "Cells are unbalanced" 0 "Cells are balanced" ;
VAL_ 2364647166 StOfChargeStatus 15 "Not  Available" 14 "Error" 13 "Reserved" 12 "Reserved" 11 "Reserved" 10 "Reserved" 9 "Reserved" 8 "Reserved" 7 "Reserved" 6 "SOC is above its recommended upper limit" 5 "SOC is at its recommended upper limit" 4 "SOC is approaching its recommended upper limit" 3 "SOC is below its recommended lower limit" 2 "SOC is at its recommended lower limit" 1 "SOC is approaching its recommended lower limit" 0 "SOC level is acceptable" ;
VAL_ 2364647166 InertiaSwStatus 3 "Not Available" 2 "Error" 1 "Impact sensed" 0 "No impact sensed" ;
VAL_ 2364647166 HVILStatus 3 "Not Available" 2 "Error" 1 "HVIL Open" 0 "HVIL Closed" ;
VAL_ 2364647166 HVBusPassiveIsolTestStatus 15 "Not available" 14 "Error" 13 "Reserved" 12 "Reserved" 11 "Reserved" 10 "Reserved" 9 "Reserved" 8 "Reserved" 7 "Reserved" 6 "Reserved" 5 "Test complete,  isolation fault" 4 "Test complete,  isolation marginal" 3 "Test complete,  isolation acceptable" 2 "Test in process" 1 "Test requested but not yet in process" 0 "No test requested / No test in process" ;
VAL_ 2364647166 HVBusActiveIsolTestStatus 15 "Not available" 14 "Error" 13 "Reserved" 12 "Reserved" 11 "Reserved" 10 "Reserved" 9 "Reserved" 8 "Reserved" 7 "Reserved" 6 "Reserved" 5 "Test complete,  isolation fault" 4 "Test complete,  isolation marginal" 3 "Test complete,  isolation acceptable" 2 "Test in process" 1 "Test requested but not yet in process" 0 "No test requested / No test in process" ;
VAL_ 2364647166 CenterOfPackContactorSt 3 "Not Available" 2 "Error" 1 "Contactor Closed" 0 "Contactor Open" ;
VAL_ 2364647166 HVBusPreChargeRelaySt 3 "Not Available" 2 "Error" 1 "Relay Closed" 0 "Relay Open" ;
VAL_ 2364647166 HVBusDisconnectForewarning 15 "Not Available" 14 "Error" 13 "Disconnect imminent" 12 "Reserved" 11 "Reserved" 10 "Reserved" 9 "Reserved" 8 "Reserved" 7 "Disconnect imminent due to battery pack current approaching maximum acceptable level" 6 "Disconnect imminent due to cell voltage approaching maximum acceptable level" 5 "Disconnect imminent due to cell voltage approaching minimum acceptable level" 4 "Disconnect imminent due to module voltage approaching maximum acceptable level" 3 "Disconnect imminent due to module voltage approaching minimum acceptable level" 2 "Disconnect imminent due to battery pack voltage approaching maximum acceptable level" 1 "Disconnect imminent due to battery pack voltage approaching minimum acceptable level" 0 "Disconnect not pending" ;
VAL_ 2364647166 HVBusContactorSt11192 3 "Not Available" 2 "Error" 1 "Contactor Closed" 0 "Contactor Open" ;
VAL_ 2364647166 HVBusContactorSt 3 "Not Available" 2 "Error" 1 "Contactor Closed" 0 "Contactor Open" ;
VAL_ 2364646142 CellTempDiffStatus 3 "Not Available" 2 "Error" 1 "Cell-to-cell temperature differential exceeds acceptable limits" 0 "Cell-to-cell temperature differential is within acceptable limits" ;
VAL_ 2364645886 CellVDiffStatus 15 "Not Available" 14 "Error" 13 "Reserved" 12 "Reserved" 11 "Reserved" 10 "Reserved" 9 "Reserved" 8 "Reserved" 7 "Reserved" 6 "Reserved" 5 "Reserved" 4 "Exceeds limits and it is not known whether balancing can restore performance" 3 "Exceeds limits and external maintenance balancing cannot restore performance" 2 "Exceeds limits and external maintenance balancing is required" 1 "Exceeds limits and can be corrected via auto-balancing" 0 "Is within acceptable limits" ;
VAL_ 2364645374 ChargePLDueToAnUndefinedCause 3 "Not Available" 2 "Error" 1 "Power limited for this reason" 0 "No power limit for this reason" ;
VAL_ 2364645374 ChargePLDueToBatCur 3 "Not Available" 2 "Error" 1 "Power limited for this reason" 0 "No power limit for this reason" ;
VAL_ 2364645374 ChargePLDueToBatOrCellV 3 "Not Available" 2 "Error" 1 "Power limited for this reason" 0 "No power limit for this reason" ;
VAL_ 2364645374 ChargePLDueToBatDiagCondition 3 "Not Available" 2 "Error" 1 "Power limited for this reason" 0 "No power limit for this reason" ;
VAL_ 2364645374 ChargePLDueToBatTemp 3 "Not Available" 2 "Error" 1 "Power limited for this reason" 0 "No power limit for this reason" ;
VAL_ 2364645374 ChargePLDueToStOfCharge 3 "Not Available" 2 "Error" 1 "Power limited for this reason" 0 "No power limit for this reason" ;
VAL_ 2364645374 DisPLDueToAnUndefinedCause 3 "Not Available" 2 "Error" 1 "Power limited for this reason" 0 "No power limit for this reason" ;
VAL_ 2364645374 DisPLDueToBatCur 3 "Not Available" 2 "Error" 1 "Power limited for this reason" 0 "No power limit for this reason" ;
VAL_ 2364645374 DisPLDueToBatOrCellV 3 "Not Available" 2 "Error" 1 "Power limited for this reason" 0 "No power limit for this reason" ;
VAL_ 2364645374 DisPLDueToBatDiagCondition 3 "Not Available" 2 "Error" 1 "Power limited for this reason" 0 "No power limit for this reason" ;
VAL_ 2364645374 DisPLDueToBatTemp 3 "Not Available" 2 "Error" 1 "Power limited for this reason" 0 "No power limit for this reason" ;
VAL_ 2364645374 DisPLDueToStOfCharge 3 "Not Available" 2 "Error" 1 "Power limited for this reason" 0 "No power limit for this reason" ;
VAL_ 2364644606 Data9EmbeddedIntegritySupport 3 "CRC and Counter are not supported by the sender" 2 "Reserved" 1 "Protection is supported using J1939-76 SHM" 0 "Embedded CRC and Counter are supported by the sender" ;
VAL_ 2364644606 HVESS1ThermalEventDetected 3 "Not available" 2 "Error" 1 "Thermal Event Detected" 0 "No Thermal Event Detected" ;
VAL_ 2364644094 TMSCoolantLvl 3 "Not Available" 2 "Error" 1 "Coolant Level is sufficient" 0 "Coolant Level is not sufficient" ;
VAL_ 2364644094 TMSMode 15 "Not Available" 14 "Faulted" 13 "Reserved" 12 "Reserved" 11 "Reserved" 10 "Reserved" 9 "Reserved" 8 "Reserved" 7 "Reserved" 6 "Reserved" 5 "Maintaining" 4 "Drying" 3 "Heating" 2 "Cooling" 1 "Circulating" 0 "Off" ;
VAL_ 2364644094 TMSHVILStatus 3 "Not Available" 2 "Error" 1 "HVIL Open" 0 "HVIL Closed" ;
VAL_ 2364644094 TMSHtrStatus 3 "Not Available" 2 "Error" 1 "Heater On" 0 "Heater Off" ;
VAL_ 2364643838 Module32OperationalStatus 3 "Not Available" 2 "Error" 1 "Operational" 0 "Not Operational" ;
VAL_ 2364643838 Module31OperationalStatus 3 "Not Available" 2 "Error" 1 "Operational" 0 "Not Operational" ;
VAL_ 2364643838 Module30OperationalStatus 3 "Not Available" 2 "Error" 1 "Operational" 0 "Not Operational" ;
VAL_ 2364643838 Module29OperationalStatus 3 "Not Available" 2 "Error" 1 "Operational" 0 "Not Operational" ;
VAL_ 2364643838 Module28OperationalStatus 3 "Not Available" 2 "Error" 1 "Operational" 0 "Not Operational" ;
VAL_ 2364643838 Module27OperationalStatus 3 "Not Available" 2 "Error" 1 "Operational" 0 "Not Operational" ;
VAL_ 2364643838 Module26OperationalStatus 3 "Not Available" 2 "Error" 1 "Operational" 0 "Not Operational" ;
VAL_ 2364643838 Module25OperationalStatus 3 "Not Available" 2 "Error" 1 "Operational" 0 "Not Operational" ;
VAL_ 2364643838 Module24OperationalStatus 3 "Not Available" 2 "Error" 1 "Operational" 0 "Not Operational" ;
VAL_ 2364643838 Module23OperationalStatus 3 "Not Available" 2 "Error" 1 "Operational" 0 "Not Operational" ;
VAL_ 2364643838 Module22OperationalStatus 3 "Not Available" 2 "Error" 1 "Operational" 0 "Not Operational" ;
VAL_ 2364643838 Module21OperationalStatus 3 "Not Available" 2 "Error" 1 "Operational" 0 "Not Operational" ;
VAL_ 2364643838 Module20OperationalStatus 3 "Not Available" 2 "Error" 1 "Operational" 0 "Not Operational" ;
VAL_ 2364643838 Module19OperationalStatus 3 "Not Available" 2 "Error" 1 "Operational" 0 "Not Operational" ;
VAL_ 2364643838 Module18OperationalStatus 3 "Not Available" 2 "Error" 1 "Operational" 0 "Not Operational" ;
VAL_ 2364643838 Module17OperationalStatus 3 "Not Available" 2 "Error" 1 "Operational" 0 "Not Operational" ;
VAL_ 2364643838 Module16OperationalStatus 3 "Not Available" 2 "Error" 1 "Operational" 0 "Not Operational" ;
VAL_ 2364643838 Module15OperationalStatus 3 "Not Available" 2 "Error" 1 "Operational" 0 "Not Operational" ;
VAL_ 2364643838 Module14OperationalStatus 3 "Not Available" 2 "Error" 1 "Operational" 0 "Not Operational" ;
VAL_ 2364643838 Module13OperationalStatus 3 "Not Available" 2 "Error" 1 "Operational" 0 "Not Operational" ;
VAL_ 2364643838 Module12OperationalStatus 3 "Not Available" 2 "Error" 1 "Operational" 0 "Not Operational" ;
VAL_ 2364643838 Module11OperationalStatus 3 "Not Available" 2 "Error" 1 "Operational" 0 "Not Operational" ;
VAL_ 2364643838 Module10OperationalStatus 3 "Not Available" 2 "Error" 1 "Operational" 0 "Not Operational" ;
VAL_ 2364643838 Module9OperationalStatus 3 "Not Available" 2 "Error" 1 "Operational" 0 "Not Operational" ;
VAL_ 2364643838 Module8OperationalStatus 3 "Not Available" 2 "Error" 1 "Operational" 0 "Not Operational" ;
VAL_ 2364643838 Module7OperationalStatus 3 "Not Available" 2 "Error" 1 "Operational" 0 "Not Operational" ;
VAL_ 2364643838 Module6OperationalStatus 3 "Not Available" 2 "Error" 1 "Operational" 0 "Not Operational" ;
VAL_ 2364643838 Module5OperationalStatus 3 "Not Available" 2 "Error" 1 "Operational" 0 "Not Operational" ;
VAL_ 2364643838 Module4OperationalStatus 3 "Not Available" 2 "Error" 1 "Operational" 0 "Not Operational" ;
VAL_ 2364643838 Module3OperationalStatus 3 "Not Available" 2 "Error" 1 "Operational" 0 "Not Operational" ;
VAL_ 2364643838 Module2OperationalStatus 3 "Not Available" 2 "Error" 1 "Operational" 0 "Not Operational" ;
VAL_ 2364643838 Module1OperationalStatus 3 "Not Available" 2 "Error" 1 "Operational" 0 "Not Operational" ;
